VERSION ""

NS_ :

BS_:
BU_:

BO_ 858 DI_alertMatrix3: 8 Vector__XXX
   SG_ DI_a129_epbNotApplied : 0|1@1+ (1,0) [0|0] "" Vector__XXX
   SG_ DI_a130_aebFault : 1|1@1+ (1,0) [0|0] "" Vector__XXX
   SG_ DI_a131_highSpeedWearLimit : 2|1@1+ (1,0) [0|0] "" Vector__XXX
   SG_ DI_a133_capacitorOT : 4|1@1+ (1,0) [0|0] "" Vector__XXX
   SG_ DI_a134_wheelSpeedIrrational : 5|1@1+ (1,0) [0|0] "" Vector__XXX
   SG_ DI_a135_vehicleHoldFault : 6|1@1+ (1,0) [0|0] "" Vector__XXX
   SG_ DI_a136_spiError : 7|1@1+ (1,0) [0|0] "" Vector__XXX
   SG_ DI_a137_noCapableDriveUnits : 8|1@1+ (1,0) [0|0] "" Vector__XXX
   SG_ DI_a138_frontUnitDisabled : 9|1@1+ (1,0) [0|0] "" Vector__XXX
   SG_ DI_a139_rearUnitDisabled : 10|1@1+ (1,0) [0|0] "" Vector__XXX
   SG_ DI_a141_dasMIA : 12|1@1+ (1,0) [0|0] "" Vector__XXX
   SG_ DI_a142_highLashAngle : 13|1@1+ (1,0) [0|0] "" Vector__XXX
   SG_ DI_a143_mcuLimitActive : 14|1@1+ (1,0) [0|0] "" Vector__XXX
   SG_ DI_a144_configMismatch : 15|1@1+ (1,0) [0|0] "" Vector__XXX
   SG_ DI_a145_pbrkPanicSkid : 16|1@1+ (1,0) [0|0] "" Vector__XXX
   SG_ DI_a146_pbrkPanicEpbFault : 17|1@1+ (1,0) [0|0] "" Vector__XXX
   SG_ DI_a147_highTorqueWearLimit : 18|1@1+ (1,0) [0|0] "" Vector__XXX
   SG_ DI_a148_overtorqueUsed : 19|1@1+ (1,0) [0|0] "" Vector__XXX
   SG_ DI_a149_oilPumpFailure : 20|1@1+ (1,0) [0|0] "" Vector__XXX
   SG_ DI_a150_busVD : 21|1@1+ (1,0) [0|0] "" Vector__XXX
   SG_ DI_a151_shockTorqueLimiter : 22|1@1+ (1,0) [0|0] "" Vector__XXX
   SG_ DI_a152_linError : 23|1@1+ (1,0) [0|0] "" Vector__XXX
   SG_ DI_a153_oilPump : 24|1@1+ (1,0) [0|0] "" Vector__XXX
   SG_ DI_a154_resolver : 25|1@1+ (1,0) [0|0] "" Vector__XXX
   SG_ DI_a155_vcfrontMIA : 26|1@1+ (1,0) [0|0] "" Vector__XXX
   SG_ DI_a156_currentObserver : 27|1@1+ (1,0) [0|0] "" Vector__XXX
   SG_ DI_a157_rcmMIA : 28|1@1+ (1,0) [0|0] "" Vector__XXX
   SG_ DI_a158_ibstMIA : 29|1@1+ (1,0) [0|0] "" Vector__XXX
   SG_ DI_a159_cruiseSelfCheck : 30|1@1+ (1,0) [0|0] "" Vector__XXX
   SG_ DI_a160_busVoltageAnomaly : 31|1@1+ (1,0) [0|0] "" Vector__XXX
   SG_ DI_a161_epas3pMIA : 32|1@1+ (1,0) [0|0] "" Vector__XXX
   SG_ DI_a162_shiftDenied : 33|1@1+ (1,0) [0|0] "" Vector__XXX
   SG_ DI_a163_unparkReq : 34|1@1+ (1,0) [0|0] "" Vector__XXX
   SG_ DI_a164_brakeOverride : 35|1@1+ (1,0) [0|0] "" Vector__XXX
   SG_ DI_a165_cruiseCancelled : 36|1@1+ (1,0) [0|0] "" Vector__XXX
   SG_ DI_a166_driverLeft : 37|1@1+ (1,0) [0|0] "" Vector__XXX
   SG_ DI_a167_keyNotAuthenticated : 38|1@1+ (1,0) [0|0] "" Vector__XXX
   SG_ DI_a168_proximityDriveDenial : 39|1@1+ (1,0) [0|0] "" Vector__XXX
   SG_ DI_a169_regenOffOverride : 40|1@1+ (1,0) [0|0] "" Vector__XXX
   SG_ DI_a170_pedalFoul : 41|1@1+ (1,0) [0|0] "" Vector__XXX
   SG_ DI_a171_driveRailNotRequested : 42|1@1+ (1,0) [0|0] "" Vector__XXX
   SG_ DI_a172_accelPressedInNP : 43|1@1+ (1,0) [0|0] "" Vector__XXX
   SG_ DI_a173_bothPedalsPressed : 44|1@1+ (1,0) [0|0] "" Vector__XXX
   SG_ DI_a174_notOkToStartDrive : 45|1@1+ (1,0) [0|0] "" Vector__XXX
   SG_ DI_a175_crsNotAvailable : 46|1@1+ (1,0) [0|0] "" Vector__XXX
   SG_ DI_a176_EBRreleased : 47|1@1+ (1,0) [0|0] "" Vector__XXX
   SG_ DI_a177_tireFitmentChanged : 48|1@1+ (1,0) [0|0] "" Vector__XXX
   SG_ DI_a180_crsSeatbeltUnbuckled : 51|1@1+ (1,0) [0|0] "" Vector__XXX
   SG_ DI_a181_rearMotorMode : 52|1@1+ (1,0) [0|0] "" Vector__XXX
   SG_ DI_a182_frontMotorMode : 53|1@1+ (1,0) [0|0] "" Vector__XXX
   SG_ DI_a183_holdReleaseRqrd : 54|1@1+ (1,0) [0|0] "" Vector__XXX
   SG_ DI_a184_autoparkCanceled : 55|1@1+ (1,0) [0|0] "" Vector__XXX
   SG_ DI_a185_autoparkAborted : 56|1@1+ (1,0) [0|0] "" Vector__XXX
   SG_ DI_a186_brakeStand : 57|1@1+ (1,0) [0|0] "" Vector__XXX
   SG_ DI_a187_pedalMisapplication : 58|1@1+ (1,0) [0|0] "" Vector__XXX
   SG_ DI_a189_garageShiftWithPedal : 60|1@1+ (1,0) [0|0] "" Vector__XXX
   SG_ DI_a191_brakeShiftReq : 62|1@1+ (1,0) [0|0] "" Vector__XXX
   SG_ DI_a192_invalidOdometer : 63|1@1+ (1,0) [0|0] "" Vector__XXX

BO_ 859 DI_alertMatrix4: 8 Vector__XXX
   SG_ DI_a193_vdcEspBrakeTorqueFr : 0|1@1+ (1,0) [0|0] "" Vector__XXX
   SG_ DI_a194_vdcEspBrakeTorqueRe : 1|1@1+ (1,0) [0|0] "" Vector__XXX
   SG_ DI_a195_vdcEspSlipFr : 2|1@1+ (1,0) [0|0] "" Vector__XXX
   SG_ DI_a196_vdcEspSlipRe : 3|1@1+ (1,0) [0|0] "" Vector__XXX
   SG_ DI_a197_vdcEspWheelSaturations : 4|1@1+ (1,0) [0|0] "" Vector__XXX
   SG_ DI_a198_vdcEspMCPressAndSteering : 5|1@1+ (1,0) [0|0] "" Vector__XXX
   SG_ DI_a199_vdcFaulted : 6|1@1+ (1,0) [0|0] "" Vector__XXX
   SG_ DI_a200_vdcModelBasedPlausibility : 7|1@1+ (1,0) [0|0] "" Vector__XXX
   SG_ DI_a201_regenLimited : 8|1@1+ (1,0) [0|0] "" Vector__XXX
   SG_ DI_a202_excessHeatUnavailable : 9|1@1+ (1,0) [0|0] "" Vector__XXX
   SG_ DI_a203_TCReducedByADD : 10|1@1+ (1,0) [0|0] "" Vector__XXX
   SG_ DI_a204_vdcRcmLongitudinal : 11|1@1+ (1,0) [0|0] "" Vector__XXX
   SG_ DI_a205_vdcRcmLateral : 12|1@1+ (1,0) [0|0] "" Vector__XXX
   SG_ DI_a206_vdcRcmVertical : 13|1@1+ (1,0) [0|0] "" Vector__XXX
   SG_ DI_a207_vdcPowertrainTorqueFr : 14|1@1+ (1,0) [0|0] "" Vector__XXX
   SG_ DI_a208_vdcPowertrainTorqueRe : 15|1@1+ (1,0) [0|0] "" Vector__XXX
   SG_ DI_a209_vdcVehicleSpeed : 16|1@1+ (1,0) [0|0] "" Vector__XXX
   SG_ DI_a210_vdcOtherControllerStates : 17|1@1+ (1,0) [0|0] "" Vector__XXX
   SG_ DI_a211_vdcMotorSpeeds : 18|1@1+ (1,0) [0|0] "" Vector__XXX
   SG_ DI_a212_velEstWheelSpeedCGFr : 19|1@1+ (1,0) [0|0] "" Vector__XXX
   SG_ DI_a213_velEstWheelSpeedCGRe : 20|1@1+ (1,0) [0|0] "" Vector__XXX
   SG_ DI_a214_velEstWheelSpeedNonCGFr : 21|1@1+ (1,0) [0|0] "" Vector__XXX
   SG_ DI_a215_velEstWheelSpeedNonCGRe : 22|1@1+ (1,0) [0|0] "" Vector__XXX
   SG_ DI_a216_vdcMBPAlmostTripped : 23|1@1+ (1,0) [0|0] "" Vector__XXX
   SG_ DI_a217_vdcOutputIrrational : 24|1@1+ (1,0) [0|0] "" Vector__XXX
   SG_ DI_a218_vdcOSPreControlActive : 25|1@1+ (1,0) [0|0] "" Vector__XXX
   SG_ DI_a219_vdcOversteerdMzActive : 26|1@1+ (1,0) [0|0] "" Vector__XXX
   SG_ DI_a220_vdcUndersteerDecelActive : 27|1@1+ (1,0) [0|0] "" Vector__XXX
   SG_ DI_a221_vdcUndersteerdMzActive : 28|1@1+ (1,0) [0|0] "" Vector__XXX
   SG_ DI_a222_vdcDisabled : 29|1@1+ (1,0) [0|0] "" Vector__XXX
   SG_ DI_a223_tractionControlDisabled : 30|1@1+ (1,0) [0|0] "" Vector__XXX
   SG_ DI_a224_brakeOverTemp : 31|1@1+ (1,0) [0|0] "" Vector__XXX
   SG_ DI_a225_tmpEstPlausibility : 32|1@1+ (1,0) [0|0] "" Vector__XXX
   SG_ DI_a226_sysStartConditionNotMet : 33|1@1+ (1,0) [0|0] "" Vector__XXX
   SG_ DI_a227_contactorsNotClosed : 34|1@1+ (1,0) [0|0] "" Vector__XXX
   SG_ DI_a228_brakeTempEstUnavailable : 35|1@1+ (1,0) [0|0] "" Vector__XXX
   SG_ DI_a229_batteryIsHeating : 36|1@1+ (1,0) [0|0] "" Vector__XXX
   SG_ DI_a230_cmpMIA : 37|1@1+ (1,0) [0|0] "" Vector__XXX
   SG_ DI_a231_ptcMIA : 38|1@1+ (1,0) [0|0] "" Vector__XXX
   SG_ DI_a232_velocityEstimatorDegraded : 39|1@1+ (1,0) [0|0] "" Vector__XXX
   SG_ DI_a233_diMsgMissed : 40|1@1+ (1,0) [0|0] "" Vector__XXX
   SG_ DI_a234_pcsMIA : 41|1@1+ (1,0) [0|0] "" Vector__XXX
   SG_ DI_a235_trackModeActive : 42|1@1+ (1,0) [0|0] "" Vector__XXX
   SG_ DI_a238_brakeOverTempBrembo : 45|1@1+ (1,0) [0|0] "" Vector__XXX
   SG_ DI_a239_neutralRequestByPM : 46|1@1+ (1,0) [0|0] "" Vector__XXX
   SG_ DI_a241_systemThermallyLimited : 48|1@1+ (1,0) [0|0] "" Vector__XXX

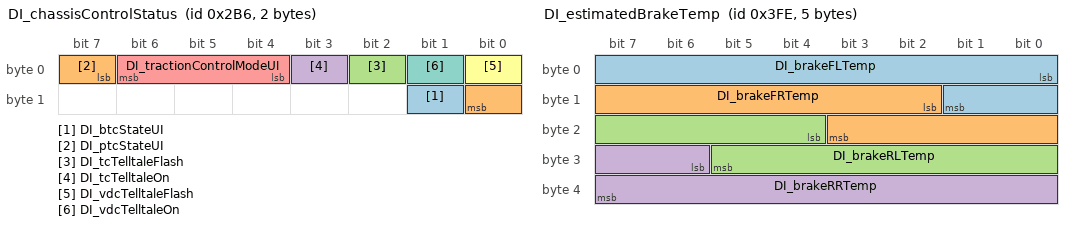
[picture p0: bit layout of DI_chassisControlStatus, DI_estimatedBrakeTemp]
BO_ 694 DI_chassisControlStatus: 2 Vector__XXX
   SG_ DI_btcStateUI : 9|1@1+ (1,0) [0|0] "" Vector__XXX
   SG_ DI_ptcStateUI : 7|2@1+ (1,0) [0|0] "" Vector__XXX
   SG_ DI_tcTelltaleFlash : 2|1@1+ (1,0) [0|0] "" Vector__XXX
   SG_ DI_tcTelltaleOn : 3|1@1+ (1,0) [0|0] "" Vector__XXX
   SG_ DI_tractionControlModeUI : 4|3@1+ (1,0) [0|0] "" Vector__XXX
   SG_ DI_vdcTelltaleFlash : 0|1@1+ (1,0) [0|0] "" Vector__XXX
   SG_ DI_vdcTelltaleOn : 1|1@1+ (1,0) [0|0] "" Vector__XXX

BO_ 1879 DI_debug: 8 Vector__XXX
   SG_ DI_debugSelector M : 0|8@1+ (1,0) [0|0] "" Vector__XXX
   SG_ DI_motorType m128 : 8|5@1+ (1,0) [0|0] "" Vector__XXX
   SG_ DI_cpu1HzMin m128 : 16|8@1+ (0.4,0) [0|0] "%" Vector__XXX
   SG_ DI_cpu1HzMax m128 : 24|8@1+ (0.4,0) [0|0] "%" Vector__XXX
   SG_ DI_cpu1HzAvg m128 : 32|8@1+ (0.4,0) [0|0] "%" Vector__XXX
   SG_ DI_muSurfHigh m2 : 8|8@1+ (0.005,0) [0|0] "N/N" Vector__XXX
   SG_ DI_brakeCpScale m2 : 16|9@1- (0.01,0.5) [0|0] "N/N" Vector__XXX
   SG_ DI_pedalPosFilt m2 : 32|8@1+ (0.4,0) [0|0] "%" Vector__XXX
   SG_ DI_cpuIDWord0 m131 : 16|16@1+ (1,0) [0|0] "" Vector__XXX
   SG_ DI_crc m131 : 32|32@1+ (1,0) [0|0] "" Vector__XXX
   SG_ DI_cpuIDWord1 m132 : 16|16@1+ (1,0) [0|0] "" Vector__XXX
   SG_ DI_cpuIDWord2 m132 : 32|16@1+ (1,0) [0|0] "" Vector__XXX
   SG_ DI_cpuIDWord3 m132 : 48|16@1+ (1,0) [0|0] "" Vector__XXX
   SG_ DI_offsetA m32 : 8|8@1- (0.1,0) [0|0] "A" Vector__XXX
   SG_ DI_motorIA m32 : 16|16@1+ (0.1,0) [0|0] "A" Vector__XXX
   SG_ DI_motorIB m32 : 32|16@1+ (0.1,0) [0|0] "A" Vector__XXX
   SG_ DI_motorIC m32 : 48|16@1+ (0.1,0) [0|0] "A" Vector__XXX
   SG_ DI_offsetB m33 : 8|8@1- (0.1,0) [0|0] "A" Vector__XXX
   SG_ DI_statorIDref m33 : 16|16@1- (0.1,0) [0|0] "A" Vector__XXX
   SG_ DI_statorIDfdb m33 : 32|16@1- (0.1,0) [0|0] "A" Vector__XXX
   SG_ DI_torquePerAmp m33 : 48|16@1+ (0.0001,0) [0|0] "Nm/A" Vector__XXX
   SG_ DI_rsScale m34 : 8|8@1+ (0.01,0) [0|0] "scale" Vector__XXX
   SG_ DI_statorIQref m34 : 16|16@1- (0.1,0) [0|0] "A" Vector__XXX
   SG_ DI_statorIQfdb m34 : 32|16@1- (0.1,0) [0|0] "A" Vector__XXX
   SG_ DI_motorV m34 : 48|16@1+ (2e-05,0) [0|0] "mindex" Vector__XXX
   SG_ DI_tqScaleDifferential m35 : 8|8@1+ (0.4,0) [0|0] "%" Vector__XXX
   SG_ DI_statorFluxRef m35 : 16|16@1+ (0.0001,0) [0|0] "Wb" Vector__XXX
   SG_ DI_statorFluxFdb m35 : 32|16@1+ (0.0001,0) [0|0] "Wb" Vector__XXX
   SG_ DI_systemTorqueCommand m35 : 48|16@1- (0.035,0) [0|0] "Nm" Vector__XXX
   SG_ DI_lmScale m36 : 8|8@1+ (0.004,0) [0|0] "scale" Vector__XXX
   SG_ DI_statorVQ m36 : 16|16@1- (4e-05,0) [0|0] "mindex" Vector__XXX
   SG_ DI_statorVD m36 : 32|16@1- (4e-05,0) [0|0] "mindex" Vector__XXX
   SG_ DI_peakFlux m36 : 48|16@1+ (0.0001,0) [0|0] "Wb" Vector__XXX
   SG_ DI_gainScale m37 : 8|8@1+ (0.01,0) [0|0] "scale" Vector__XXX
   SG_ DI_dcCableCurrentEst m37 : 16|16@1- (0.1,0) [0|0] "A" Vector__XXX
   SG_ DI_loadAngleMargin m37 : 32|16@1- (0.0003,0) [0|0] "rad" Vector__XXX
   SG_ DI_internalAngleFilt m37 : 48|16@1+ (0.0003,0) [0|0] "rad" Vector__XXX
   SG_ DI_ssmState m38 : 8|4@1+ (1,0) [0|0] "" Vector__XXX
   SG_ DI_usmState m38 : 12|3@1+ (1,0) [0|0] "" Vector__XXX
   SG_ DI_peakIQref m38 : 16|16@1+ (0.1,0) [0|0] "A" Vector__XXX
   SG_ DI_motorIAavg m38 : 32|16@1- (0.1,0) [0|0] "A" Vector__XXX
   SG_ DI_motorIBavg m38 : 48|16@1- (0.1,0) [0|0] "A" Vector__XXX
   SG_ DI_tqSatThermal m39 : 8|8@1+ (0.4,0) [0|0] "%" Vector__XXX
   SG_ DI_pwrSatMaxDischargePower m39 : 16|8@1+ (0.4,0) [0|0] "%" Vector__XXX
   SG_ DI_pwrSatMaxRegenPower m39 : 24|8@1+ (0.4,0) [0|0] "%" Vector__XXX
   SG_ DI_tqSatMotorVoltage m39 : 32|8@1+ (0.4,0) [0|0] "%" Vector__XXX
   SG_ DI_tqSatMotorCurrent m39 : 40|8@1+ (0.4,0) [0|0] "%" Vector__XXX
   SG_ DI_pwrSatMaxBusVoltage m39 : 48|8@1+ (0.4,0) [0|0] "%" Vector__XXX
   SG_ DI_pwrSatMinBusVoltage m39 : 56|8@1+ (0.4,0) [0|0] "%" Vector__XXX
   SG_ DI_pwrSatDischargeCurrent m40 : 8|8@1+ (0.4,0) [0|0] "%" Vector__XXX
   SG_ DI_tcMaxRequest m40 : 16|8@1+ (5,0) [0|0] "Nm" Vector__XXX
   SG_ DI_tcMinRequest m40 : 24|8@1+ (5,0) [0|0] "Nm" Vector__XXX
   SG_ DI_tqSatUiDriveTorque m40 : 32|8@1+ (0.4,0) [0|0] "%" Vector__XXX
   SG_ DI_tqSatUiRegenTorque m40 : 40|8@1+ (0.4,0) [0|0] "%" Vector__XXX
   SG_ DI_tqScaleMaxMotorSpeed m40 : 48|8@1+ (0.4,0) [0|0] "%" Vector__XXX
   SG_ DI_tqScaleShift m40 : 56|8@1+ (0.4,0) [0|0] "%" Vector__XXX
   SG_ DI_veMassInvRaw m41 : 8|12@1+ (1e-07,0.0001) [0|0] "1/kg" Vector__XXX
   SG_ DI_veResForce m41 : 20|12@1- (0.0005,0) [0|0] "G" Vector__XXX
   SG_ DI_currentLimit m41 : 32|16@1+ (0.1,0) [0|0] "A" Vector__XXX
   SG_ DI_wasteCurrentLimit m41 : 48|16@1+ (0.1,0) [0|0] "A" Vector__XXX
   SG_ DI_pwrSatChargeCurrent m42 : 8|8@1+ (0.4,0) [0|0] "%" Vector__XXX
   SG_ DI_fluxState m42 : 16|4@1+ (1,0) [0|0] "" Vector__XXX
   SG_ DI_llsScale m42 : 24|8@1+ (0.004,0) [0|0] "scale" Vector__XXX
   SG_ DI_llrScale m42 : 32|8@1+ (0.015,0) [0|0] "scale" Vector__XXX
   SG_ DI_loadAngle m42 : 40|16@1- (0.0003,0) [0|0] "rad" Vector__XXX
   SG_ DI_brakeSwitchNO m42 : 62|1@1+ (1,0) [0|0] "" Vector__XXX
   SG_ DI_brakeSwitchNC m42 : 63|1@1+ (1,0) [0|0] "" Vector__XXX
   SG_ DI_sysPedalMinTorque m44 : 8|14@1+ (0.1,-1638.3) [0|0] "Nm" Vector__XXX
   SG_ DI_sysPedalMaxTorque m44 : 22|14@1+ (0.1,0) [0|0] "Nm" Vector__XXX
   SG_ DI_sysPostPedalMinTorque m44 : 36|14@1+ (0.1,-1638.3) [0|0] "Nm" Vector__XXX
   SG_ DI_sysPostPedalMaxTorque m44 : 50|14@1+ (0.1,0) [0|0] "Nm" Vector__XXX
   SG_ DI_aebFaultReason m45 : 16|4@1+ (1,0) [0|0] "" Vector__XXX
   SG_ DI_aebUnavailableReason m45 : 24|4@1+ (1,0) [0|0] "" Vector__XXX
   SG_ DI_aebCancelReason m45 : 32|8@1+ (1,0) [0|0] "" Vector__XXX
   SG_ DI_oilPumpPhaseCurrent m46 : 8|8@1+ (0.1,0) [0|0] "A" Vector__XXX
   SG_ DI_oilPumpPhaseVoltage m46 : 16|8@1+ (0.1,0) [0|0] "V" Vector__XXX
   SG_ DI_oilPumpPhaseAdvance m46 : 24|8@1+ (0.4,0) [0|0] "%" Vector__XXX
   SG_ DI_oilPumpPressureEstimate m46 : 32|8@1+ (2,0) [0|0] "kPa" Vector__XXX
   SG_ DI_rotorFlux m47 : 16|16@1+ (0.0001,0) [0|0] "Wb" Vector__XXX
   SG_ DI_dcCableHeat m47 : 32|16@1+ (0.001,0) [0|0] "kA2s" Vector__XXX
   SG_ DI_magnetTempEst m47 : 48|8@1+ (1,-40) [0|0] "DegC" Vector__XXX
   SG_ DI_magnetTempEst_SFO m47 : 56|8@1+ (1,-40) [0|0] "DegC" Vector__XXX
   SG_ DI_resolverOffsetCos m48 : 8|8@1+ (0.015,0) [0|0] "V" Vector__XXX
   SG_ DI_resolverOffsetSin m48 : 16|8@1+ (0.015,0) [0|0] "V" Vector__XXX
   SG_ DI_resolverPhaseOffset m48 : 24|8@1+ (0.1,7.5) [0|0] "us" Vector__XXX
   SG_ DI_resolverCommonGain m48 : 32|8@1+ (0.025,0) [0|0] "1" Vector__XXX
   SG_ DI_resolverReady m48 : 40|1@1+ (1,0) [0|0] "" Vector__XXX
   SG_ DI_resolverNoCarrier m48 : 41|1@1+ (1,0) [0|0] "" Vector__XXX
   SG_ DI_resolverNoPhaseLock m48 : 42|1@1+ (1,0) [0|0] "" Vector__XXX
   SG_ DI_resolverClaMIA m48 : 43|1@1+ (1,0) [0|0] "" Vector__XXX
   SG_ DI_soptTimeToTrip m49 : 8|8@1+ (0.05,0) [0|0] "ms" Vector__XXX
   SG_ DI_soptTripDelay m49 : 16|8@1+ (0.05,0) [0|0] "ms" Vector__XXX
   SG_ DI_soptTimeToOff m49 : 24|11@1+ (0.05,0) [0|0] "ms" Vector__XXX
   SG_ DI_soptMaxCurrentMagSqrd m49 : 40|16@1+ (100,0) [0|0] "A2" Vector__XXX
   SG_ DI_gateDriveSupplyState m50 : 8|2@1+ (1,0) [0|0] "" Vector__XXX
   SG_ DI_gateDriveState m50 : 10|3@1+ (1,0) [0|0] "" Vector__XXX
   SG_ DI_powerStageSafeState m50 : 13|2@1+ (1,0) [0|0] "" Vector__XXX
   SG_ DI_sysHeatPowerOptimal m50 : 16|8@1+ (0.08,0) [0|0] "kW" Vector__XXX
   SG_ DI_brkStState m50 : 24|3@1+ (1,0) [0|0] "" Vector__XXX
   SG_ DI_torquePedalMin m51 : 16|12@1+ (2,-7500) [0|0] "Nm" Vector__XXX
   SG_ DI_torquePedalMax m51 : 28|12@1+ (2,0) [0|0] "Nm" Vector__XXX
   SG_ DI_torquePostPedalMin m51 : 40|12@1+ (2,-7500) [0|0] "Nm" Vector__XXX
   SG_ DI_torquePostPedalMax m51 : 52|12@1+ (2,0) [0|0] "Nm" Vector__XXX
   SG_ DI_dcCapTemp m64 : 8|8@1+ (1,-40) [0|0] "DegC" Vector__XXX
   SG_ DI_busbarTemp m64 : 16|8@1+ (1,-40) [0|0] "DegC" Vector__XXX
   SG_ DI_pcsTemp m64 : 24|8@1+ (1,-40) [0|0] "DegC" Vector__XXX
   SG_ DI_statorTemp1 m64 : 32|8@1+ (1,-40) [0|0] "DegC" Vector__XXX
   SG_ DI_statorTemp2 m64 : 40|8@1+ (1,-40) [0|0] "DegC" Vector__XXX
   SG_ DI_immobilizerCondition m64 : 63|1@1+ (1,0) [0|0] "" Vector__XXX
   SG_ DI_velocityEstimatorState m65 : 8|3@1+ (1,0) [0|0] "" Vector__XXX
   SG_ DI_hvilCurrent m65 : 16|10@1+ (0.025,0) [0|0] "mA" Vector__XXX
   SG_ DI_hvilCmVoltage m65 : 32|10@1+ (0.02,0) [0|0] "V" Vector__XXX
   SG_ DI_cpu10HzMin m66 : 8|8@1+ (0.4,0) [0|0] "%" Vector__XXX
   SG_ DI_cpu10HzMax m66 : 16|8@1+ (0.4,0) [0|0] "%" Vector__XXX
   SG_ DI_cpu10HzAvg m66 : 24|8@1+ (0.4,0) [0|0] "%" Vector__XXX
   SG_ DI_cpu100HzMin m66 : 32|8@1+ (0.4,0) [0|0] "%" Vector__XXX
   SG_ DI_cpu100HzMax m66 : 40|8@1+ (0.4,0) [0|0] "%" Vector__XXX
   SG_ DI_cpu100HzAvg m66 : 48|8@1+ (0.4,0) [0|0] "%" Vector__XXX
   SG_ DI_module10HzStack m66 : 56|8@1+ (0.4,0) [0|0] "%" Vector__XXX
   SG_ DI_cpu1kHzMin m67 : 8|8@1+ (0.4,0) [0|0] "%" Vector__XXX
   SG_ DI_cpu1kHzMax m67 : 16|8@1+ (0.4,0) [0|0] "%" Vector__XXX
   SG_ DI_cpu1kHzAvg m67 : 24|8@1+ (0.4,0) [0|0] "%" Vector__XXX
   SG_ DI_cpu20kHzMin m67 : 32|8@1+ (0.4,0) [0|0] "%" Vector__XXX
   SG_ DI_cpu20kHzMax m67 : 40|8@1+ (0.4,0) [0|0] "%" Vector__XXX
   SG_ DI_cpu20kHzAvg m67 : 48|8@1+ (0.4,0) [0|0] "%" Vector__XXX
   SG_ DI_controlStack m67 : 56|8@1+ (0.4,0) [0|0] "%" Vector__XXX
   SG_ DI_systemStack m68 : 8|8@1+ (0.4,0) [0|0] "%" Vector__XXX
   SG_ DI_idleStack m68 : 16|8@1+ (0.4,0) [0|0] "%" Vector__XXX
   SG_ DI_decodeHardwareStack m68 : 24|8@1+ (0.4,0) [0|0] "%" Vector__XXX
   SG_ DI_eepromStack m68 : 32|8@1+ (0.4,0) [0|0] "%" Vector__XXX
   SG_ DI_udsStack m68 : 40|8@1+ (0.4,0) [0|0] "%" Vector__XXX
   SG_ DI_xcpStack m68 : 48|8@1+ (0.4,0) [0|0] "%" Vector__XXX
   SG_ DI_immobilizerStack m68 : 56|8@1+ (0.4,0) [0|0] "%" Vector__XXX
   SG_ DI_hwFaultCounter m69 : 8|4@1+ (1,0) [0|0] "" Vector__XXX
   SG_ DI_driveUnitOdometer m69 : 32|32@1+ (10,0) [0|0] "rev" Vector__XXX
   SG_ DI_phaseOutBusbarTemp m70 : 8|8@1+ (1,-40) [0|0] "DegC" Vector__XXX
   SG_ DI_phaseOutBusbarWeldTemp m70 : 16|8@1+ (1,-40) [0|0] "DegC" Vector__XXX
   SG_ DI_phaseOutLugTemp m70 : 24|8@1+ (1,-40) [0|0] "DegC" Vector__XXX
   SG_ DI_dcLinkCapTemp m70 : 32|8@1+ (1,-40) [0|0] "DegC" Vector__XXX
   SG_ DI_hvDcCableTemp m70 : 40|8@1+ (1,-40) [0|0] "DegC" Vector__XXX
   SG_ DI_negDcBusbarTemp m70 : 48|8@1+ (1,-40) [0|0] "DegC" Vector__XXX
   SG_ DI_posDcBusbarTemp m70 : 56|8@1+ (1,-40) [0|0] "DegC" Vector__XXX
   SG_ DI_statorEndWindingTemp m72 : 8|8@1+ (1,-40) [0|0] "DegC" Vector__XXX
   SG_ DI_rotorMaxMagnetTemp m72 : 16|8@1+ (1,-40) [0|0] "DegC" Vector__XXX

BO_ 1880 DI_dyno: 8 Vector__XXX
   SG_ DI_dynoSelector M : 0|8@1+ (1,0) [0|0] "" Vector__XXX
   SG_ DI_Isx m0 : 16|16@1+ (1.5259e-05,0) [0|0] "A" Vector__XXX
   SG_ DI_Isy m0 : 32|16@1+ (1.5259e-05,0) [0|0] "A" Vector__XXX
   SG_ DI_IsMag m0 : 48|16@1- (0.1,0) [0|0] "A" Vector__XXX
   SG_ DI_Vsx m1 : 16|16@1- (4e-05,0) [0|0] "mindex" Vector__XXX
   SG_ DI_Vsy m1 : 32|16@1- (4e-05,0) [0|0] "mindex" Vector__XXX
   SG_ DI_voltageForFlux m1 : 48|16@1+ (0.00762951,0) [0|0] "V" Vector__XXX
   SG_ DI_torqueMotor m2 : 16|13@1- (0.25,0) [0|0] "Nm" Vector__XXX
   SG_ DI_state m2 : 29|3@1+ (1,0) [0|0] "" Vector__XXX
   SG_ DI_motorRPM m2 : 32|16@1- (1,0) [0|0] "RPM" Vector__XXX
   SG_ DI_torqueEstimate m2 : 48|13@1- (0.25,0) [0|0] "Nm" Vector__XXX
   SG_ DI_pedalMinTorque m32 : 8|12@1+ (0.25,-750) [0|0] "Nm" Vector__XXX
   SG_ DI_pedalMaxTorque m32 : 20|12@1+ (0.25,0) [0|0] "Nm" Vector__XXX
   SG_ DI_postPedalMinTorque m32 : 32|12@1+ (0.25,-750) [0|0] "Nm" Vector__XXX
   SG_ DI_postPedalMaxTorque m32 : 44|12@1+ (0.25,0) [0|0] "Nm" Vector__XXX
   SG_ DI_slipEstimate m33 : 8|10@1- (0.02,0) [0|0] "Hz" Vector__XXX
   SG_ DI_mechToElcFactor m64 : 8|4@1- (1,0) [0|0] "" Vector__XXX

BO_ 1022 DI_estimatedBrakeTemp: 5 Vector__XXX
   SG_ DI_brakeFLTemp : 0|10@1+ (1,-40) [0|0] "DegC" Vector__XXX
   SG_ DI_brakeFRTemp : 10|10@1+ (1,-40) [0|0] "DegC" Vector__XXX
   SG_ DI_brakeRLTemp : 20|10@1+ (1,-40) [0|0] "DegC" Vector__XXX
   SG_ DI_brakeRRTemp : 30|10@1+ (1,-40) [0|0] "DegC" Vector__XXX

BO_ 1622 DI_info: 8 Vector__XXX
   SG_ DI_infoIndex M : 0|8@1+ (1,0) [0|0] "" Vector__XXX
   SG_ DI_buildType m10 : 8|3@1+ (1,0) [0|0] "" Vector__XXX
   SG_ DI_buildConfigurationId m10 : 16|16@1+ (1,0) [0|0] "" Vector__XXX
   SG_ DI_hardwareId m10 : 32|8@1+ (1,0) [0|0] "" Vector__XXX
   SG_ DI_componentId m10 : 48|16@1+ (1,0) [0|0] "" Vector__XXX
   SG_ DI_pcbaId m11 : 16|8@1+ (1,0) [0|0] "" Vector__XXX
   SG_ DI_assemblyId m11 : 24|8@1+ (1,0) [0|0] "" Vector__XXX
   SG_ DI_usageId m11 : 32|16@1+ (1,0) [0|0] "" Vector__XXX
   SG_ DI_subUsageId m11 : 48|16@1+ (1,0) [0|0] "" Vector__XXX
   SG_ DI_applicationSvnRevision m12 : 8|24@1+ (1,0) [0|0] "" Vector__XXX
   SG_ DI_applicationSvnUrlHash m12 : 32|32@1+ (1,0) [0|0] "" Vector__XXX
   SG_ DI_applicationCrc m13 : 32|32@1+ (1,0) [0|0] "" Vector__XXX
   SG_ DI_bootloaderSvnRevision m14 : 8|24@1+ (1,0) [0|0] "" Vector__XXX
   SG_ DI_bootloaderSvnUrlHash m14 : 32|32@1+ (1,0) [0|0] "" Vector__XXX
   SG_ DI_oilPumpBuildType m16 : 8|3@1+ (1,0) [0|0] "" Vector__XXX
   SG_ DI_oilPumpAppCrc m16 : 16|32@1+ (1,0) [0|0] "" Vector__XXX
   SG_ DI_appGitHash m17 : 10|54@1+ (4,0) [0|0] "" Vector__XXX
   SG_ DI_bootGitHash m18 : 10|54@1+ (4,0) [0|0] "" Vector__XXX
   SG_ DI_platformTyp m19 : 8|8@1+ (1,0) [0|0] "" Vector__XXX
   SG_ DI_infoBootLdUdsProtocolVersion m20 : 8|8@1+ (1,0) [0|0] "" Vector__XXX
   SG_ DI_bootloaderCrc m20 : 32|32@1+ (1,0) [0|0] "" Vector__XXX
   SG_ DI_subcomponentGitHash m31 : 10|54@1+ (4,0) [0|0] "" Vector__XXX

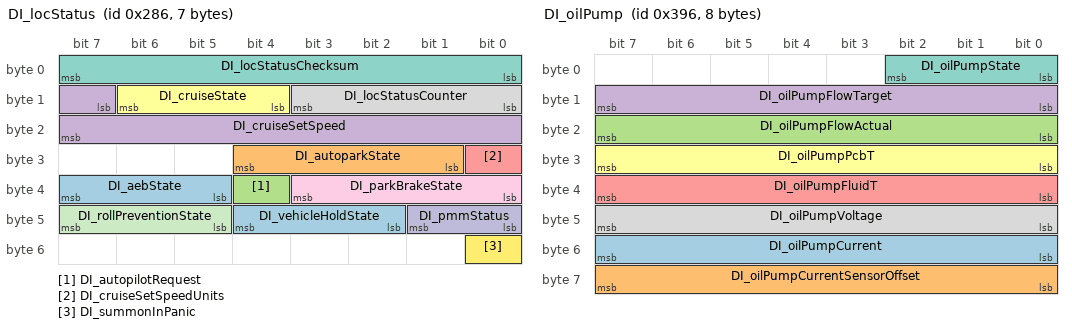
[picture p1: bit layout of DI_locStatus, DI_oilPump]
BO_ 646 DI_locStatus: 7 Vector__XXX
   SG_ DI_aebState : 37|3@1+ (1,0) [0|0] "" Vector__XXX
   SG_ DI_autoparkState : 25|4@1+ (1,0) [0|0] "" Vector__XXX
   SG_ DI_autopilotRequest : 36|1@1+ (1,0) [0|0] "" Vector__XXX
   SG_ DI_cruiseSetSpeed : 15|9@1+ (0.5,0) [0|0] "speed" Vector__XXX
   SG_ DI_cruiseSetSpeedUnits : 24|1@1+ (1,0) [0|0] "" Vector__XXX
   SG_ DI_cruiseState : 12|3@1+ (1,0) [0|0] "" Vector__XXX
   SG_ DI_locStatusChecksum : 0|8@1+ (1,0) [0|0] "" Vector__XXX
   SG_ DI_locStatusCounter : 8|4@1+ (1,0) [0|0] "" Vector__XXX
   SG_ DI_parkBrakeState : 32|4@1+ (1,0) [0|0] "" Vector__XXX
   SG_ DI_pmmStatus : 40|2@1+ (1,0) [0|0] "" Vector__XXX
   SG_ DI_rollPreventionState : 45|3@1+ (1,0) [0|0] "" Vector__XXX
   SG_ DI_summonInPanic : 48|1@1+ (1,0) [0|0] "" Vector__XXX
   SG_ DI_vehicleHoldState : 42|3@1+ (1,0) [0|0] "" Vector__XXX

BO_ 822 DI_maxRatedPower: 3 Vector__XXX
   SG_ DI_sysDrivePowerRated : 0|9@1+ (1,0) [0|0] "kW" Vector__XXX
   SG_ DI_sysRegenPowerRated : 16|8@1+ (1,-100) [0|0] "kW" Vector__XXX

BO_ 950 DI_odometerStatus: 4 Vector__XXX
   SG_ DI_odometer : 0|32@1+ (0.001,0) [0|0] "km" Vector__XXX

BO_ 918 DI_oilPump: 8 Vector__XXX
   SG_ DI_oilPumpCurrent : 48|8@1+ (0.1,0) [0|0] "A" Vector__XXX
   SG_ DI_oilPumpCurrentSensorOffset : 56|8@1+ (0.005,0) [0|0] "A" Vector__XXX
   SG_ DI_oilPumpFlowActual : 16|8@1+ (0.06,0) [0|0] "LPM" Vector__XXX
   SG_ DI_oilPumpFlowTarget : 8|8@1+ (0.06,0) [0|0] "LPM" Vector__XXX
   SG_ DI_oilPumpFluidT : 32|8@1+ (1,-40) [0|0] "DegC" Vector__XXX
   SG_ DI_oilPumpPcbT : 24|8@1+ (1,-40) [0|0] "DegC" Vector__XXX
   SG_ DI_oilPumpState : 0|3@1+ (1,0) [0|0] "" Vector__XXX
   SG_ DI_oilPumpVoltage : 40|8@1+ (0.1,0) [0|0] "V" Vector__XXX

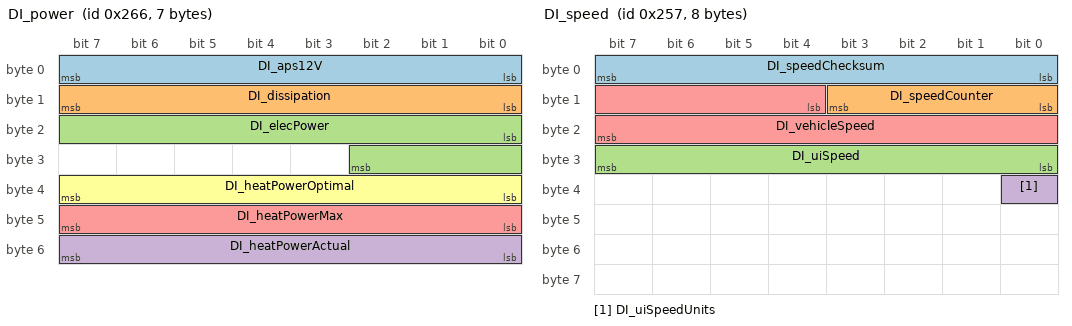
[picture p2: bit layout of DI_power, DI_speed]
BO_ 614 DI_power: 7 Vector__XXX
   SG_ DI_aps12V : 0|8@1+ (0.1,0) [0|0] "V" Vector__XXX
   SG_ DI_dissipation : 8|8@1+ (125,0) [0|0] "W" Vector__XXX
   SG_ DI_elecPower : 16|11@1- (0.5,0) [0|0] "kW" Vector__XXX
   SG_ DI_heatPowerActual : 48|8@1+ (0.08,0) [0|0] "kW" Vector__XXX
   SG_ DI_heatPowerMax : 40|8@1+ (0.08,0) [0|0] "kW" Vector__XXX
   SG_ DI_heatPowerOptimal : 32|8@1+ (0.08,0) [0|0] "kW" Vector__XXX

BO_ 599 DI_speed: 8 Vector__XXX
   SG_ DI_speedChecksum : 0|8@1+ (1,0) [0|0] "" Vector__XXX
   SG_ DI_speedCounter : 8|4@1+ (1,0) [0|0] "" Vector__XXX
   SG_ DI_uiSpeed : 24|8@1+ (1,0) [0|0] "" Vector__XXX
   SG_ DI_uiSpeedUnits : 32|1@1+ (1,0) [0|0] "" Vector__XXX
   SG_ DI_vehicleSpeed : 12|12@1+ (0.08,-40) [0|0] "kph" Vector__XXX

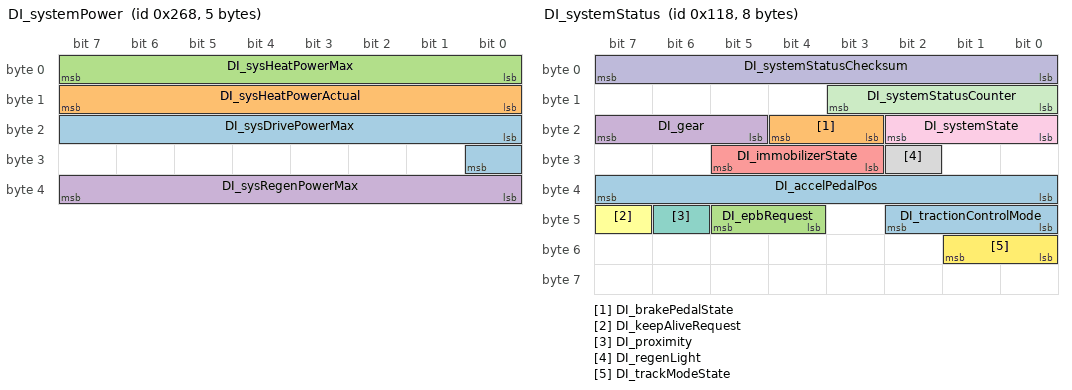
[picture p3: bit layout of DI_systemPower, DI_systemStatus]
BO_ 616 DI_systemPower: 5 Vector__XXX
   SG_ DI_sysDrivePowerMax : 16|9@1+ (1,0) [0|0] "kW" Vector__XXX
   SG_ DI_sysHeatPowerActual : 8|8@1+ (0.08,0) [0|0] "kW" Vector__XXX
   SG_ DI_sysHeatPowerMax : 0|8@1+ (0.08,0) [0|0] "kW" Vector__XXX
   SG_ DI_sysRegenPowerMax : 32|8@1+ (1,-100) [0|0] "kW" Vector__XXX

BO_ 280 DI_systemStatus: 8 Vector__XXX
   SG_ DI_accelPedalPos : 32|8@1+ (0.4,0) [0|0] "%" Vector__XXX
   SG_ DI_brakePedalState : 19|2@1+ (1,0) [0|0] "" Vector__XXX
   SG_ DI_epbRequest : 44|2@1+ (1,0) [0|0] "" Vector__XXX
   SG_ DI_gear : 21|3@1+ (1,0) [0|0] "" Vector__XXX
   SG_ DI_immobilizerState : 27|3@1+ (1,0) [0|0] "" Vector__XXX
   SG_ DI_keepAliveRequest : 47|1@1+ (1,0) [0|0] "" Vector__XXX
   SG_ DI_proximity : 46|1@1+ (1,0) [0|0] "" Vector__XXX
   SG_ DI_regenLight : 26|1@1+ (1,0) [0|0] "" Vector__XXX
   SG_ DI_systemState : 16|3@1+ (1,0) [0|0] "" Vector__XXX
   SG_ DI_systemStatusChecksum : 0|8@1+ (1,0) [0|0] "" Vector__XXX
   SG_ DI_systemStatusCounter : 8|4@1+ (1,0) [0|0] "" Vector__XXX
   SG_ DI_trackModeState : 48|2@1+ (1,0) [0|0] "" Vector__XXX
   SG_ DI_tractionControlMode : 40|3@1+ (1,0) [0|0] "" Vector__XXX

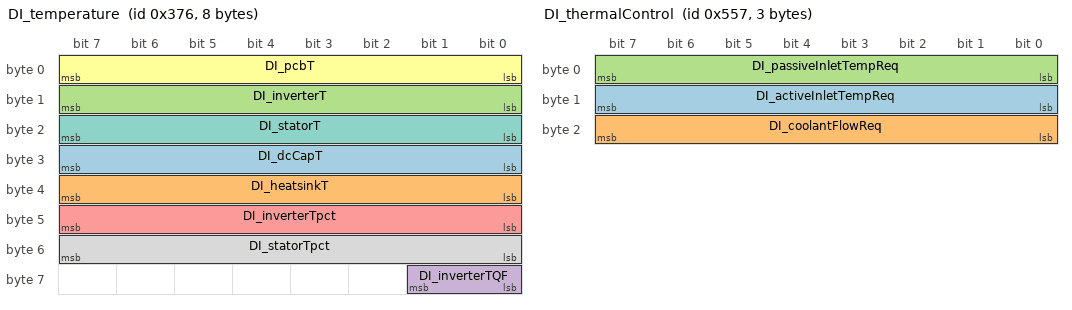
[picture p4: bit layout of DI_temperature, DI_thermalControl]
BO_ 886 DI_temperature: 8 Vector__XXX
   SG_ DI_dcCapT : 24|8@1+ (1,-40) [0|0] "DegC" Vector__XXX
   SG_ DI_heatsinkT : 32|8@1+ (1,-40) [0|0] "DegC" Vector__XXX
   SG_ DI_inverterT : 8|8@1+ (1,-40) [0|0] "DegC" Vector__XXX
   SG_ DI_inverterTQF : 56|2@1+ (1,0) [0|0] "" Vector__XXX
   SG_ DI_inverterTpct : 40|8@1+ (0.4,0) [0|0] "%" Vector__XXX
   SG_ DI_pcbT : 0|8@1+ (1,-40) [0|0] "DegC" Vector__XXX
   SG_ DI_statorT : 16|8@1+ (1,-40) [0|0] "DegC" Vector__XXX
   SG_ DI_statorTpct : 48|8@1+ (0.4,0) [0|0] "%" Vector__XXX

BO_ 1367 DI_thermalControl: 3 Vector__XXX
   SG_ DI_activeInletTempReq : 8|8@1+ (1,-40) [0|0] "DegC" Vector__XXX
   SG_ DI_coolantFlowReq : 16|8@1+ (0.2,0) [0|0] "LPM" Vector__XXX
   SG_ DI_passiveInletTempReq : 0|8@1+ (1,-40) [0|0] "DegC" Vector__XXX

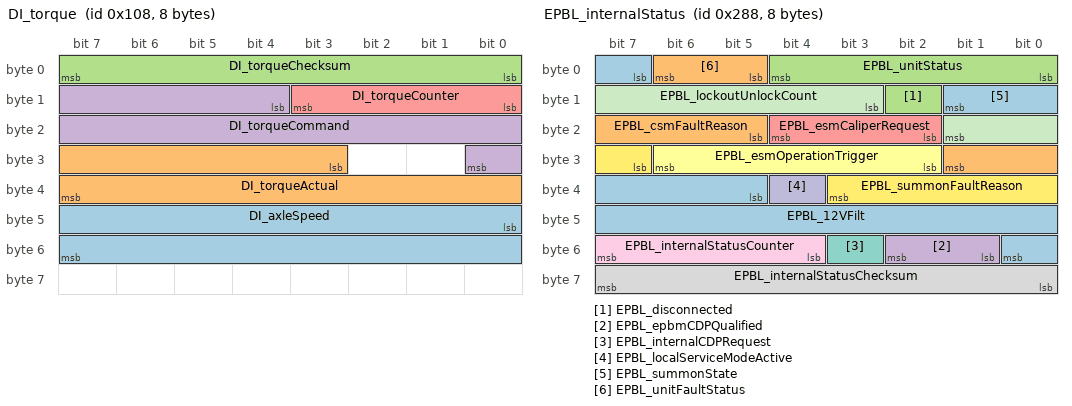
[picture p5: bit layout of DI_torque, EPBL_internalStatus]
BO_ 264 DI_torque: 8 Vector__XXX
   SG_ DI_axleSpeed : 40|16@1- (0.1,0) [0|0] "RPM" Vector__XXX
   SG_ DI_torqueActual : 27|13@1- (2,0) [0|0] "Nm" Vector__XXX
   SG_ DI_torqueChecksum : 0|8@1+ (1,0) [0|0] "" Vector__XXX
   SG_ DI_torqueCommand : 12|13@1- (2,0) [0|0] "Nm" Vector__XXX
   SG_ DI_torqueCounter : 8|4@1+ (1,0) [0|0] "" Vector__XXX

BO_ 1558 DI_udsResponse: 8 Vector__XXX
   SG_ DI_udsResponseData : 0|54@0+ (1024,0) [0|0] "" Vector__XXX

BO_ 914 EPAS3P_alertMatrix: 8 Vector__XXX
   SG_ EPAS3P_matrixIndex M : 0|4@1+ (1,0) [0|0] "" Vector__XXX
   SG_ EPAS3P_a001_sent1Mia m0 : 4|1@1+ (1,0) [0|0] "" Vector__XXX
   SG_ EPAS3P_a002_sent1Error m0 : 5|1@1+ (1,0) [0|0] "" Vector__XXX
   SG_ EPAS3P_a003_trqSens1Supply m0 : 6|1@1+ (1,0) [0|0] "" Vector__XXX
   SG_ EPAS3P_a004_trqSens1Eeprom m0 : 7|1@1+ (1,0) [0|0] "" Vector__XXX
   SG_ EPAS3P_a005_sent2Mia m0 : 8|1@1+ (1,0) [0|0] "" Vector__XXX
   SG_ EPAS3P_a006_sent2Error m0 : 9|1@1+ (1,0) [0|0] "" Vector__XXX
   SG_ EPAS3P_a007_trqSens2Supply m0 : 10|1@1+ (1,0) [0|0] "" Vector__XXX
   SG_ EPAS3P_a008_trqSens2Eeprom m0 : 11|1@1+ (1,0) [0|0] "" Vector__XXX
   SG_ EPAS3P_a009_sentDiff m0 : 12|1@1+ (1,0) [0|0] "" Vector__XXX
   SG_ EPAS3P_a010_trqSensCalError m0 : 13|1@1+ (1,0) [0|0] "" Vector__XXX
   SG_ EPAS3P_a011_currentSensError m0 : 14|1@1+ (1,0) [0|0] "" Vector__XXX
   SG_ EPAS3P_a012_currentSensCalError m0 : 15|1@1+ (1,0) [0|0] "" Vector__XXX
   SG_ EPAS3P_a013_gateDriveError m0 : 16|1@1+ (1,0) [0|0] "" Vector__XXX
   SG_ EPAS3P_a014_gateDriveTxError m0 : 17|1@1+ (1,0) [0|0] "" Vector__XXX
   SG_ EPAS3P_a015_gateDriveEeprom m0 : 18|1@1+ (1,0) [0|0] "" Vector__XXX
   SG_ EPAS3P_a016_phaseUhighUv m0 : 19|1@1+ (1,0) [0|0] "" Vector__XXX
   SG_ EPAS3P_a017_phaseUlowUv m0 : 20|1@1+ (1,0) [0|0] "" Vector__XXX
   SG_ EPAS3P_a018_phaseVhighUv m0 : 21|1@1+ (1,0) [0|0] "" Vector__XXX
   SG_ EPAS3P_a019_phaseVlowUv m0 : 22|1@1+ (1,0) [0|0] "" Vector__XXX
   SG_ EPAS3P_a020_phaseWhighUv m0 : 23|1@1+ (1,0) [0|0] "" Vector__XXX
   SG_ EPAS3P_a021_phaseWlowUv m0 : 24|1@1+ (1,0) [0|0] "" Vector__XXX
   SG_ EPAS3P_a022_phaseUhighOv m0 : 25|1@1+ (1,0) [0|0] "" Vector__XXX
   SG_ EPAS3P_a023_phaseUlowOv m0 : 26|1@1+ (1,0) [0|0] "" Vector__XXX
   SG_ EPAS3P_a024_phaseVhighOv m0 : 27|1@1+ (1,0) [0|0] "" Vector__XXX
   SG_ EPAS3P_a025_phaseVlowOv m0 : 28|1@1+ (1,0) [0|0] "" Vector__XXX
   SG_ EPAS3P_a026_phaseWhighOv m0 : 29|1@1+ (1,0) [0|0] "" Vector__XXX
   SG_ EPAS3P_a027_phaseWlowOv m0 : 30|1@1+ (1,0) [0|0] "" Vector__XXX
   SG_ EPAS3P_a028_phaseUbootUv m0 : 31|1@1+ (1,0) [0|0] "" Vector__XXX
   SG_ EPAS3P_a029_phaseVbootUv m0 : 32|1@1+ (1,0) [0|0] "" Vector__XXX
   SG_ EPAS3P_a030_phaseWbootUv m0 : 33|1@1+ (1,0) [0|0] "" Vector__XXX
   SG_ EPAS3P_a031_phaseFeedbackError m0 : 34|1@1+ (1,0) [0|0] "" Vector__XXX
   SG_ EPAS3P_a032_vRegOutputUv m0 : 35|1@1+ (1,0) [0|0] "" Vector__XXX
   SG_ EPAS3P_a033_vRegOutputOv m0 : 36|1@1+ (1,0) [0|0] "" Vector__XXX
   SG_ EPAS3P_a034_vRegError m0 : 37|1@1+ (1,0) [0|0] "" Vector__XXX
   SG_ EPAS3P_a035_vbbSupplyUv m0 : 38|1@1+ (1,0) [0|0] "" Vector__XXX
   SG_ EPAS3P_a036_vbbSupplyOv m0 : 39|1@1+ (1,0) [0|0] "" Vector__XXX
   SG_ EPAS3P_a037_motPos1ParityError m0 : 40|1@1+ (1,0) [0|0] "" Vector__XXX
   SG_ EPAS3P_a038_motPos1Uv m0 : 41|1@1+ (1,0) [0|0] "" Vector__XXX
   SG_ EPAS3P_a039_motPos1MagnetMia m0 : 42|1@1+ (1,0) [0|0] "" Vector__XXX
   SG_ EPAS3P_a040_motPos1LogicError m0 : 43|1@1+ (1,0) [0|0] "" Vector__XXX
   SG_ EPAS3P_a041_motPos1tempError m0 : 44|1@1+ (1,0) [0|0] "" Vector__XXX
   SG_ EPAS3P_a042_motPos2ParityError m0 : 45|1@1+ (1,0) [0|0] "" Vector__XXX
   SG_ EPAS3P_a043_motPos2Uv m0 : 46|1@1+ (1,0) [0|0] "" Vector__XXX
   SG_ EPAS3P_a044_motPos2MagnetMia m0 : 47|1@1+ (1,0) [0|0] "" Vector__XXX
   SG_ EPAS3P_a045_motPos2LogicError m0 : 48|1@1+ (1,0) [0|0] "" Vector__XXX
   SG_ EPAS3P_a046_motPos2tempError m0 : 49|1@1+ (1,0) [0|0] "" Vector__XXX
   SG_ EPAS3P_a047_motPosCorrError m0 : 50|1@1+ (1,0) [0|0] "" Vector__XXX
   SG_ EPAS3P_a048_motPosCalError m0 : 51|1@1+ (1,0) [0|0] "" Vector__XXX
   SG_ EPAS3P_a049_piCtrlError m0 : 52|1@1+ (1,0) [0|0] "" Vector__XXX
   SG_ EPAS3P_a050_mcuSmuError m0 : 53|1@1+ (1,0) [0|0] "" Vector__XXX
   SG_ EPAS3P_a051_mcuSupError m0 : 54|1@1+ (1,0) [0|0] "" Vector__XXX
   SG_ EPAS3P_a052_intWatchdogError m0 : 55|1@1+ (1,0) [0|0] "" Vector__XXX
   SG_ EPAS3P_a053_extWatchdogError m0 : 56|1@1+ (1,0) [0|0] "" Vector__XXX
   SG_ EPAS3P_a054_memoryProtectError m0 : 57|1@1+ (1,0) [0|0] "" Vector__XXX
   SG_ EPAS3P_a055_floatPointError m0 : 58|1@1+ (1,0) [0|0] "" Vector__XXX
   SG_ EPAS3P_a056_battUv m0 : 59|1@1+ (1,0) [0|0] "" Vector__XXX
   SG_ EPAS3P_a057_battUvReduced m0 : 60|1@1+ (1,0) [0|0] "" Vector__XXX
   SG_ EPAS3P_a058_battOv m0 : 61|1@1+ (1,0) [0|0] "" Vector__XXX
   SG_ EPAS3P_a059_battOvReduced m0 : 62|1@1+ (1,0) [0|0] "" Vector__XXX
   SG_ EPAS3P_a060_battBridgeDiff m0 : 63|1@1+ (1,0) [0|0] "" Vector__XXX
   SG_ EPAS3P_a061_bridgeUv m1 : 4|1@1+ (1,0) [0|0] "" Vector__XXX
   SG_ EPAS3P_a062_assistCorrError m1 : 5|1@1+ (1,0) [0|0] "" Vector__XXX
   SG_ EPAS3P_a063_dampCorrError m1 : 6|1@1+ (1,0) [0|0] "" Vector__XXX
   SG_ EPAS3P_a064_phaseCompCorrError m1 : 7|1@1+ (1,0) [0|0] "" Vector__XXX
   SG_ EPAS3P_a065_trqTarCorrError m1 : 8|1@1+ (1,0) [0|0] "" Vector__XXX
   SG_ EPAS3P_a066_returnCorrError m1 : 9|1@1+ (1,0) [0|0] "" Vector__XXX
   SG_ EPAS3P_a067_yawDampCorrError m1 : 10|1@1+ (1,0) [0|0] "" Vector__XXX
   SG_ EPAS3P_a068_hystCorrError m1 : 11|1@1+ (1,0) [0|0] "" Vector__XXX
   SG_ EPAS3P_a069_eacCorrError m1 : 12|1@1+ (1,0) [0|0] "" Vector__XXX
   SG_ EPAS3P_a070_hodCorrError m1 : 13|1@1+ (1,0) [0|0] "" Vector__XXX
   SG_ EPAS3P_a071_vehSpdCorrError m1 : 14|1@1+ (1,0) [0|0] "" Vector__XXX
   SG_ EPAS3P_a072_motFeedFwdError m1 : 15|1@1+ (1,0) [0|0] "" Vector__XXX
   SG_ EPAS3P_a073_motParEstError m1 : 16|1@1+ (1,0) [0|0] "" Vector__XXX
   SG_ EPAS3P_a074_overHeatProtect m1 : 17|1@1+ (1,0) [0|0] "" Vector__XXX
   SG_ EPAS3P_a075_fspPwrCut m1 : 18|1@1+ (1,0) [0|0] "" Vector__XXX
   SG_ EPAS3P_a076_tempSensOutofRange m1 : 19|1@1+ (1,0) [0|0] "" Vector__XXX
   SG_ EPAS3P_a077_highSideFetError m1 : 20|1@1+ (1,0) [0|0] "" Vector__XXX
   SG_ EPAS3P_a078_phaseDisconnectError m1 : 21|1@1+ (1,0) [0|0] "" Vector__XXX
   SG_ EPAS3P_a079_backupCurrentPlaus m1 : 22|1@1+ (1,0) [0|0] "" Vector__XXX
   SG_ EPAS3P_a080_ecuInitArbError m1 : 23|1@1+ (1,0) [0|0] "" Vector__XXX
   SG_ EPAS3P_a081_coggCompError m1 : 24|1@1+ (1,0) [0|0] "" Vector__XXX
   SG_ EPAS3P_a082_polarityCalError m1 : 25|1@1+ (1,0) [0|0] "" Vector__XXX
   SG_ EPAS3P_a083_crcMismatch m1 : 26|1@1+ (1,0) [0|0] "" Vector__XXX
   SG_ EPAS3P_a084_eacCancelled m1 : 27|1@1+ (1,0) [0|0] "" Vector__XXX
   SG_ EPAS3P_a085_canBusOff m1 : 28|1@1+ (1,0) [0|0] "" Vector__XXX
   SG_ EPAS3P_a086_dasMia m1 : 29|1@1+ (1,0) [0|0] "" Vector__XXX
   SG_ EPAS3P_a087_dasCntError m1 : 30|1@1+ (1,0) [0|0] "" Vector__XXX
   SG_ EPAS3P_a088_dasCsError m1 : 31|1@1+ (1,0) [0|0] "" Vector__XXX
   SG_ EPAS3P_a089_espWsMia m1 : 32|1@1+ (1,0) [0|0] "" Vector__XXX
   SG_ EPAS3P_a090_espWsCntError m1 : 33|1@1+ (1,0) [0|0] "" Vector__XXX
   SG_ EPAS3P_a091_espWsCsError m1 : 34|1@1+ (1,0) [0|0] "" Vector__XXX
   SG_ EPAS3P_a092_espWrMia m1 : 35|1@1+ (1,0) [0|0] "" Vector__XXX
   SG_ EPAS3P_a093_espWrCntError m1 : 36|1@1+ (1,0) [0|0] "" Vector__XXX
   SG_ EPAS3P_a094_espWrCsError m1 : 37|1@1+ (1,0) [0|0] "" Vector__XXX
   SG_ EPAS3P_a095_espWsStatus m1 : 38|1@1+ (1,0) [0|0] "" Vector__XXX
   SG_ EPAS3P_a096_rcmMia m1 : 39|1@1+ (1,0) [0|0] "" Vector__XXX
   SG_ EPAS3P_a097_rcmCntError m1 : 40|1@1+ (1,0) [0|0] "" Vector__XXX
   SG_ EPAS3P_a098_rcmCsError m1 : 41|1@1+ (1,0) [0|0] "" Vector__XXX
   SG_ EPAS3P_a099_yawRateStatus m1 : 42|1@1+ (1,0) [0|0] "" Vector__XXX
   SG_ EPAS3P_a100_diMia m1 : 43|1@1+ (1,0) [0|0] "" Vector__XXX
   SG_ EPAS3P_a101_diCntError m1 : 44|1@1+ (1,0) [0|0] "" Vector__XXX
   SG_ EPAS3P_a102_diCsError m1 : 45|1@1+ (1,0) [0|0] "" Vector__XXX
   SG_ EPAS3P_a103_vcFrontMia m1 : 46|1@1+ (1,0) [0|0] "" Vector__XXX
   SG_ EPAS3P_a104_vcFrontCntError m1 : 47|1@1+ (1,0) [0|0] "" Vector__XXX
   SG_ EPAS3P_a105_vcFrontCsError m1 : 48|1@1+ (1,0) [0|0] "" Vector__XXX
   SG_ EPAS3P_a106_vcFrontTempMia m1 : 49|1@1+ (1,0) [0|0] "" Vector__XXX
   SG_ EPAS3P_a107_uiTuneReqMia m1 : 50|1@1+ (1,0) [0|0] "" Vector__XXX
   SG_ EPAS3P_a108_uiTuneReqCntError m1 : 51|1@1+ (1,0) [0|0] "" Vector__XXX
   SG_ EPAS3P_a109_uiTuneReqCsError m1 : 52|1@1+ (1,0) [0|0] "" Vector__XXX
   SG_ EPAS3P_a110_sasMia m1 : 53|1@1+ (1,0) [0|0] "" Vector__XXX
   SG_ EPAS3P_a111_sasCntError m1 : 54|1@1+ (1,0) [0|0] "" Vector__XXX
   SG_ EPAS3P_a112_sasCsError m1 : 55|1@1+ (1,0) [0|0] "" Vector__XXX
   SG_ EPAS3P_a113_sasStatusError m1 : 56|1@1+ (1,0) [0|0] "" Vector__XXX
   SG_ EPAS3P_a114_gtwConfigMia m1 : 57|1@1+ (1,0) [0|0] "" Vector__XXX
   SG_ EPAS3P_a115_ecuStatMia m1 : 58|1@1+ (1,0) [0|0] "" Vector__XXX
   SG_ EPAS3P_a116_ecuStatCntError m1 : 59|1@1+ (1,0) [0|0] "" Vector__XXX
   SG_ EPAS3P_a117_ecuStatCrcError m1 : 60|1@1+ (1,0) [0|0] "" Vector__XXX
   SG_ EPAS3P_a118_privateBusOff m1 : 61|1@1+ (1,0) [0|0] "" Vector__XXX
   SG_ EPAS3P_a119_pvtEcuStatMia m1 : 62|1@1+ (1,0) [0|0] "" Vector__XXX
   SG_ EPAS3P_a120_pvtEcuStatCntError m1 : 63|1@1+ (1,0) [0|0] "" Vector__XXX
   SG_ EPAS3P_a121_pvtEcuStatCrcError m2 : 4|1@1+ (1,0) [0|0] "" Vector__XXX
   SG_ EPAS3P_a122_olpActive m2 : 5|1@1+ (1,0) [0|0] "" Vector__XXX
   SG_ EPAS3P_a123_combEcu2StatFail m2 : 6|1@1+ (1,0) [0|0] "" Vector__XXX
   SG_ EPAS3P_a124_tempSensStuckInRange m2 : 7|1@1+ (1,0) [0|0] "" Vector__XXX
   SG_ EPAS3P_a125_trqSensTrimOutRange m2 : 8|1@1+ (1,0) [0|0] "" Vector__XXX
   SG_ EPAS3P_a126_apsMia m2 : 9|1@1+ (1,0) [0|0] "" Vector__XXX
   SG_ EPAS3P_a127_apsCntError m2 : 10|1@1+ (1,0) [0|0] "" Vector__XXX
   SG_ EPAS3P_a128_apsCsError m2 : 11|1@1+ (1,0) [0|0] "" Vector__XXX
   SG_ EPAS3P_a129_combEcu1StatFail m2 : 12|1@1+ (1,0) [0|0] "" Vector__XXX
   SG_ EPAS3P_a130_sasOffsetNotCal m2 : 13|1@1+ (1,0) [0|0] "" Vector__XXX

BO_ 817 EPAS3P_info: 8 Vector__XXX
   SG_ EPAS3P_infoIndex M : 0|8@1+ (1,0) [0|0] "" Vector__XXX
   SG_ EPAS3P_infoBuildType m10 : 8|8@1+ (1,0) [0|0] "" Vector__XXX
   SG_ EPAS3P_infoComponentID m10 : 48|16@1+ (1,0) [0|0] "" Vector__XXX
   SG_ EPAS3P_infoPcbaID m11 : 16|8@1+ (1,0) [0|0] "" Vector__XXX
   SG_ EPAS3P_infoAssemblyID m11 : 24|8@1+ (1,0) [0|0] "" Vector__XXX
   SG_ EPAS3P_infoUsageID m11 : 32|16@1+ (1,0) [0|0] "" Vector__XXX
   SG_ EPAS3P_infoBootUdsProtoVersion m20 : 8|8@1+ (1,0) [0|0] "" Vector__XXX
   SG_ EPAS3P_infoBootloaderCRC m20 : 32|32@1+ (1,0) [0|0] "" Vector__XXX
   SG_ EPAS3P_infoApplicationCRC m13 : 32|32@1+ (1,0) [0|0] "" Vector__XXX

BO_ 883 EPAS3P_sysStatus: 8 Vector__XXX
   SG_ EPAS3P_currentTuneMode : 5|3@1+ (1,0) [0|0] "" Vector__XXX
   SG_ EPAS3P_eacErrorCode : 20|4@1+ (1,0) [0|0] "" Vector__XXX
   SG_ EPAS3P_eacStatus : 53|3@1+ (1,0) [0|0] "" Vector__XXX
   SG_ EPAS3P_handsOnLevel : 38|2@1+ (1,0) [0|0] "" Vector__XXX
   SG_ EPAS3P_internalSAS : 32|14@0+ (0.1,-819.2) [0|0] "deg" Vector__XXX
   SG_ EPAS3P_internalSASQF : 4|1@1+ (1,0) [0|0] "" Vector__XXX
   SG_ EPAS3P_steeringFault : 2|1@1+ (1,0) [0|0] "" Vector__XXX
   SG_ EPAS3P_steeringRackForce : 0|10@0+ (50,-25575) [0|0] "N" Vector__XXX
   SG_ EPAS3P_steeringReduced : 3|1@1+ (1,0) [0|0] "" Vector__XXX
   SG_ EPAS3P_sysStatusChecksum : 56|8@1+ (1,0) [0|0] "" Vector__XXX
   SG_ EPAS3P_sysStatusCounter : 48|4@1+ (1,0) [0|0] "" Vector__XXX
   SG_ EPAS3P_torsionBarTorque : 16|12@0+ (0.01,-20.5) [0|0] "Nm" Vector__XXX

BO_ 1592 EPAS3P_udsResponseCH: 8 Vector__XXX
   SG_ EPAS3P_udsResponseDataCH : 0|54@0+ (1024,0) [0|0] "" Vector__XXX

BO_ 913 EPAS3S_alertMatrix: 8 Vector__XXX
   SG_ EPAS3S_matrixIndex M : 0|4@1+ (1,0) [0|0] "" Vector__XXX
   SG_ EPAS3S_a001_sent1Mia m0 : 4|1@1+ (1,0) [0|0] "" Vector__XXX
   SG_ EPAS3S_a002_sent1Error m0 : 5|1@1+ (1,0) [0|0] "" Vector__XXX
   SG_ EPAS3S_a003_trqSens1Supply m0 : 6|1@1+ (1,0) [0|0] "" Vector__XXX
   SG_ EPAS3S_a004_trqSens1Eeprom m0 : 7|1@1+ (1,0) [0|0] "" Vector__XXX
   SG_ EPAS3S_a005_sent2Mia m0 : 8|1@1+ (1,0) [0|0] "" Vector__XXX
   SG_ EPAS3S_a006_sent2Error m0 : 9|1@1+ (1,0) [0|0] "" Vector__XXX
   SG_ EPAS3S_a007_trqSens2Supply m0 : 10|1@1+ (1,0) [0|0] "" Vector__XXX
   SG_ EPAS3S_a008_trqSens2Eeprom m0 : 11|1@1+ (1,0) [0|0] "" Vector__XXX
   SG_ EPAS3S_a009_sentDiff m0 : 12|1@1+ (1,0) [0|0] "" Vector__XXX
   SG_ EPAS3S_a010_trqSensCalError m0 : 13|1@1+ (1,0) [0|0] "" Vector__XXX
   SG_ EPAS3S_a011_currentSensError m0 : 14|1@1+ (1,0) [0|0] "" Vector__XXX
   SG_ EPAS3S_a012_currentSensCalError m0 : 15|1@1+ (1,0) [0|0] "" Vector__XXX
   SG_ EPAS3S_a013_gateDriveError m0 : 16|1@1+ (1,0) [0|0] "" Vector__XXX
   SG_ EPAS3S_a014_gateDriveTxError m0 : 17|1@1+ (1,0) [0|0] "" Vector__XXX
   SG_ EPAS3S_a015_gateDriveEeprom m0 : 18|1@1+ (1,0) [0|0] "" Vector__XXX
   SG_ EPAS3S_a016_phaseUhighUv m0 : 19|1@1+ (1,0) [0|0] "" Vector__XXX
   SG_ EPAS3S_a017_phaseUlowUv m0 : 20|1@1+ (1,0) [0|0] "" Vector__XXX
   SG_ EPAS3S_a018_phaseVhighUv m0 : 21|1@1+ (1,0) [0|0] "" Vector__XXX
   SG_ EPAS3S_a019_phaseVlowUv m0 : 22|1@1+ (1,0) [0|0] "" Vector__XXX
   SG_ EPAS3S_a020_phaseWhighUv m0 : 23|1@1+ (1,0) [0|0] "" Vector__XXX
   SG_ EPAS3S_a021_phaseWlowUv m0 : 24|1@1+ (1,0) [0|0] "" Vector__XXX
   SG_ EPAS3S_a022_phaseUhighOv m0 : 25|1@1+ (1,0) [0|0] "" Vector__XXX
   SG_ EPAS3S_a023_phaseUlowOv m0 : 26|1@1+ (1,0) [0|0] "" Vector__XXX
   SG_ EPAS3S_a024_phaseVhighOv m0 : 27|1@1+ (1,0) [0|0] "" Vector__XXX
   SG_ EPAS3S_a025_phaseVlowOv m0 : 28|1@1+ (1,0) [0|0] "" Vector__XXX
   SG_ EPAS3S_a026_phaseWhighOv m0 : 29|1@1+ (1,0) [0|0] "" Vector__XXX
   SG_ EPAS3S_a027_phaseWlowOv m0 : 30|1@1+ (1,0) [0|0] "" Vector__XXX
   SG_ EPAS3S_a028_phaseUbootUv m0 : 31|1@1+ (1,0) [0|0] "" Vector__XXX
   SG_ EPAS3S_a029_phaseVbootUv m0 : 32|1@1+ (1,0) [0|0] "" Vector__XXX
   SG_ EPAS3S_a030_phaseWbootUv m0 : 33|1@1+ (1,0) [0|0] "" Vector__XXX
   SG_ EPAS3S_a031_phaseFeedbackError m0 : 34|1@1+ (1,0) [0|0] "" Vector__XXX
   SG_ EPAS3S_a032_vRegOutputUv m0 : 35|1@1+ (1,0) [0|0] "" Vector__XXX
   SG_ EPAS3S_a033_vRegOutputOv m0 : 36|1@1+ (1,0) [0|0] "" Vector__XXX
   SG_ EPAS3S_a034_vRegError m0 : 37|1@1+ (1,0) [0|0] "" Vector__XXX
   SG_ EPAS3S_a035_vbbSupplyUv m0 : 38|1@1+ (1,0) [0|0] "" Vector__XXX
   SG_ EPAS3S_a036_vbbSupplyOv m0 : 39|1@1+ (1,0) [0|0] "" Vector__XXX
   SG_ EPAS3S_a037_motPos1ParityError m0 : 40|1@1+ (1,0) [0|0] "" Vector__XXX
   SG_ EPAS3S_a038_motPos1Uv m0 : 41|1@1+ (1,0) [0|0] "" Vector__XXX
   SG_ EPAS3S_a039_motPos1MagnetMia m0 : 42|1@1+ (1,0) [0|0] "" Vector__XXX
   SG_ EPAS3S_a040_motPos1LogicError m0 : 43|1@1+ (1,0) [0|0] "" Vector__XXX
   SG_ EPAS3S_a041_motPos1tempError m0 : 44|1@1+ (1,0) [0|0] "" Vector__XXX
   SG_ EPAS3S_a042_motPos2ParityError m0 : 45|1@1+ (1,0) [0|0] "" Vector__XXX
   SG_ EPAS3S_a043_motPos2Uv m0 : 46|1@1+ (1,0) [0|0] "" Vector__XXX
   SG_ EPAS3S_a044_motPos2MagnetMia m0 : 47|1@1+ (1,0) [0|0] "" Vector__XXX
   SG_ EPAS3S_a045_motPos2LogicError m0 : 48|1@1+ (1,0) [0|0] "" Vector__XXX
   SG_ EPAS3S_a046_motPos2tempError m0 : 49|1@1+ (1,0) [0|0] "" Vector__XXX
   SG_ EPAS3S_a047_motPosCorrError m0 : 50|1@1+ (1,0) [0|0] "" Vector__XXX
   SG_ EPAS3S_a048_motPosCalError m0 : 51|1@1+ (1,0) [0|0] "" Vector__XXX
   SG_ EPAS3S_a049_piCtrlError m0 : 52|1@1+ (1,0) [0|0] "" Vector__XXX
   SG_ EPAS3S_a050_mcuSmuError m0 : 53|1@1+ (1,0) [0|0] "" Vector__XXX
   SG_ EPAS3S_a051_mcuSupError m0 : 54|1@1+ (1,0) [0|0] "" Vector__XXX
   SG_ EPAS3S_a052_intWatchdogError m0 : 55|1@1+ (1,0) [0|0] "" Vector__XXX
   SG_ EPAS3S_a053_extWatchdogError m0 : 56|1@1+ (1,0) [0|0] "" Vector__XXX
   SG_ EPAS3S_a054_memoryProtectError m0 : 57|1@1+ (1,0) [0|0] "" Vector__XXX
   SG_ EPAS3S_a055_floatPointError m0 : 58|1@1+ (1,0) [0|0] "" Vector__XXX
   SG_ EPAS3S_a056_battUv m0 : 59|1@1+ (1,0) [0|0] "" Vector__XXX
   SG_ EPAS3S_a057_battUvReduced m0 : 60|1@1+ (1,0) [0|0] "" Vector__XXX
   SG_ EPAS3S_a058_battOv m0 : 61|1@1+ (1,0) [0|0] "" Vector__XXX
   SG_ EPAS3S_a059_battOvReduced m0 : 62|1@1+ (1,0) [0|0] "" Vector__XXX
   SG_ EPAS3S_a060_battBridgeDiff m0 : 63|1@1+ (1,0) [0|0] "" Vector__XXX
   SG_ EPAS3S_a061_bridgeUv m1 : 4|1@1+ (1,0) [0|0] "" Vector__XXX
   SG_ EPAS3S_a062_assistCorrError m1 : 5|1@1+ (1,0) [0|0] "" Vector__XXX
   SG_ EPAS3S_a063_dampCorrError m1 : 6|1@1+ (1,0) [0|0] "" Vector__XXX
   SG_ EPAS3S_a064_phaseCompCorrError m1 : 7|1@1+ (1,0) [0|0] "" Vector__XXX
   SG_ EPAS3S_a065_trqTarCorrError m1 : 8|1@1+ (1,0) [0|0] "" Vector__XXX
   SG_ EPAS3S_a066_returnCorrError m1 : 9|1@1+ (1,0) [0|0] "" Vector__XXX
   SG_ EPAS3S_a067_yawDampCorrError m1 : 10|1@1+ (1,0) [0|0] "" Vector__XXX
   SG_ EPAS3S_a068_hystCorrError m1 : 11|1@1+ (1,0) [0|0] "" Vector__XXX
   SG_ EPAS3S_a069_eacCorrError m1 : 12|1@1+ (1,0) [0|0] "" Vector__XXX
   SG_ EPAS3S_a070_hodCorrError m1 : 13|1@1+ (1,0) [0|0] "" Vector__XXX
   SG_ EPAS3S_a071_vehSpdCorrError m1 : 14|1@1+ (1,0) [0|0] "" Vector__XXX
   SG_ EPAS3S_a072_motFeedFwdError m1 : 15|1@1+ (1,0) [0|0] "" Vector__XXX
   SG_ EPAS3S_a073_motParEstError m1 : 16|1@1+ (1,0) [0|0] "" Vector__XXX
   SG_ EPAS3S_a074_overHeatProtect m1 : 17|1@1+ (1,0) [0|0] "" Vector__XXX
   SG_ EPAS3S_a075_fspPwrCut m1 : 18|1@1+ (1,0) [0|0] "" Vector__XXX
   SG_ EPAS3S_a076_tempSensOutofRange m1 : 19|1@1+ (1,0) [0|0] "" Vector__XXX
   SG_ EPAS3S_a077_highSideFetError m1 : 20|1@1+ (1,0) [0|0] "" Vector__XXX
   SG_ EPAS3S_a078_phaseDisconnectError m1 : 21|1@1+ (1,0) [0|0] "" Vector__XXX
   SG_ EPAS3S_a079_backupCurrentPlaus m1 : 22|1@1+ (1,0) [0|0] "" Vector__XXX
   SG_ EPAS3S_a080_ecuInitArbError m1 : 23|1@1+ (1,0) [0|0] "" Vector__XXX
   SG_ EPAS3S_a081_coggCompError m1 : 24|1@1+ (1,0) [0|0] "" Vector__XXX
   SG_ EPAS3S_a082_polarityCalError m1 : 25|1@1+ (1,0) [0|0] "" Vector__XXX
   SG_ EPAS3S_a083_crcMismatch m1 : 26|1@1+ (1,0) [0|0] "" Vector__XXX
   SG_ EPAS3S_a084_eacCancelled m1 : 27|1@1+ (1,0) [0|0] "" Vector__XXX
   SG_ EPAS3S_a085_canBusOff m1 : 28|1@1+ (1,0) [0|0] "" Vector__XXX
   SG_ EPAS3S_a086_dasMia m1 : 29|1@1+ (1,0) [0|0] "" Vector__XXX
   SG_ EPAS3S_a087_dasCntError m1 : 30|1@1+ (1,0) [0|0] "" Vector__XXX
   SG_ EPAS3S_a088_dasCsError m1 : 31|1@1+ (1,0) [0|0] "" Vector__XXX
   SG_ EPAS3S_a089_espWsMia m1 : 32|1@1+ (1,0) [0|0] "" Vector__XXX
   SG_ EPAS3S_a090_espWsCntError m1 : 33|1@1+ (1,0) [0|0] "" Vector__XXX
   SG_ EPAS3S_a091_espWsCsError m1 : 34|1@1+ (1,0) [0|0] "" Vector__XXX
   SG_ EPAS3S_a092_espWrMia m1 : 35|1@1+ (1,0) [0|0] "" Vector__XXX
   SG_ EPAS3S_a093_espWrCntError m1 : 36|1@1+ (1,0) [0|0] "" Vector__XXX
   SG_ EPAS3S_a094_espWrCsError m1 : 37|1@1+ (1,0) [0|0] "" Vector__XXX
   SG_ EPAS3S_a095_espWsStatus m1 : 38|1@1+ (1,0) [0|0] "" Vector__XXX
   SG_ EPAS3S_a096_rcmMia m1 : 39|1@1+ (1,0) [0|0] "" Vector__XXX
   SG_ EPAS3S_a097_rcmCntError m1 : 40|1@1+ (1,0) [0|0] "" Vector__XXX
   SG_ EPAS3S_a098_rcmCsError m1 : 41|1@1+ (1,0) [0|0] "" Vector__XXX
   SG_ EPAS3S_a099_yawRateStatus m1 : 42|1@1+ (1,0) [0|0] "" Vector__XXX
   SG_ EPAS3S_a100_diMia m1 : 43|1@1+ (1,0) [0|0] "" Vector__XXX
   SG_ EPAS3S_a101_diCntError m1 : 44|1@1+ (1,0) [0|0] "" Vector__XXX
   SG_ EPAS3S_a102_diCsError m1 : 45|1@1+ (1,0) [0|0] "" Vector__XXX
   SG_ EPAS3S_a103_vcFrontMia m1 : 46|1@1+ (1,0) [0|0] "" Vector__XXX
   SG_ EPAS3S_a104_vcFrontCntError m1 : 47|1@1+ (1,0) [0|0] "" Vector__XXX
   SG_ EPAS3S_a105_vcFrontCsError m1 : 48|1@1+ (1,0) [0|0] "" Vector__XXX
   SG_ EPAS3S_a106_vcFrontTempMia m1 : 49|1@1+ (1,0) [0|0] "" Vector__XXX
   SG_ EPAS3S_a107_uiTuneReqMia m1 : 50|1@1+ (1,0) [0|0] "" Vector__XXX
   SG_ EPAS3S_a108_uiTuneReqCntError m1 : 51|1@1+ (1,0) [0|0] "" Vector__XXX
   SG_ EPAS3S_a109_uiTuneReqCsError m1 : 52|1@1+ (1,0) [0|0] "" Vector__XXX
   SG_ EPAS3S_a110_sasMia m1 : 53|1@1+ (1,0) [0|0] "" Vector__XXX
   SG_ EPAS3S_a111_sasCntError m1 : 54|1@1+ (1,0) [0|0] "" Vector__XXX
   SG_ EPAS3S_a112_sasCsError m1 : 55|1@1+ (1,0) [0|0] "" Vector__XXX
   SG_ EPAS3S_a113_sasStatusError m1 : 56|1@1+ (1,0) [0|0] "" Vector__XXX
   SG_ EPAS3S_a114_gtwConfigMia m1 : 57|1@1+ (1,0) [0|0] "" Vector__XXX
   SG_ EPAS3S_a115_ecuStatMia m1 : 58|1@1+ (1,0) [0|0] "" Vector__XXX
   SG_ EPAS3S_a116_ecuStatCntError m1 : 59|1@1+ (1,0) [0|0] "" Vector__XXX
   SG_ EPAS3S_a117_ecuStatCrcError m1 : 60|1@1+ (1,0) [0|0] "" Vector__XXX
   SG_ EPAS3S_a118_privateBusOff m1 : 61|1@1+ (1,0) [0|0] "" Vector__XXX
   SG_ EPAS3S_a119_pvtEcuStatMia m1 : 62|1@1+ (1,0) [0|0] "" Vector__XXX
   SG_ EPAS3S_a120_pvtEcuStatCntError m1 : 63|1@1+ (1,0) [0|0] "" Vector__XXX
   SG_ EPAS3S_a121_pvtEcuStatCrcError m2 : 4|1@1+ (1,0) [0|0] "" Vector__XXX
   SG_ EPAS3S_a122_olpActive m2 : 5|1@1+ (1,0) [0|0] "" Vector__XXX
   SG_ EPAS3S_a123_combEcu2StatFail m2 : 6|1@1+ (1,0) [0|0] "" Vector__XXX
   SG_ EPAS3S_a124_tempSensStuckInRange m2 : 7|1@1+ (1,0) [0|0] "" Vector__XXX
   SG_ EPAS3S_a125_trqSensTrimOutRange m2 : 8|1@1+ (1,0) [0|0] "" Vector__XXX
   SG_ EPAS3S_a126_apsMia m2 : 9|1@1+ (1,0) [0|0] "" Vector__XXX
   SG_ EPAS3S_a127_apsCntError m2 : 10|1@1+ (1,0) [0|0] "" Vector__XXX
   SG_ EPAS3S_a128_apsCsError m2 : 11|1@1+ (1,0) [0|0] "" Vector__XXX
   SG_ EPAS3S_a129_combEcu1StatFail m2 : 12|1@1+ (1,0) [0|0] "" Vector__XXX
   SG_ EPAS3S_a130_sasOffsetNotCal m2 : 13|1@1+ (1,0) [0|0] "" Vector__XXX

BO_ 785 EPAS3S_info: 8 Vector__XXX
   SG_ EPAS3S_infoIndex M : 0|8@1+ (1,0) [0|0] "" Vector__XXX
   SG_ EPAS3S_infoBuildType m10 : 8|8@1+ (1,0) [0|0] "" Vector__XXX
   SG_ EPAS3S_infoComponentID m10 : 48|16@1+ (1,0) [0|0] "" Vector__XXX
   SG_ EPAS3S_infoPcbaID m11 : 16|8@1+ (1,0) [0|0] "" Vector__XXX
   SG_ EPAS3S_infoAssemblyID m11 : 24|8@1+ (1,0) [0|0] "" Vector__XXX
   SG_ EPAS3S_infoUsageID m11 : 32|16@1+ (1,0) [0|0] "" Vector__XXX
   SG_ EPAS3S_infoBootUdsProtoVersion m20 : 8|8@1+ (1,0) [0|0] "" Vector__XXX
   SG_ EPAS3S_infoBootloaderCRC m20 : 32|32@1+ (1,0) [0|0] "" Vector__XXX
   SG_ EPAS3S_infoApplicationCRC m13 : 32|32@1+ (1,0) [0|0] "" Vector__XXX

BO_ 882 EPAS3S_sysStatus: 8 Vector__XXX
   SG_ EPAS3S_currentTuneMode : 5|3@1+ (1,0) [0|0] "" Vector__XXX
   SG_ EPAS3S_eacErrorCode : 20|4@1+ (1,0) [0|0] "" Vector__XXX
   SG_ EPAS3S_eacStatus : 53|3@1+ (1,0) [0|0] "" Vector__XXX
   SG_ EPAS3S_handsOnLevel : 38|2@1+ (1,0) [0|0] "" Vector__XXX
   SG_ EPAS3S_internalSAS : 32|14@0+ (0.1,-819.2) [0|0] "deg" Vector__XXX
   SG_ EPAS3S_internalSASQF : 4|1@1+ (1,0) [0|0] "" Vector__XXX
   SG_ EPAS3S_steeringFault : 2|1@1+ (1,0) [0|0] "" Vector__XXX
   SG_ EPAS3S_steeringRackForce : 0|10@0+ (50,-25575) [0|0] "N" Vector__XXX
   SG_ EPAS3S_steeringReduced : 3|1@1+ (1,0) [0|0] "" Vector__XXX
   SG_ EPAS3S_sysStatusChecksum : 56|8@1+ (1,0) [0|0] "" Vector__XXX
   SG_ EPAS3S_sysStatusCounter : 48|4@1+ (1,0) [0|0] "" Vector__XXX
   SG_ EPAS3S_torsionBarTorque : 16|12@0+ (0.01,-20.5) [0|0] "Nm" Vector__XXX

BO_ 1848 EPAS3S_udsResponse: 8 Vector__XXX
   SG_ EPAS3S_udsResponseData : 0|54@0+ (1024,0) [0|0] "" Vector__XXX

BO_ 968 EPBL_alertMatrix: 8 Vector__XXX
   SG_ EPBL_matrixIndex M : 0|4@1+ (1,0) [0|0] "" Vector__XXX
   SG_ EPBL_a001_WatchdogReset m0 : 4|1@1+ (1,0) [0|0] "" Vector__XXX
   SG_ EPBL_a002_PowerLossReset m0 : 5|1@1+ (1,0) [0|0] "" Vector__XXX
   SG_ EPBL_a003_SWAssertion m0 : 6|1@1+ (1,0) [0|0] "" Vector__XXX
   SG_ EPBL_a010_ExtSupplyVoltError m0 : 13|1@1+ (1,0) [0|0] "" Vector__XXX
   SG_ EPBL_a012_CPUReset m0 : 15|1@1+ (1,0) [0|0] "" Vector__XXX
   SG_ EPBL_a013_AlertManagerFault m0 : 16|1@1+ (1,0) [0|0] "" Vector__XXX
   SG_ EPBL_a015_NVMMAlert m0 : 18|1@1+ (1,0) [0|0] "" Vector__XXX
   SG_ EPBL_a021_TaskSchedulerError m0 : 24|1@1+ (1,0) [0|0] "" Vector__XXX
   SG_ EPBL_a022_TaskInitError m0 : 25|1@1+ (1,0) [0|0] "" Vector__XXX
   SG_ EPBL_a031_UDSActive m0 : 34|1@1+ (1,0) [0|0] "" Vector__XXX
   SG_ EPBL_a041_HighCPULoad m0 : 44|1@1+ (1,0) [0|0] "" Vector__XXX
   SG_ EPBL_a042_HighStackUsage m0 : 45|1@1+ (1,0) [0|0] "" Vector__XXX
   SG_ EPBL_a043_Task1msError m0 : 46|1@1+ (1,0) [0|0] "" Vector__XXX
   SG_ EPBL_a044_Task10msError m0 : 47|1@1+ (1,0) [0|0] "" Vector__XXX
   SG_ EPBL_a045_Task100msError m0 : 48|1@1+ (1,0) [0|0] "" Vector__XXX
   SG_ EPBL_a046_Task1000msError m0 : 49|1@1+ (1,0) [0|0] "" Vector__XXX
   SG_ EPBL_a059_inputResistanceHigh m0 : 62|1@1+ (1,0) [0|0] "" Vector__XXX
   SG_ EPBL_a060_engineeringBuild m0 : 63|1@1+ (1,0) [0|0] "" Vector__XXX
   SG_ EPBL_a061_XCPConnected m1 : 4|1@1+ (1,0) [0|0] "" Vector__XXX
   SG_ EPBL_a062_XCPWasConnected m1 : 5|1@1+ (1,0) [0|0] "" Vector__XXX
   SG_ EPBL_a063_SwitchFault m1 : 6|1@1+ (1,0) [0|0] "" Vector__XXX
   SG_ EPBL_a064_busSleepReqTimeout m1 : 7|1@1+ (1,0) [0|0] "" Vector__XXX
   SG_ EPBL_a097_CMP_MIA m1 : 40|1@1+ (1,0) [0|0] "" Vector__XXX
   SG_ EPBL_a098_DI_THERMAL_MIA m1 : 41|1@1+ (1,0) [0|0] "" Vector__XXX
   SG_ EPBL_a099_PARK_MIA m1 : 42|1@1+ (1,0) [0|0] "" Vector__XXX
   SG_ EPBL_a100_CANbus_MIA m1 : 43|1@1+ (1,0) [0|0] "" Vector__XXX
   SG_ EPBL_a101_PM_MIA m1 : 44|1@1+ (1,0) [0|0] "" Vector__XXX
   SG_ EPBL_a102_PTC_MIA m1 : 45|1@1+ (1,0) [0|0] "" Vector__XXX
   SG_ EPBL_a103_CP_MIA m1 : 46|1@1+ (1,0) [0|0] "" Vector__XXX
   SG_ EPBL_a104_DAS_MIA m1 : 47|1@1+ (1,0) [0|0] "" Vector__XXX
   SG_ EPBL_a105_TAS_MIA m1 : 48|1@1+ (1,0) [0|0] "" Vector__XXX
   SG_ EPBL_a106_PCS_MIA m1 : 49|1@1+ (1,0) [0|0] "" Vector__XXX
   SG_ EPBL_a107_BMS_MIA m1 : 50|1@1+ (1,0) [0|0] "" Vector__XXX
   SG_ EPBL_a108_DIS_MIA m1 : 51|1@1+ (1,0) [0|0] "" Vector__XXX
   SG_ EPBL_a109_RCM_MIA m1 : 52|1@1+ (1,0) [0|0] "" Vector__XXX
   SG_ EPBL_a110_GTW_MIA m1 : 53|1@1+ (1,0) [0|0] "" Vector__XXX
   SG_ EPBL_a111_EPBR_MIA m1 : 54|1@1+ (1,0) [0|0] "" Vector__XXX
   SG_ EPBL_a112_EPBL_MIA m1 : 55|1@1+ (1,0) [0|0] "" Vector__XXX
   SG_ EPBL_a113_UI_MIA m1 : 56|1@1+ (1,0) [0|0] "" Vector__XXX
   SG_ EPBL_a114_ESP_MIA m1 : 57|1@1+ (1,0) [0|0] "" Vector__XXX
   SG_ EPBL_a115_VCSEC_MIA m1 : 58|1@1+ (1,0) [0|0] "" Vector__XXX
   SG_ EPBL_a116_VCRIGHT_MIA m1 : 59|1@1+ (1,0) [0|0] "" Vector__XXX
   SG_ EPBL_a117_VCLEFT_MIA m1 : 60|1@1+ (1,0) [0|0] "" Vector__XXX
   SG_ EPBL_a118_VCFRONT_MIA m1 : 61|1@1+ (1,0) [0|0] "" Vector__XXX
   SG_ EPBL_a119_SCCM_MIA m1 : 62|1@1+ (1,0) [0|0] "" Vector__XXX
   SG_ EPBL_a120_DI_DRIVE_MIA m1 : 63|1@1+ (1,0) [0|0] "" Vector__XXX
   SG_ EPBL_a121_nDriveFault m2 : 4|1@1+ (1,0) [0|0] "" Vector__XXX
   SG_ EPBL_a122_Oc m2 : 5|1@1+ (1,0) [0|0] "" Vector__XXX
   SG_ EPBL_a123_Uc m2 : 6|1@1+ (1,0) [0|0] "" Vector__XXX
   SG_ EPBL_a124_calOutOfBounds m2 : 7|1@1+ (1,0) [0|0] "" Vector__XXX
   SG_ EPBL_a125_IdleVMismatch m2 : 8|1@1+ (1,0) [0|0] "" Vector__XXX
   SG_ EPBL_a126_MotorNVoltLow m2 : 9|1@1+ (1,0) [0|0] "" Vector__XXX
   SG_ EPBL_a127_MotorNVoltHigh m2 : 10|1@1+ (1,0) [0|0] "" Vector__XXX
   SG_ EPBL_a128_MotorPVoltHigh m2 : 11|1@1+ (1,0) [0|0] "" Vector__XXX
   SG_ EPBL_a134_NvOv m2 : 17|1@1+ (1,0) [0|0] "" Vector__XXX
   SG_ EPBL_a135_NvUv m2 : 18|1@1+ (1,0) [0|0] "" Vector__XXX
   SG_ EPBL_a136_PvOv m2 : 19|1@1+ (1,0) [0|0] "" Vector__XXX
   SG_ EPBL_a137_PvUv m2 : 20|1@1+ (1,0) [0|0] "" Vector__XXX
   SG_ EPBL_a138_NVMWriteTime m2 : 21|1@1+ (1,0) [0|0] "" Vector__XXX
   SG_ EPBL_a141_invalidState m2 : 24|1@1+ (1,0) [0|0] "" Vector__XXX
   SG_ EPBL_a170_12vOv m2 : 53|1@1+ (1,0) [0|0] "" Vector__XXX
   SG_ EPBL_a171_12vUv m2 : 54|1@1+ (1,0) [0|0] "" Vector__XXX
   SG_ EPBL_a172_SPI_MIA m2 : 55|1@1+ (1,0) [0|0] "" Vector__XXX
   SG_ EPBL_a173_hiCurrentMissing m2 : 56|1@1+ (1,0) [0|0] "" Vector__XXX
   SG_ EPBL_a174_csmReleaseFailed m2 : 57|1@1+ (1,0) [0|0] "" Vector__XXX
   SG_ EPBL_a175_csmReleaseRetry m2 : 58|1@1+ (1,0) [0|0] "" Vector__XXX
   SG_ EPBL_a176_csmApplyFailed m2 : 59|1@1+ (1,0) [0|0] "" Vector__XXX
   SG_ EPBL_a177_csmApplyRetry m2 : 60|1@1+ (1,0) [0|0] "" Vector__XXX
   SG_ EPBL_a178_caliperStateUnknown m2 : 61|1@1+ (1,0) [0|0] "" Vector__XXX
   SG_ EPBL_a179_epbProblem m2 : 62|1@1+ (1,0) [0|0] "" Vector__XXX
   SG_ EPBL_a180_dynamicActive m2 : 63|1@1+ (1,0) [0|0] "" Vector__XXX
   SG_ EPBL_a181_TooSteepGradeToPark m3 : 4|1@1+ (1,0) [0|0] "" Vector__XXX
   SG_ EPBL_a182_OneEPBAppliedUnsecEnv m3 : 5|1@1+ (1,0) [0|0] "" Vector__XXX
   SG_ EPBL_a183_cdpNotAvailable m3 : 6|1@1+ (1,0) [0|0] "" Vector__XXX
   SG_ EPBL_a184_dynamicParkAbort m3 : 7|1@1+ (1,0) [0|0] "" Vector__XXX
   SG_ EPBL_a185_summonAborted m3 : 8|1@1+ (1,0) [0|0] "" Vector__XXX
   SG_ EPBL_a186_externalParkAbort m3 : 9|1@1+ (1,0) [0|0] "" Vector__XXX
   SG_ EPBL_a187_cdpDynamic m3 : 10|1@1+ (1,0) [0|0] "" Vector__XXX
   SG_ EPBL_a188_epbDynamic m3 : 11|1@1+ (1,0) [0|0] "" Vector__XXX
   SG_ EPBL_a189_epbDynamicParkCanceled m3 : 12|1@1+ (1,0) [0|0] "" Vector__XXX
   SG_ EPBL_a190_csmApplyDegraded m3 : 13|1@1+ (1,0) [0|0] "" Vector__XXX
   SG_ EPBL_a191_csmReleaseDegraded m3 : 14|1@1+ (1,0) [0|0] "" Vector__XXX
   SG_ EPBL_a195_parkForDriverIsLeaving m3 : 18|1@1+ (1,0) [0|0] "" Vector__XXX
   SG_ EPBL_a200_PmUnparkNotAllowed m3 : 23|1@1+ (1,0) [0|0] "" Vector__XXX
   SG_ EPBL_a201_hwBrakeTypeMismatch m3 : 24|1@1+ (1,0) [0|0] "" Vector__XXX
   SG_ EPBL_a216_SPI_MIA_debugData1 m3 : 39|1@1+ (1,0) [0|0] "" Vector__XXX
   SG_ EPBL_a217_SPI_MIA_debugData2 m3 : 40|1@1+ (1,0) [0|0] "" Vector__XXX
   SG_ EPBL_a241_diOutputLocked m4 : 4|1@1+ (1,0) [0|0] "" Vector__XXX
   SG_ EPBL_a242_hvOutputLocked m4 : 5|1@1+ (1,0) [0|0] "" Vector__XXX
   SG_ EPBL_a243_bdwUnavailable m4 : 6|1@1+ (1,0) [0|0] "" Vector__XXX
   SG_ EPBL_a244_WinchModeActive m4 : 7|1@1+ (1,0) [0|0] "" Vector__XXX
   SG_ EPBL_a245_serviceModeActive m4 : 8|1@1+ (1,0) [0|0] "" Vector__XXX
   SG_ EPBL_a246_idleFaultApply m4 : 9|1@1+ (1,0) [0|0] "" Vector__XXX
   SG_ EPBL_a247_csmDynamicApplyRetry m4 : 10|1@1+ (1,0) [0|0] "" Vector__XXX
   SG_ EPBL_a248_csmDynamicApplyFailed m4 : 11|1@1+ (1,0) [0|0] "" Vector__XXX
   SG_ EPBL_a249_idleFaultRelease m4 : 12|1@1+ (1,0) [0|0] "" Vector__XXX
   SG_ EPBL_a250_WinchModeCanceled m4 : 13|1@1+ (1,0) [0|0] "" Vector__XXX
   SG_ EPBL_a251_currentVarianceHigh m4 : 14|1@1+ (1,0) [0|0] "" Vector__XXX

BO_ 1992 EPBL_info: 8 Vector__XXX
   SG_ EPBL_infoIndex M : 0|8@1+ (1,0) [0|0] "" Vector__XXX
   SG_ EPBL_infoBuildType m10 : 8|3@1+ (1,0) [0|0] "" Vector__XXX
   SG_ EPBL_infoBuildConfigId m10 : 16|16@1+ (1,0) [0|0] "" Vector__XXX
   SG_ EPBL_infoHardwareId m10 : 32|16@1+ (1,0) [0|0] "" Vector__XXX
   SG_ EPBL_infoComponentId m10 : 48|16@1+ (1,0) [0|0] "" Vector__XXX
   SG_ EPBL_infoPcbaId m11 : 8|8@1+ (1,0) [0|0] "" Vector__XXX
   SG_ EPBL_infoAssemblyId m11 : 16|8@1+ (1,0) [0|0] "" Vector__XXX
   SG_ EPBL_infoUsageId m11 : 24|16@1+ (1,0) [0|0] "" Vector__XXX
   SG_ EPBL_infoSubUsageId m11 : 40|16@1+ (1,0) [0|0] "" Vector__XXX
   SG_ EPBL_infoAppCrc m13 : 8|32@1+ (1,0) [0|0] "" Vector__XXX
   SG_ EPBL_infoAppGitHash m17 : 10|54@1+ (4,0) [0|0] "" Vector__XXX
   SG_ EPBL_infoBootGitHash m18 : 10|54@1+ (4,0) [0|0] "" Vector__XXX
   SG_ EPBL_infoPlatformType m19 : 8|8@1+ (1,0) [0|0] "" Vector__XXX
   SG_ EPBL_infoBootUdsProtoVersion m20 : 8|16@1+ (1,0) [0|0] "" Vector__XXX
   SG_ EPBL_infoBootCrc m20 : 24|32@1+ (1,0) [0|0] "" Vector__XXX

BO_ 648 EPBL_internalStatus: 8 Vector__XXX
   SG_ EPBL_12VFilt : 37|12@1+ (0.00544368,0) [0|0] "V" Vector__XXX
   SG_ EPBL_csmFaultReason : 21|5@1+ (1,0) [0|0] "" Vector__XXX
   SG_ EPBL_disconnected : 10|1@1+ (1,0) [0|0] "" Vector__XXX
   SG_ EPBL_epbmCDPQualified : 49|2@1+ (1,0) [0|0] "" Vector__XXX
   SG_ EPBL_esmCaliperRequest : 18|3@1+ (1,0) [0|0] "" Vector__XXX
   SG_ EPBL_esmOperationTrigger : 26|5@1+ (1,0) [0|0] "" Vector__XXX
   SG_ EPBL_internalCDPRequest : 51|1@1+ (1,0) [0|0] "" Vector__XXX
   SG_ EPBL_internalStatusChecksum : 56|8@1+ (1,0) [0|0] "" Vector__XXX
   SG_ EPBL_internalStatusCounter : 52|4@1+ (1,0) [0|0] "" Vector__XXX
   SG_ EPBL_localServiceModeActive : 36|1@1+ (1,0) [0|0] "" Vector__XXX
   SG_ EPBL_lockoutUnlockCount : 11|7@1+ (1,0) [0|0] "" Vector__XXX
   SG_ EPBL_summonFaultReason : 31|5@1+ (1,0) [0|0] "" Vector__XXX
   SG_ EPBL_summonState : 7|3@1+ (1,0) [0|0] "" Vector__XXX
   SG_ EPBL_unitFaultStatus : 5|2@1+ (1,0) [0|0] "" Vector__XXX
   SG_ EPBL_unitStatus : 0|5@1+ (1,0) [0|0] "" Vector__XXX

BO_ 681 EPBL_status: 8 Vector__XXX
   SG_ EPBL_blockDrive : 51|1@1+ (1,0) [0|0] "" Vector__XXX
   SG_ EPBL_bothDisconnected : 50|1@1+ (1,0) [0|0] "" Vector__XXX
   SG_ EPBL_brakeDiscWipeRequest : 30|2@1+ (1,0) [0|0] "" Vector__XXX
   SG_ EPBL_brakeHWConfigMismatch : 19|1@1+ (1,0) [0|0] "" Vector__XXX
   SG_ EPBL_brakeLight : 18|1@1+ (1,0) [0|0] "" Vector__XXX
   SG_ EPBL_cdpRequest : 27|1@1+ (1,0) [0|0] "" Vector__XXX
   SG_ EPBL_espPowerRequest : 46|1@1+ (1,0) [0|0] "" Vector__XXX
   SG_ EPBL_hornRequest : 48|1@1+ (1,0) [0|0] "" Vector__XXX
   SG_ EPBL_okToPark : 47|1@1+ (1,0) [0|0] "" Vector__XXX
   SG_ EPBL_requestUserConfirmation : 21|1@1+ (1,0) [0|0] "" Vector__XXX
   SG_ EPBL_statusChecksum : 56|8@1+ (1,0) [0|0] "" Vector__XXX
   SG_ EPBL_statusCounter : 52|4@1+ (1,0) [0|0] "" Vector__XXX
   SG_ EPBL_summonEnabled : 17|1@1+ (1,0) [0|0] "" Vector__XXX
   SG_ EPBL_systemStatus : 0|4@1+ (1,0) [0|0] "" Vector__XXX
   SG_ EPBL_telltale : 16|1@1+ (1,0) [0|0] "" Vector__XXX
   SG_ EPBL_uiButtonAvailable : 20|1@1+ (1,0) [0|0] "" Vector__XXX
   SG_ EPBL_updateMode : 24|1@1+ (1,0) [0|0] "" Vector__XXX
   SG_ EPBL_winchModeActive : 23|1@1+ (1,0) [0|0] "" Vector__XXX
   SG_ EPBL_winchModeAvailable : 49|1@1+ (1,0) [0|0] "" Vector__XXX
   SG_ EPBL_winchModeTimer : 32|12@1+ (1,0) [0|0] "" Vector__XXX

BO_ 1573 EPBL_udsResponse: 8 Vector__XXX
   SG_ EPBL_udsResponseData_H : 0|32@0+ (1,0) [0|0] "" Vector__XXX
   SG_ EPBL_udsResponseData_L : 32|32@0+ (1,0) [0|0] "" Vector__XXX

BO_ 1000 EPBR_alertMatrix: 8 Vector__XXX
   SG_ EPBR_matrixIndex M : 0|4@1+ (1,0) [0|0] "" Vector__XXX
   SG_ EPBR_a001_WatchdogReset m0 : 4|1@1+ (1,0) [0|0] "" Vector__XXX
   SG_ EPBR_a002_PowerLossReset m0 : 5|1@1+ (1,0) [0|0] "" Vector__XXX
   SG_ EPBR_a003_SWAssertion m0 : 6|1@1+ (1,0) [0|0] "" Vector__XXX
   SG_ EPBR_a010_ExtSupplyVoltError m0 : 13|1@1+ (1,0) [0|0] "" Vector__XXX
   SG_ EPBR_a012_CPUReset m0 : 15|1@1+ (1,0) [0|0] "" Vector__XXX
   SG_ EPBR_a013_AlertManagerFault m0 : 16|1@1+ (1,0) [0|0] "" Vector__XXX
   SG_ EPBR_a015_NVMMAlert m0 : 18|1@1+ (1,0) [0|0] "" Vector__XXX
   SG_ EPBR_a021_TaskSchedulerError m0 : 24|1@1+ (1,0) [0|0] "" Vector__XXX
   SG_ EPBR_a022_TaskInitError m0 : 25|1@1+ (1,0) [0|0] "" Vector__XXX
   SG_ EPBR_a031_UDSActive m0 : 34|1@1+ (1,0) [0|0] "" Vector__XXX
   SG_ EPBR_a041_HighCPULoad m0 : 44|1@1+ (1,0) [0|0] "" Vector__XXX
   SG_ EPBR_a042_HighStackUsage m0 : 45|1@1+ (1,0) [0|0] "" Vector__XXX
   SG_ EPBR_a043_Task1msError m0 : 46|1@1+ (1,0) [0|0] "" Vector__XXX
   SG_ EPBR_a044_Task10msError m0 : 47|1@1+ (1,0) [0|0] "" Vector__XXX
   SG_ EPBR_a045_Task100msError m0 : 48|1@1+ (1,0) [0|0] "" Vector__XXX
   SG_ EPBR_a046_Task1000msError m0 : 49|1@1+ (1,0) [0|0] "" Vector__XXX
   SG_ EPBR_a059_inputResistanceHigh m0 : 62|1@1+ (1,0) [0|0] "" Vector__XXX
   SG_ EPBR_a060_engineeringBuild m0 : 63|1@1+ (1,0) [0|0] "" Vector__XXX
   SG_ EPBR_a061_XCPConnected m1 : 4|1@1+ (1,0) [0|0] "" Vector__XXX
   SG_ EPBR_a062_XCPWasConnected m1 : 5|1@1+ (1,0) [0|0] "" Vector__XXX
   SG_ EPBR_a063_SwitchFault m1 : 6|1@1+ (1,0) [0|0] "" Vector__XXX
   SG_ EPBR_a064_busSleepReqTimeout m1 : 7|1@1+ (1,0) [0|0] "" Vector__XXX
   SG_ EPBR_a097_CMP_MIA m1 : 40|1@1+ (1,0) [0|0] "" Vector__XXX
   SG_ EPBR_a098_DI_THERMAL_MIA m1 : 41|1@1+ (1,0) [0|0] "" Vector__XXX
   SG_ EPBR_a099_PARK_MIA m1 : 42|1@1+ (1,0) [0|0] "" Vector__XXX
   SG_ EPBR_a100_CANbus_MIA m1 : 43|1@1+ (1,0) [0|0] "" Vector__XXX
   SG_ EPBR_a101_PM_MIA m1 : 44|1@1+ (1,0) [0|0] "" Vector__XXX
   SG_ EPBR_a102_PTC_MIA m1 : 45|1@1+ (1,0) [0|0] "" Vector__XXX
   SG_ EPBR_a103_CP_MIA m1 : 46|1@1+ (1,0) [0|0] "" Vector__XXX
   SG_ EPBR_a104_DAS_MIA m1 : 47|1@1+ (1,0) [0|0] "" Vector__XXX
   SG_ EPBR_a105_TAS_MIA m1 : 48|1@1+ (1,0) [0|0] "" Vector__XXX
   SG_ EPBR_a106_PCS_MIA m1 : 49|1@1+ (1,0) [0|0] "" Vector__XXX
   SG_ EPBR_a107_BMS_MIA m1 : 50|1@1+ (1,0) [0|0] "" Vector__XXX
   SG_ EPBR_a108_DIS_MIA m1 : 51|1@1+ (1,0) [0|0] "" Vector__XXX
   SG_ EPBR_a109_RCM_MIA m1 : 52|1@1+ (1,0) [0|0] "" Vector__XXX
   SG_ EPBR_a110_GTW_MIA m1 : 53|1@1+ (1,0) [0|0] "" Vector__XXX
   SG_ EPBR_a111_EPBR_MIA m1 : 54|1@1+ (1,0) [0|0] "" Vector__XXX
   SG_ EPBR_a112_EPBL_MIA m1 : 55|1@1+ (1,0) [0|0] "" Vector__XXX
   SG_ EPBR_a113_UI_MIA m1 : 56|1@1+ (1,0) [0|0] "" Vector__XXX
   SG_ EPBR_a114_ESP_MIA m1 : 57|1@1+ (1,0) [0|0] "" Vector__XXX
   SG_ EPBR_a115_VCSEC_MIA m1 : 58|1@1+ (1,0) [0|0] "" Vector__XXX
   SG_ EPBR_a116_VCRIGHT_MIA m1 : 59|1@1+ (1,0) [0|0] "" Vector__XXX
   SG_ EPBR_a117_VCLEFT_MIA m1 : 60|1@1+ (1,0) [0|0] "" Vector__XXX
   SG_ EPBR_a118_VCFRONT_MIA m1 : 61|1@1+ (1,0) [0|0] "" Vector__XXX
   SG_ EPBR_a119_SCCM_MIA m1 : 62|1@1+ (1,0) [0|0] "" Vector__XXX
   SG_ EPBR_a120_DI_DRIVE_MIA m1 : 63|1@1+ (1,0) [0|0] "" Vector__XXX
   SG_ EPBR_a121_nDriveFault m2 : 4|1@1+ (1,0) [0|0] "" Vector__XXX
   SG_ EPBR_a122_Oc m2 : 5|1@1+ (1,0) [0|0] "" Vector__XXX
   SG_ EPBR_a123_Uc m2 : 6|1@1+ (1,0) [0|0] "" Vector__XXX
   SG_ EPBR_a124_calOutOfBounds m2 : 7|1@1+ (1,0) [0|0] "" Vector__XXX
   SG_ EPBR_a125_IdleVMismatch m2 : 8|1@1+ (1,0) [0|0] "" Vector__XXX
   SG_ EPBR_a126_MotorNVoltLow m2 : 9|1@1+ (1,0) [0|0] "" Vector__XXX
   SG_ EPBR_a127_MotorNVoltHigh m2 : 10|1@1+ (1,0) [0|0] "" Vector__XXX
   SG_ EPBR_a128_MotorPVoltHigh m2 : 11|1@1+ (1,0) [0|0] "" Vector__XXX
   SG_ EPBR_a134_NvOv m2 : 17|1@1+ (1,0) [0|0] "" Vector__XXX
   SG_ EPBR_a135_NvUv m2 : 18|1@1+ (1,0) [0|0] "" Vector__XXX
   SG_ EPBR_a136_PvOv m2 : 19|1@1+ (1,0) [0|0] "" Vector__XXX
   SG_ EPBR_a137_PvUv m2 : 20|1@1+ (1,0) [0|0] "" Vector__XXX
   SG_ EPBR_a138_NVMWriteTime m2 : 21|1@1+ (1,0) [0|0] "" Vector__XXX
   SG_ EPBR_a141_invalidState m2 : 24|1@1+ (1,0) [0|0] "" Vector__XXX
   SG_ EPBR_a170_12vOv m2 : 53|1@1+ (1,0) [0|0] "" Vector__XXX
   SG_ EPBR_a171_12vUv m2 : 54|1@1+ (1,0) [0|0] "" Vector__XXX
   SG_ EPBR_a172_SPI_MIA m2 : 55|1@1+ (1,0) [0|0] "" Vector__XXX
   SG_ EPBR_a173_hiCurrentMissing m2 : 56|1@1+ (1,0) [0|0] "" Vector__XXX
   SG_ EPBR_a174_csmReleaseFailed m2 : 57|1@1+ (1,0) [0|0] "" Vector__XXX
   SG_ EPBR_a175_csmReleaseRetry m2 : 58|1@1+ (1,0) [0|0] "" Vector__XXX
   SG_ EPBR_a176_csmApplyFailed m2 : 59|1@1+ (1,0) [0|0] "" Vector__XXX
   SG_ EPBR_a177_csmApplyRetry m2 : 60|1@1+ (1,0) [0|0] "" Vector__XXX
   SG_ EPBR_a178_caliperStateUnknown m2 : 61|1@1+ (1,0) [0|0] "" Vector__XXX
   SG_ EPBR_a179_epbProblem m2 : 62|1@1+ (1,0) [0|0] "" Vector__XXX
   SG_ EPBR_a180_dynamicActive m2 : 63|1@1+ (1,0) [0|0] "" Vector__XXX
   SG_ EPBR_a181_TooSteepGradeToPark m3 : 4|1@1+ (1,0) [0|0] "" Vector__XXX
   SG_ EPBR_a182_OneEPBAppliedUnsecEnv m3 : 5|1@1+ (1,0) [0|0] "" Vector__XXX
   SG_ EPBR_a183_cdpNotAvailable m3 : 6|1@1+ (1,0) [0|0] "" Vector__XXX
   SG_ EPBR_a184_dynamicParkAbort m3 : 7|1@1+ (1,0) [0|0] "" Vector__XXX
   SG_ EPBR_a185_summonAborted m3 : 8|1@1+ (1,0) [0|0] "" Vector__XXX
   SG_ EPBR_a186_externalParkAbort m3 : 9|1@1+ (1,0) [0|0] "" Vector__XXX
   SG_ EPBR_a187_cdpDynamic m3 : 10|1@1+ (1,0) [0|0] "" Vector__XXX
   SG_ EPBR_a188_epbDynamic m3 : 11|1@1+ (1,0) [0|0] "" Vector__XXX
   SG_ EPBR_a189_epbDynamicParkCanceled m3 : 12|1@1+ (1,0) [0|0] "" Vector__XXX
   SG_ EPBR_a190_csmApplyDegraded m3 : 13|1@1+ (1,0) [0|0] "" Vector__XXX
   SG_ EPBR_a191_csmReleaseDegraded m3 : 14|1@1+ (1,0) [0|0] "" Vector__XXX
   SG_ EPBR_a195_parkForDriverIsLeaving m3 : 18|1@1+ (1,0) [0|0] "" Vector__XXX
   SG_ EPBR_a200_PmUnparkNotAllowed m3 : 23|1@1+ (1,0) [0|0] "" Vector__XXX
   SG_ EPBR_a201_hwBrakeTypeMismatch m3 : 24|1@1+ (1,0) [0|0] "" Vector__XXX
   SG_ EPBR_a216_SPI_MIA_debugData1 m3 : 39|1@1+ (1,0) [0|0] "" Vector__XXX
   SG_ EPBR_a217_SPI_MIA_debugData2 m3 : 40|1@1+ (1,0) [0|0] "" Vector__XXX
   SG_ EPBR_a241_diOutputLocked m4 : 4|1@1+ (1,0) [0|0] "" Vector__XXX
   SG_ EPBR_a242_hvOutputLocked m4 : 5|1@1+ (1,0) [0|0] "" Vector__XXX
   SG_ EPBR_a243_bdwUnavailable m4 : 6|1@1+ (1,0) [0|0] "" Vector__XXX
   SG_ EPBR_a244_WinchModeActive m4 : 7|1@1+ (1,0) [0|0] "" Vector__XXX
   SG_ EPBR_a245_serviceModeActive m4 : 8|1@1+ (1,0) [0|0] "" Vector__XXX
   SG_ EPBR_a246_idleFaultApply m4 : 9|1@1+ (1,0) [0|0] "" Vector__XXX
   SG_ EPBR_a247_csmDynamicApplyRetry m4 : 10|1@1+ (1,0) [0|0] "" Vector__XXX
   SG_ EPBR_a248_csmDynamicApplyFailed m4 : 11|1@1+ (1,0) [0|0] "" Vector__XXX
   SG_ EPBR_a249_idleFaultRelease m4 : 12|1@1+ (1,0) [0|0] "" Vector__XXX
   SG_ EPBR_a250_WinchModeCanceled m4 : 13|1@1+ (1,0) [0|0] "" Vector__XXX
   SG_ EPBR_a251_currentVarianceHigh m4 : 14|1@1+ (1,0) [0|0] "" Vector__XXX

BO_ 2024 EPBR_info: 8 Vector__XXX
   SG_ EPBR_infoIndex M : 0|8@1+ (1,0) [0|0] "" Vector__XXX
   SG_ EPBR_infoBuildType m10 : 8|3@1+ (1,0) [0|0] "" Vector__XXX
   SG_ EPBR_infoBuildConfigId m10 : 16|16@1+ (1,0) [0|0] "" Vector__XXX
   SG_ EPBR_infoHardwareId m10 : 32|16@1+ (1,0) [0|0] "" Vector__XXX
   SG_ EPBR_infoComponentId m10 : 48|16@1+ (1,0) [0|0] "" Vector__XXX
   SG_ EPBR_infoPcbaId m11 : 8|8@1+ (1,0) [0|0] "" Vector__XXX
   SG_ EPBR_infoAssemblyId m11 : 16|8@1+ (1,0) [0|0] "" Vector__XXX
   SG_ EPBR_infoUsageId m11 : 24|16@1+ (1,0) [0|0] "" Vector__XXX
   SG_ EPBR_infoSubUsageId m11 : 40|16@1+ (1,0) [0|0] "" Vector__XXX
   SG_ EPBR_infoAppCrc m13 : 8|32@1+ (1,0) [0|0] "" Vector__XXX
   SG_ EPBR_infoAppGitHash m17 : 10|54@1+ (4,0) [0|0] "" Vector__XXX
   SG_ EPBR_infoBootGitHash m18 : 10|54@1+ (4,0) [0|0] "" Vector__XXX
   SG_ EPBR_infoPlatformType m19 : 8|8@1+ (1,0) [0|0] "" Vector__XXX
   SG_ EPBR_infoBootUdsProtoVersion m20 : 8|16@1+ (1,0) [0|0] "" Vector__XXX
   SG_ EPBR_infoBootCrc m20 : 24|32@1+ (1,0) [0|0] "" Vector__XXX

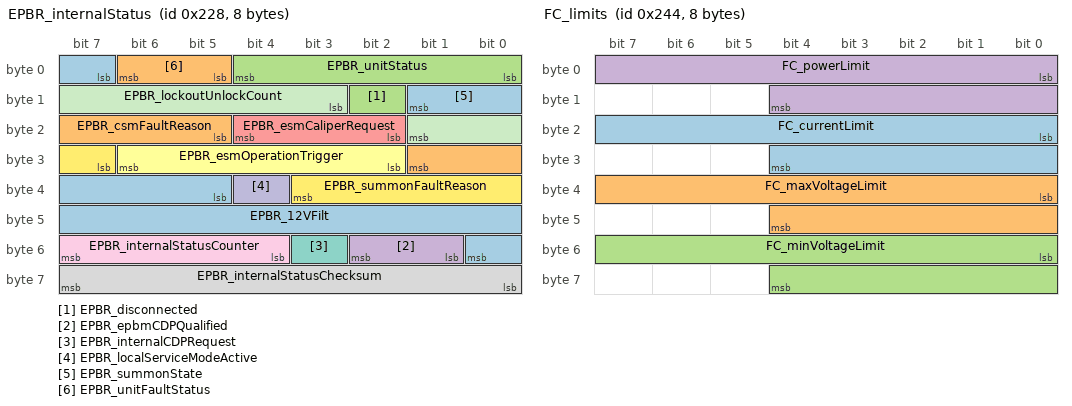
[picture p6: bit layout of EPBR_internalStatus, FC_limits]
BO_ 552 EPBR_internalStatus: 8 Vector__XXX
   SG_ EPBR_12VFilt : 37|12@1+ (0.00544368,0) [0|0] "V" Vector__XXX
   SG_ EPBR_csmFaultReason : 21|5@1+ (1,0) [0|0] "" Vector__XXX
   SG_ EPBR_disconnected : 10|1@1+ (1,0) [0|0] "" Vector__XXX
   SG_ EPBR_epbmCDPQualified : 49|2@1+ (1,0) [0|0] "" Vector__XXX
   SG_ EPBR_esmCaliperRequest : 18|3@1+ (1,0) [0|0] "" Vector__XXX
   SG_ EPBR_esmOperationTrigger : 26|5@1+ (1,0) [0|0] "" Vector__XXX
   SG_ EPBR_internalCDPRequest : 51|1@1+ (1,0) [0|0] "" Vector__XXX
   SG_ EPBR_internalStatusChecksum : 56|8@1+ (1,0) [0|0] "" Vector__XXX
   SG_ EPBR_internalStatusCounter : 52|4@1+ (1,0) [0|0] "" Vector__XXX
   SG_ EPBR_localServiceModeActive : 36|1@1+ (1,0) [0|0] "" Vector__XXX
   SG_ EPBR_lockoutUnlockCount : 11|7@1+ (1,0) [0|0] "" Vector__XXX
   SG_ EPBR_summonFaultReason : 31|5@1+ (1,0) [0|0] "" Vector__XXX
   SG_ EPBR_summonState : 7|3@1+ (1,0) [0|0] "" Vector__XXX
   SG_ EPBR_unitFaultStatus : 5|2@1+ (1,0) [0|0] "" Vector__XXX
   SG_ EPBR_unitStatus : 0|5@1+ (1,0) [0|0] "" Vector__XXX

BO_ 744 EPBR_status: 8 Vector__XXX
   SG_ EPBR_blockDrive : 51|1@1+ (1,0) [0|0] "" Vector__XXX
   SG_ EPBR_bothDisconnected : 50|1@1+ (1,0) [0|0] "" Vector__XXX
   SG_ EPBR_brakeDiscWipeRequest : 30|2@1+ (1,0) [0|0] "" Vector__XXX
   SG_ EPBR_brakeHWConfigMismatch : 19|1@1+ (1,0) [0|0] "" Vector__XXX
   SG_ EPBR_brakeLight : 18|1@1+ (1,0) [0|0] "" Vector__XXX
   SG_ EPBR_cdpRequest : 27|1@1+ (1,0) [0|0] "" Vector__XXX
   SG_ EPBR_espPowerRequest : 46|1@1+ (1,0) [0|0] "" Vector__XXX
   SG_ EPBR_hornRequest : 48|1@1+ (1,0) [0|0] "" Vector__XXX
   SG_ EPBR_okToPark : 47|1@1+ (1,0) [0|0] "" Vector__XXX
   SG_ EPBR_requestUserConfirmation : 21|1@1+ (1,0) [0|0] "" Vector__XXX
   SG_ EPBR_statusChecksum : 56|8@1+ (1,0) [0|0] "" Vector__XXX
   SG_ EPBR_statusCounter : 52|4@1+ (1,0) [0|0] "" Vector__XXX
   SG_ EPBR_summonEnabled : 17|1@1+ (1,0) [0|0] "" Vector__XXX
   SG_ EPBR_systemStatus : 0|4@1+ (1,0) [0|0] "" Vector__XXX
   SG_ EPBR_telltale : 16|1@1+ (1,0) [0|0] "" Vector__XXX
   SG_ EPBR_uiButtonAvailable : 20|1@1+ (1,0) [0|0] "" Vector__XXX
   SG_ EPBR_updateMode : 24|1@1+ (1,0) [0|0] "" Vector__XXX
   SG_ EPBR_winchModeActive : 23|1@1+ (1,0) [0|0] "" Vector__XXX
   SG_ EPBR_winchModeAvailable : 49|1@1+ (1,0) [0|0] "" Vector__XXX
   SG_ EPBR_winchModeTimer : 32|12@1+ (1,0) [0|0] "" Vector__XXX

BO_ 1575 EPBR_udsResponse: 8 Vector__XXX
   SG_ EPBR_udsResponseData_H : 0|32@0+ (1,0) [0|0] "" Vector__XXX
   SG_ EPBR_udsResponseData_L : 32|32@0+ (1,0) [0|0] "" Vector__XXX

BO_ 981 ESP_alertMatrix: 8 Vector__XXX
   SG_ ESP_matrixIndex M : 0|4@1+ (1,0) [0|0] "" Vector__XXX
   SG_ ESP_a001_ecuGenericFault m0 : 4|1@1+ (1,0) [0|0] "" Vector__XXX
   SG_ ESP_a002_valvesGenericFault m0 : 5|1@1+ (1,0) [0|0] "" Vector__XXX
   SG_ ESP_a003_outletValvesFault m0 : 6|1@1+ (1,0) [0|0] "" Vector__XXX
   SG_ ESP_a004_inletValvesFault m0 : 7|1@1+ (1,0) [0|0] "" Vector__XXX
   SG_ ESP_a005_HSVValvesFault m0 : 8|1@1+ (1,0) [0|0] "" Vector__XXX
   SG_ ESP_a006_USVValvesFault m0 : 9|1@1+ (1,0) [0|0] "" Vector__XXX
   SG_ ESP_a007_pumpMotorFault m0 : 10|1@1+ (1,0) [0|0] "" Vector__XXX
   SG_ ESP_a008_pumpMotor12VsupplyLow m0 : 11|1@1+ (1,0) [0|0] "" Vector__XXX
   SG_ ESP_a009_12VHardUndervoltage m0 : 12|1@1+ (1,0) [0|0] "" Vector__XXX
   SG_ ESP_a010_12VUndervoltage m0 : 13|1@1+ (1,0) [0|0] "" Vector__XXX
   SG_ ESP_a011_12VSystemUndervoltage m0 : 14|1@1+ (1,0) [0|0] "" Vector__XXX
   SG_ ESP_a012_netUndervoltage m0 : 15|1@1+ (1,0) [0|0] "" Vector__XXX
   SG_ ESP_a013_valveRelayUndervoltage m0 : 16|1@1+ (1,0) [0|0] "" Vector__XXX
   SG_ ESP_a014_WSSSupplyUndervoltage m0 : 17|1@1+ (1,0) [0|0] "" Vector__XXX
   SG_ ESP_a015_12VSupplyOvervoltage m0 : 18|1@1+ (1,0) [0|0] "" Vector__XXX
   SG_ ESP_a016_12VSystemOvervoltage m0 : 19|1@1+ (1,0) [0|0] "" Vector__XXX
   SG_ ESP_a017_netOvervoltage m0 : 20|1@1+ (1,0) [0|0] "" Vector__XXX
   SG_ ESP_a018_WSSSignFrontAxle m0 : 21|1@1+ (1,0) [0|0] "" Vector__XXX
   SG_ ESP_a019_WSSSignRearAxle m0 : 22|1@1+ (1,0) [0|0] "" Vector__XXX
   SG_ ESP_a020_WSSGenericTempFault m0 : 23|1@1+ (1,0) [0|0] "" Vector__XXX
   SG_ ESP_a021_WSSGeneralVDiffFault m0 : 24|1@1+ (1,0) [0|0] "" Vector__XXX
   SG_ ESP_a022_WSSDirectionFault m0 : 25|1@1+ (1,0) [0|0] "" Vector__XXX
   SG_ ESP_a023_WSSSeveralSuspected m0 : 26|1@1+ (1,0) [0|0] "" Vector__XXX
   SG_ ESP_a024_WSSReverseCurrent m0 : 27|1@1+ (1,0) [0|0] "" Vector__XXX
   SG_ ESP_a025_FrLWSSOpenOrShortToGnd m0 : 28|1@1+ (1,0) [0|0] "" Vector__XXX
   SG_ ESP_a026_FrLWSSShortTo12V m0 : 29|1@1+ (1,0) [0|0] "" Vector__XXX
   SG_ ESP_a027_FrLWSSLineInterruption m0 : 30|1@1+ (1,0) [0|0] "" Vector__XXX
   SG_ ESP_a028_FrLWSSMaxSpeedExceeded m0 : 31|1@1+ (1,0) [0|0] "" Vector__XXX
   SG_ ESP_a029_FrLWSSTooManyPulses m0 : 32|1@1+ (1,0) [0|0] "" Vector__XXX
   SG_ ESP_a030_FrLWSSLostSignal m0 : 33|1@1+ (1,0) [0|0] "" Vector__XXX
   SG_ ESP_a031_FrLWSSNoPulsesDetected m0 : 34|1@1+ (1,0) [0|0] "" Vector__XXX
   SG_ ESP_a032_FrLWSSWrongSensorType m0 : 35|1@1+ (1,0) [0|0] "" Vector__XXX
   SG_ ESP_a033_FrLWSSSignalNoise m0 : 36|1@1+ (1,0) [0|0] "" Vector__XXX
   SG_ ESP_a034_FrLWSSVDiffFault m0 : 37|1@1+ (1,0) [0|0] "" Vector__XXX
   SG_ ESP_a035_FrLWSSDirectionFault m0 : 38|1@1+ (1,0) [0|0] "" Vector__XXX
   SG_ ESP_a036_FrLWSSLargeAirGap m0 : 39|1@1+ (1,0) [0|0] "" Vector__XXX
   SG_ ESP_a037_FrLWSSSupplyShortToGnd m0 : 40|1@1+ (1,0) [0|0] "" Vector__XXX
   SG_ ESP_a038_FrLWSSGeneralFault m0 : 41|1@1+ (1,0) [0|0] "" Vector__XXX
   SG_ ESP_a039_FrRWSSOpenOrShortToGnd m0 : 42|1@1+ (1,0) [0|0] "" Vector__XXX
   SG_ ESP_a040_FrRWSSShortTo12V m0 : 43|1@1+ (1,0) [0|0] "" Vector__XXX
   SG_ ESP_a041_FrRWSSLineInterruption m0 : 44|1@1+ (1,0) [0|0] "" Vector__XXX
   SG_ ESP_a042_FrRWSSMaxSpeedExceeded m0 : 45|1@1+ (1,0) [0|0] "" Vector__XXX
   SG_ ESP_a043_FrRWSSTooManyPulses m0 : 46|1@1+ (1,0) [0|0] "" Vector__XXX
   SG_ ESP_a044_FrRWSSLostSignal m0 : 47|1@1+ (1,0) [0|0] "" Vector__XXX
   SG_ ESP_a045_FrRWSSNoPulsesDetected m0 : 48|1@1+ (1,0) [0|0] "" Vector__XXX
   SG_ ESP_a046_FrRWSSWrongSensorType m0 : 49|1@1+ (1,0) [0|0] "" Vector__XXX
   SG_ ESP_a047_FrRWSSSignalNoise m0 : 50|1@1+ (1,0) [0|0] "" Vector__XXX
   SG_ ESP_a048_FrRWSSVDiffFault m0 : 51|1@1+ (1,0) [0|0] "" Vector__XXX
   SG_ ESP_a049_FrRWSSDirectionFault m0 : 52|1@1+ (1,0) [0|0] "" Vector__XXX
   SG_ ESP_a050_FrRWSSLargeAirGap m0 : 53|1@1+ (1,0) [0|0] "" Vector__XXX
   SG_ ESP_a051_FrRWSSSupplyShortToGnd m0 : 54|1@1+ (1,0) [0|0] "" Vector__XXX
   SG_ ESP_a052_FrRWSSGeneralFault m0 : 55|1@1+ (1,0) [0|0] "" Vector__XXX
   SG_ ESP_a053_ReLWSSOpenOrShortToGnd m0 : 56|1@1+ (1,0) [0|0] "" Vector__XXX
   SG_ ESP_a054_ReLWSSShortTo12V m0 : 57|1@1+ (1,0) [0|0] "" Vector__XXX
   SG_ ESP_a055_ReLWSSLineInterruption m0 : 58|1@1+ (1,0) [0|0] "" Vector__XXX
   SG_ ESP_a056_ReLWSSMaxSpeedExceeded m0 : 59|1@1+ (1,0) [0|0] "" Vector__XXX
   SG_ ESP_a057_ReLWSSTooManyPulses m0 : 60|1@1+ (1,0) [0|0] "" Vector__XXX
   SG_ ESP_a058_ReLWSSLostSignal m0 : 61|1@1+ (1,0) [0|0] "" Vector__XXX
   SG_ ESP_a059_ReLWSSNoPulsesDetected m0 : 62|1@1+ (1,0) [0|0] "" Vector__XXX
   SG_ ESP_a060_ReLWSSWrongSensorType m0 : 63|1@1+ (1,0) [0|0] "" Vector__XXX
   SG_ ESP_a061_ReLWSSSignalNoise m1 : 4|1@1+ (1,0) [0|0] "" Vector__XXX
   SG_ ESP_a062_ReLWSSVDiffFault m1 : 5|1@1+ (1,0) [0|0] "" Vector__XXX
   SG_ ESP_a063_ReLWSSDirectionFault m1 : 6|1@1+ (1,0) [0|0] "" Vector__XXX
   SG_ ESP_a064_ReLWSSLargeAirGap m1 : 7|1@1+ (1,0) [0|0] "" Vector__XXX
   SG_ ESP_a065_ReLWSSSupplyShortToGnd m1 : 8|1@1+ (1,0) [0|0] "" Vector__XXX
   SG_ ESP_a066_ReLWSSGeneralFault m1 : 9|1@1+ (1,0) [0|0] "" Vector__XXX
   SG_ ESP_a067_ReRWSSOpenOrShortToGnd m1 : 10|1@1+ (1,0) [0|0] "" Vector__XXX
   SG_ ESP_a068_ReRWSSShortTo12V m1 : 11|1@1+ (1,0) [0|0] "" Vector__XXX
   SG_ ESP_a069_ReRWSSLineInterruption m1 : 12|1@1+ (1,0) [0|0] "" Vector__XXX
   SG_ ESP_a070_ReRWSSMaxSpeedExceeded m1 : 13|1@1+ (1,0) [0|0] "" Vector__XXX
   SG_ ESP_a071_ReRWSSTooManyPulses m1 : 14|1@1+ (1,0) [0|0] "" Vector__XXX
   SG_ ESP_a072_ReRWSSLostSignal m1 : 15|1@1+ (1,0) [0|0] "" Vector__XXX
   SG_ ESP_a073_ReRWSSNoPulsesDetected m1 : 16|1@1+ (1,0) [0|0] "" Vector__XXX
   SG_ ESP_a074_ReRWSSWrongSensorType m1 : 17|1@1+ (1,0) [0|0] "" Vector__XXX
   SG_ ESP_a075_ReRWSSSignalNoise m1 : 18|1@1+ (1,0) [0|0] "" Vector__XXX
   SG_ ESP_a076_ReRWSSVDiffFault m1 : 19|1@1+ (1,0) [0|0] "" Vector__XXX
   SG_ ESP_a077_ReRWSSDirectionFault m1 : 20|1@1+ (1,0) [0|0] "" Vector__XXX
   SG_ ESP_a078_ReRWSSLargeAirGap m1 : 21|1@1+ (1,0) [0|0] "" Vector__XXX
   SG_ ESP_a079_ReRWSSSupplyShortToGnd m1 : 22|1@1+ (1,0) [0|0] "" Vector__XXX
   SG_ ESP_a080_ReRWSSGeneralFault m1 : 23|1@1+ (1,0) [0|0] "" Vector__XXX
   SG_ ESP_a081_PressureSensorShort m1 : 24|1@1+ (1,0) [0|0] "" Vector__XXX
   SG_ ESP_a082_PMCSensorOffsetHigh m1 : 25|1@1+ (1,0) [0|0] "" Vector__XXX
   SG_ ESP_a083_PMCSensorFault m1 : 26|1@1+ (1,0) [0|0] "" Vector__XXX
   SG_ ESP_a084_BrakeFluidReservoirLow m1 : 27|1@1+ (1,0) [0|0] "" Vector__XXX
   SG_ ESP_a085_BrakeSwitchStuckHigh m1 : 28|1@1+ (1,0) [0|0] "" Vector__XXX
   SG_ ESP_a086_BrakeSwitchImplausible1 m1 : 29|1@1+ (1,0) [0|0] "" Vector__XXX
   SG_ ESP_a087_BrakeSwitchImplausible3 m1 : 30|1@1+ (1,0) [0|0] "" Vector__XXX
   SG_ ESP_a088_absContinuousControl m1 : 31|1@1+ (1,0) [0|0] "" Vector__XXX
   SG_ ESP_a089_absNoPressureIncrease m1 : 32|1@1+ (1,0) [0|0] "" Vector__XXX
   SG_ ESP_a090_vdcContinuousControl m1 : 33|1@1+ (1,0) [0|0] "" Vector__XXX
   SG_ ESP_a091_CANUndervoltage m1 : 34|1@1+ (1,0) [0|0] "" Vector__XXX
   SG_ ESP_a092_CANOvervoltage m1 : 35|1@1+ (1,0) [0|0] "" Vector__XXX
   SG_ ESP_a093_partyBusOff m1 : 36|1@1+ (1,0) [0|0] "" Vector__XXX
   SG_ ESP_a094_partyBusPassive m1 : 37|1@1+ (1,0) [0|0] "" Vector__XXX
   SG_ ESP_a095_chassisBusOff m1 : 38|1@1+ (1,0) [0|0] "" Vector__XXX
   SG_ ESP_a096_chassisBusPassive m1 : 39|1@1+ (1,0) [0|0] "" Vector__XXX
   SG_ ESP_a097_tcsRefSpeedNotInit m1 : 40|1@1+ (1,0) [0|0] "" Vector__XXX
   SG_ ESP_a098_vdcRefSpeedNotInit m1 : 41|1@1+ (1,0) [0|0] "" Vector__XXX
   SG_ ESP_a099_brakeTempModelOverheat m1 : 42|1@1+ (1,0) [0|0] "" Vector__XXX
   SG_ ESP_a100_brakeTempModelDisabled m1 : 43|1@1+ (1,0) [0|0] "" Vector__XXX
   SG_ ESP_a101_ebdFault m1 : 44|1@1+ (1,0) [0|0] "" Vector__XXX
   SG_ ESP_a102_absFault m1 : 45|1@1+ (1,0) [0|0] "" Vector__XXX
   SG_ ESP_a103_stabilityControlFault m1 : 46|1@1+ (1,0) [0|0] "" Vector__XXX
   SG_ ESP_a104_hbcEnabled m1 : 47|1@1+ (1,0) [0|0] "" Vector__XXX
   SG_ ESP_a105_ebrFault m1 : 48|1@1+ (1,0) [0|0] "" Vector__XXX
   SG_ ESP_a106_vdcActuatorFault m1 : 49|1@1+ (1,0) [0|0] "" Vector__XXX
   SG_ ESP_a107_reserved107 m1 : 50|1@1+ (1,0) [0|0] "" Vector__XXX
   SG_ ESP_a108_reserved108 m1 : 51|1@1+ (1,0) [0|0] "" Vector__XXX
   SG_ ESP_a109_reserved109 m1 : 52|1@1+ (1,0) [0|0] "" Vector__XXX
   SG_ ESP_a110_rollerBenchActive m1 : 53|1@1+ (1,0) [0|0] "" Vector__XXX
   SG_ ESP_a111_absActive m1 : 54|1@1+ (1,0) [0|0] "" Vector__XXX
   SG_ ESP_a112_espActive m1 : 55|1@1+ (1,0) [0|0] "" Vector__XXX
   SG_ ESP_a113_btcActive m1 : 56|1@1+ (1,0) [0|0] "" Vector__XXX
   SG_ ESP_a114_tvdcActive m1 : 57|1@1+ (1,0) [0|0] "" Vector__XXX
   SG_ ESP_a115_ebdActive m1 : 58|1@1+ (1,0) [0|0] "" Vector__XXX
   SG_ ESP_a116_tsmActive m1 : 59|1@1+ (1,0) [0|0] "" Vector__XXX
   SG_ ESP_a117_hbaActive m1 : 60|1@1+ (1,0) [0|0] "" Vector__XXX
   SG_ ESP_a118_hfcActive m1 : 61|1@1+ (1,0) [0|0] "" Vector__XXX
   SG_ ESP_a119_hbbActive m1 : 62|1@1+ (1,0) [0|0] "" Vector__XXX
   SG_ ESP_a120_rmiActive m1 : 63|1@1+ (1,0) [0|0] "" Vector__XXX
   SG_ ESP_a121_regenTcActive m2 : 4|1@1+ (1,0) [0|0] "" Vector__XXX
   SG_ ESP_a122_bdwActive m2 : 5|1@1+ (1,0) [0|0] "" Vector__XXX
   SG_ ESP_a123_ebrActive m2 : 6|1@1+ (1,0) [0|0] "" Vector__XXX
   SG_ ESP_a124_ebrSkidActive m2 : 7|1@1+ (1,0) [0|0] "" Vector__XXX
   SG_ ESP_a125_reserved125 m2 : 8|1@1+ (1,0) [0|0] "" Vector__XXX
   SG_ ESP_a126_reserved126 m2 : 9|1@1+ (1,0) [0|0] "" Vector__XXX
   SG_ ESP_a127_reserved127 m2 : 10|1@1+ (1,0) [0|0] "" Vector__XXX
   SG_ ESP_a128_reserved128 m2 : 11|1@1+ (1,0) [0|0] "" Vector__XXX
   SG_ ESP_a129_reserved129 m2 : 12|1@1+ (1,0) [0|0] "" Vector__XXX
   SG_ ESP_a130_EPAS3PsysStatusTimeout m2 : 13|1@1+ (1,0) [0|0] "" Vector__XXX
   SG_ ESP_a131_EPAS3PsysStatusDLC m2 : 14|1@1+ (1,0) [0|0] "" Vector__XXX
   SG_ ESP_a132_EPAS3PsysStatusChecksum m2 : 15|1@1+ (1,0) [0|0] "" Vector__XXX
   SG_ ESP_a133_EPAS3PsysStatusCounter m2 : 16|1@1+ (1,0) [0|0] "" Vector__XXX
   SG_ ESP_a134_steeringAngleInvalid m2 : 17|1@1+ (1,0) [0|0] "" Vector__XXX
   SG_ ESP_a135_steeringAngleNoCenter m2 : 18|1@1+ (1,0) [0|0] "" Vector__XXX
   SG_ ESP_a136_steeringAngleFrozen m2 : 19|1@1+ (1,0) [0|0] "" Vector__XXX
   SG_ ESP_a137_steeringOffsetTooLarge m2 : 20|1@1+ (1,0) [0|0] "" Vector__XXX
   SG_ ESP_a138_steeringAngleImplaus m2 : 21|1@1+ (1,0) [0|0] "" Vector__XXX
   SG_ ESP_a139_steeringAngleWrongSign m2 : 22|1@1+ (1,0) [0|0] "" Vector__XXX
   SG_ ESP_a140_RCMInertial1Timeout m2 : 23|1@1+ (1,0) [0|0] "" Vector__XXX
   SG_ ESP_a141_RCMInertial1DLC m2 : 24|1@1+ (1,0) [0|0] "" Vector__XXX
   SG_ ESP_a142_RCMInertial1Checksum m2 : 25|1@1+ (1,0) [0|0] "" Vector__XXX
   SG_ ESP_a143_RCMInertial1Counter m2 : 26|1@1+ (1,0) [0|0] "" Vector__XXX
   SG_ ESP_a144_yawMaxLatency m2 : 27|1@1+ (1,0) [0|0] "" Vector__XXX
   SG_ ESP_a145_yawInitFault m2 : 28|1@1+ (1,0) [0|0] "" Vector__XXX
   SG_ ESP_a146_yawInvalidValue m2 : 29|1@1+ (1,0) [0|0] "" Vector__XXX
   SG_ ESP_a147_yawSensorNotAvailable m2 : 30|1@1+ (1,0) [0|0] "" Vector__XXX
   SG_ ESP_a148_yawSignalFault m2 : 31|1@1+ (1,0) [0|0] "" Vector__XXX
   SG_ ESP_a149_yawInvalidSign m2 : 32|1@1+ (1,0) [0|0] "" Vector__XXX
   SG_ ESP_a150_yawImplausible m2 : 33|1@1+ (1,0) [0|0] "" Vector__XXX
   SG_ ESP_a151_RCMInertial2Timeout m2 : 34|1@1+ (1,0) [0|0] "" Vector__XXX
   SG_ ESP_a152_RCMInertial2DLC m2 : 35|1@1+ (1,0) [0|0] "" Vector__XXX
   SG_ ESP_a153_RCMInertial2Checksum m2 : 36|1@1+ (1,0) [0|0] "" Vector__XXX
   SG_ ESP_a154_RCMInertial2Counter m2 : 37|1@1+ (1,0) [0|0] "" Vector__XXX
   SG_ ESP_a155_ayMaxLatency m2 : 38|1@1+ (1,0) [0|0] "" Vector__XXX
   SG_ ESP_a156_ayInitFault m2 : 39|1@1+ (1,0) [0|0] "" Vector__XXX
   SG_ ESP_a157_ayInvalidValue m2 : 40|1@1+ (1,0) [0|0] "" Vector__XXX
   SG_ ESP_a158_aySensorNotAvailable m2 : 41|1@1+ (1,0) [0|0] "" Vector__XXX
   SG_ ESP_a159_aySignalFault m2 : 42|1@1+ (1,0) [0|0] "" Vector__XXX
   SG_ ESP_a160_ayRangeExceeded m2 : 43|1@1+ (1,0) [0|0] "" Vector__XXX
   SG_ ESP_a161_ayOffsetExceeded m2 : 44|1@1+ (1,0) [0|0] "" Vector__XXX
   SG_ ESP_a162_ayImplausible m2 : 45|1@1+ (1,0) [0|0] "" Vector__XXX
   SG_ ESP_a163_axMaxLatency m2 : 46|1@1+ (1,0) [0|0] "" Vector__XXX
   SG_ ESP_a164_axInitFault m2 : 47|1@1+ (1,0) [0|0] "" Vector__XXX
   SG_ ESP_a165_axInvalidValue m2 : 48|1@1+ (1,0) [0|0] "" Vector__XXX
   SG_ ESP_a166_axSensorNotAvailable m2 : 49|1@1+ (1,0) [0|0] "" Vector__XXX
   SG_ ESP_a167_axSignalFault m2 : 50|1@1+ (1,0) [0|0] "" Vector__XXX
   SG_ ESP_a168_axRangeExceeded m2 : 51|1@1+ (1,0) [0|0] "" Vector__XXX
   SG_ ESP_a169_axOffsetExceeded m2 : 52|1@1+ (1,0) [0|0] "" Vector__XXX
   SG_ ESP_a170_axSignalFrozen m2 : 53|1@1+ (1,0) [0|0] "" Vector__XXX
   SG_ ESP_a171_axImplausible m2 : 54|1@1+ (1,0) [0|0] "" Vector__XXX
   SG_ ESP_a172_IBSTparty1Timeout m2 : 55|1@1+ (1,0) [0|0] "" Vector__XXX
   SG_ ESP_a173_IBSTparty1DLC m2 : 56|1@1+ (1,0) [0|0] "" Vector__XXX
   SG_ ESP_a174_IBSTparty1Checksum m2 : 57|1@1+ (1,0) [0|0] "" Vector__XXX
   SG_ ESP_a175_IBSTparty1Counter m2 : 58|1@1+ (1,0) [0|0] "" Vector__XXX
   SG_ ESP_a176_IBSTEBRNotAvailable m2 : 59|1@1+ (1,0) [0|0] "" Vector__XXX
   SG_ ESP_a177_IBSTOutputRodDrvInvalid m2 : 60|1@1+ (1,0) [0|0] "" Vector__XXX
   SG_ ESP_a178_IBSTOutputRodActInvalid m2 : 61|1@1+ (1,0) [0|0] "" Vector__XXX
   SG_ ESP_a179_IBSTparty2Timeout m2 : 62|1@1+ (1,0) [0|0] "" Vector__XXX
   SG_ ESP_a180_IBSTparty2Checksum m2 : 63|1@1+ (1,0) [0|0] "" Vector__XXX
   SG_ ESP_a181_IBSTparty2DLC m3 : 4|1@1+ (1,0) [0|0] "" Vector__XXX
   SG_ ESP_a182_IBSTparty2Counter m3 : 5|1@1+ (1,0) [0|0] "" Vector__XXX
   SG_ ESP_a183_IBSTStatusOff m3 : 6|1@1+ (1,0) [0|0] "" Vector__XXX
   SG_ ESP_a184_IBSTpRunoutInvalid m3 : 7|1@1+ (1,0) [0|0] "" Vector__XXX
   SG_ ESP_a185_IBSTFeedforwardBackup m3 : 8|1@1+ (1,0) [0|0] "" Vector__XXX
   SG_ ESP_a186_IBSTBrakeAppliedInvalid m3 : 9|1@1+ (1,0) [0|0] "" Vector__XXX
   SG_ ESP_a187_DIbtcRequestTimeout m3 : 10|1@1+ (1,0) [0|0] "" Vector__XXX
   SG_ ESP_a188_DIbtcRequestDLC m3 : 11|1@1+ (1,0) [0|0] "" Vector__XXX
   SG_ ESP_a189_DIbtcRequestChecksum m3 : 12|1@1+ (1,0) [0|0] "" Vector__XXX
   SG_ ESP_a190_DIbtcRequestCounter m3 : 13|1@1+ (1,0) [0|0] "" Vector__XXX
   SG_ ESP_a191_DIchassiControlTimeout m3 : 14|1@1+ (1,0) [0|0] "" Vector__XXX
   SG_ ESP_a192_DIchassiControlDLC m3 : 15|1@1+ (1,0) [0|0] "" Vector__XXX
   SG_ ESP_a193_DIchassiControlChecksum m3 : 16|1@1+ (1,0) [0|0] "" Vector__XXX
   SG_ ESP_a194_DIchassiControlCounter m3 : 17|1@1+ (1,0) [0|0] "" Vector__XXX
   SG_ ESP_a195_ptcStateInvalid m3 : 18|1@1+ (1,0) [0|0] "" Vector__XXX
   SG_ ESP_a196_DIsystemStatusTimeout m3 : 19|1@1+ (1,0) [0|0] "" Vector__XXX
   SG_ ESP_a197_DIsystemStatusDLC m3 : 20|1@1+ (1,0) [0|0] "" Vector__XXX
   SG_ ESP_a198_DIsystemStatusChecksum m3 : 21|1@1+ (1,0) [0|0] "" Vector__XXX
   SG_ ESP_a199_DIsystemStatusCounter m3 : 22|1@1+ (1,0) [0|0] "" Vector__XXX
   SG_ ESP_a200_reverseGearStuckHigh m3 : 23|1@1+ (1,0) [0|0] "" Vector__XXX
   SG_ ESP_a201_reverseGearStuckLow m3 : 24|1@1+ (1,0) [0|0] "" Vector__XXX
   SG_ ESP_a202_accelPedalInvalid m3 : 25|1@1+ (1,0) [0|0] "" Vector__XXX
   SG_ ESP_a203_DItorqueTimeout m3 : 26|1@1+ (1,0) [0|0] "" Vector__XXX
   SG_ ESP_a204_DItorqueDLC m3 : 27|1@1+ (1,0) [0|0] "" Vector__XXX
   SG_ ESP_a205_DItorqueChecksum m3 : 28|1@1+ (1,0) [0|0] "" Vector__XXX
   SG_ ESP_a206_DItorqueCounter m3 : 29|1@1+ (1,0) [0|0] "" Vector__XXX
   SG_ ESP_a207_DITorqueCommandInvalid m3 : 30|1@1+ (1,0) [0|0] "" Vector__XXX
   SG_ ESP_a208_DIRPMInvalid m3 : 31|1@1+ (1,0) [0|0] "" Vector__XXX
   SG_ ESP_a209_DITorqueActualInvalid m3 : 32|1@1+ (1,0) [0|0] "" Vector__XXX
   SG_ ESP_a210_DIStorqueTimeout m3 : 33|1@1+ (1,0) [0|0] "" Vector__XXX
   SG_ ESP_a211_DIStorqueDLC m3 : 34|1@1+ (1,0) [0|0] "" Vector__XXX
   SG_ ESP_a212_DIStorqueChecksum m3 : 35|1@1+ (1,0) [0|0] "" Vector__XXX
   SG_ ESP_a213_DIStorqueCounter m3 : 36|1@1+ (1,0) [0|0] "" Vector__XXX
   SG_ ESP_a214_DISTorqueCommandInvalid m3 : 37|1@1+ (1,0) [0|0] "" Vector__XXX
   SG_ ESP_a215_DISRPMInvalid m3 : 38|1@1+ (1,0) [0|0] "" Vector__XXX
   SG_ ESP_a216_DISTorqueActualInvalid m3 : 39|1@1+ (1,0) [0|0] "" Vector__XXX
   SG_ ESP_a217_DIvdcLeftTimeout m3 : 40|1@1+ (1,0) [0|0] "" Vector__XXX
   SG_ ESP_a218_DIvdcLeftDLC m3 : 41|1@1+ (1,0) [0|0] "" Vector__XXX
   SG_ ESP_a219_DIvdcLeftChecksum m3 : 42|1@1+ (1,0) [0|0] "" Vector__XXX
   SG_ ESP_a220_DIvdcLeftCounter m3 : 43|1@1+ (1,0) [0|0] "" Vector__XXX
   SG_ ESP_a221_DIvdcRightTimeout m3 : 44|1@1+ (1,0) [0|0] "" Vector__XXX
   SG_ ESP_a222_DIvdcRightDLC m3 : 45|1@1+ (1,0) [0|0] "" Vector__XXX
   SG_ ESP_a223_DIvdcRightChecksum m3 : 46|1@1+ (1,0) [0|0] "" Vector__XXX
   SG_ ESP_a224_DIvdcRightCounter m3 : 47|1@1+ (1,0) [0|0] "" Vector__XXX
   SG_ ESP_a225_configMismatch m3 : 48|1@1+ (1,0) [0|0] "" Vector__XXX
   SG_ ESP_a226_bdwRequestInvalid m3 : 49|1@1+ (1,0) [0|0] "" Vector__XXX
   SG_ ESP_a227_bdwRequestActiveInvalid m3 : 50|1@1+ (1,0) [0|0] "" Vector__XXX
   SG_ ESP_a228_GTWvinTimeout m3 : 51|1@1+ (1,0) [0|0] "" Vector__XXX
   SG_ ESP_a229_GTWvinDLC m3 : 52|1@1+ (1,0) [0|0] "" Vector__XXX
   SG_ ESP_a230_vinNotLearned m3 : 53|1@1+ (1,0) [0|0] "" Vector__XXX
   SG_ ESP_a231_storedVINMismatch m3 : 54|1@1+ (1,0) [0|0] "" Vector__XXX
   SG_ ESP_a232_PMstate2Timeout m3 : 55|1@1+ (1,0) [0|0] "" Vector__XXX
   SG_ ESP_a233_PMstate2Checksum m3 : 56|1@1+ (1,0) [0|0] "" Vector__XXX
   SG_ ESP_a234_PMstate2DLC m3 : 57|1@1+ (1,0) [0|0] "" Vector__XXX
   SG_ ESP_a235_PMstate2Counter m3 : 58|1@1+ (1,0) [0|0] "" Vector__XXX
   SG_ ESP_a236_ebrCommandStateInvalid m3 : 59|1@1+ (1,0) [0|0] "" Vector__XXX
   SG_ ESP_a237_vdcCommandStateInvalid m3 : 60|1@1+ (1,0) [0|0] "" Vector__XXX
   SG_ ESP_a238_UIodoTimeout m3 : 61|1@1+ (1,0) [0|0] "" Vector__XXX
   SG_ ESP_a239_UIodoDLC m3 : 62|1@1+ (1,0) [0|0] "" Vector__XXX
   SG_ ESP_a240_LVPowerStateTimeout m3 : 63|1@1+ (1,0) [0|0] "" Vector__XXX
   SG_ ESP_a241_LVPowerStateChecksum m4 : 4|1@1+ (1,0) [0|0] "" Vector__XXX
   SG_ ESP_a242_LVPowerStateDLC m4 : 5|1@1+ (1,0) [0|0] "" Vector__XXX
   SG_ ESP_a243_LVPowerStateCounter m4 : 6|1@1+ (1,0) [0|0] "" Vector__XXX
   SG_ ESP_a244_LVOffStateInvalid m4 : 7|1@1+ (1,0) [0|0] "" Vector__XXX
   SG_ ESP_a245_LVGoingDownStateInvalid m4 : 8|1@1+ (1,0) [0|0] "" Vector__XXX
   SG_ ESP_a246_VCFRONTsensorTimeout m4 : 9|1@1+ (1,0) [0|0] "" Vector__XXX
   SG_ ESP_a247_VCFRONTsensorDLC m4 : 10|1@1+ (1,0) [0|0] "" Vector__XXX
   SG_ ESP_a248_vdcBrkeTrqTarFrLInvalid m4 : 11|1@1+ (1,0) [0|0] "" Vector__XXX
   SG_ ESP_a249_vdcBrkeTrqTarFrRInvalid m4 : 12|1@1+ (1,0) [0|0] "" Vector__XXX
   SG_ ESP_a250_vdcBrkeTrqTarReLInvalid m4 : 13|1@1+ (1,0) [0|0] "" Vector__XXX
   SG_ ESP_a251_vdcBrkeTrqTarReRInvalid m4 : 14|1@1+ (1,0) [0|0] "" Vector__XXX
   SG_ ESP_a252_vdcWhlSlipLimFrLInvalid m4 : 15|1@1+ (1,0) [0|0] "" Vector__XXX
   SG_ ESP_a253_vdcWhlSlipLimFrRInvalid m4 : 16|1@1+ (1,0) [0|0] "" Vector__XXX
   SG_ ESP_a254_vdcWhlSlipLimReLInvalid m4 : 17|1@1+ (1,0) [0|0] "" Vector__XXX
   SG_ ESP_a255_vdcWhlSlipLimReRInvalid m4 : 18|1@1+ (1,0) [0|0] "" Vector__XXX
   SG_ ESP_a256_epbmStatusTimeout m4 : 19|1@1+ (1,0) [0|0] "" Vector__XXX
   SG_ ESP_a257_epbmStatusChecksum m4 : 20|1@1+ (1,0) [0|0] "" Vector__XXX
   SG_ ESP_a258_epbmStatusDLC m4 : 21|1@1+ (1,0) [0|0] "" Vector__XXX
   SG_ ESP_a259_epbmStatusCounter m4 : 22|1@1+ (1,0) [0|0] "" Vector__XXX
   SG_ ESP_a260_epblStatusTimeout m4 : 23|1@1+ (1,0) [0|0] "" Vector__XXX
   SG_ ESP_a261_epblStatusChecksum m4 : 24|1@1+ (1,0) [0|0] "" Vector__XXX
   SG_ ESP_a262_epblStatusDLC m4 : 25|1@1+ (1,0) [0|0] "" Vector__XXX
   SG_ ESP_a263_epblStatusCounter m4 : 26|1@1+ (1,0) [0|0] "" Vector__XXX

BO_ 808 ESP_info: 8 Vector__XXX
   SG_ ESP_infoIndex M : 0|8@1+ (1,0) [0|0] "" Vector__XXX
   SG_ ESP_infoBuildType m10 : 8|8@1+ (1,0) [0|0] "" Vector__XXX
   SG_ ESP_infoComponentID m10 : 48|16@1+ (1,0) [0|0] "" Vector__XXX
   SG_ ESP_infoPcbaID m11 : 16|8@1+ (1,0) [0|0] "" Vector__XXX
   SG_ ESP_infoAssemblyID m11 : 24|8@1+ (1,0) [0|0] "" Vector__XXX
   SG_ ESP_infoUsageID m11 : 32|16@1+ (1,0) [0|0] "" Vector__XXX
   SG_ ESP_infoApplicationCRC m13 : 32|32@0+ (1,0) [0|0] "" Vector__XXX
   SG_ ESP_infoVehicleVariant m16 : 16|8@1+ (1,0) [0|0] "" Vector__XXX
   SG_ ESP_infoBootUdsProtoVersion m20 : 8|8@1+ (1,0) [0|0] "" Vector__XXX
   SG_ ESP_infoBootloaderCRC m20 : 32|32@1+ (1,0) [0|0] "" Vector__XXX
   SG_ ESP_infoVariantCRC m22 : 32|32@0+ (1,0) [0|0] "" Vector__XXX

BO_ 325 ESP_status: 8 Vector__XXX
   SG_ ESP_absBrakeEvent2 : 22|2@1+ (1,0) [0|0] "" Vector__XXX
   SG_ ESP_absFaultLamp : 17|1@1+ (1,0) [0|0] "" Vector__XXX
   SG_ ESP_brakeApply : 31|1@1+ (1,0) [0|0] "" Vector__XXX
   SG_ ESP_brakeDiscWipingActive : 28|1@1+ (1,0) [0|0] "" Vector__XXX
   SG_ ESP_brakeLamp : 21|1@1+ (1,0) [0|0] "" Vector__XXX
   SG_ ESP_brakeTorqueTarget : 51|13@1+ (2,0) [0|0] "Nm" Vector__XXX
   SG_ ESP_btcTargetState : 38|2@1+ (1,0) [0|0] "" Vector__XXX
   SG_ ESP_cdpStatus : 34|2@1+ (1,0) [0|0] "" Vector__XXX
   SG_ ESP_driverBrakeApply : 29|2@1+ (1,0) [0|0] "" Vector__XXX
   SG_ ESP_ebdFaultLamp : 16|1@1+ (1,0) [0|0] "" Vector__XXX
   SG_ ESP_ebrStandstillSkid : 48|1@1+ (1,0) [0|0] "" Vector__XXX
   SG_ ESP_ebrStatus : 49|2@1+ (1,0) [0|0] "" Vector__XXX
   SG_ ESP_espFaultLamp : 18|1@1+ (1,0) [0|0] "" Vector__XXX
   SG_ ESP_espLampFlash : 20|1@1+ (1,0) [0|0] "" Vector__XXX
   SG_ ESP_espModeActive : 12|2@1+ (1,0) [0|0] "" Vector__XXX
   SG_ ESP_hydraulicBoostEnabled : 19|1@1+ (1,0) [0|0] "" Vector__XXX
   SG_ ESP_lateralAccelQF : 25|1@1+ (1,0) [0|0] "" Vector__XXX
   SG_ ESP_longitudinalAccelQF : 24|1@1+ (1,0) [0|0] "" Vector__XXX
   SG_ ESP_ptcTargetState : 36|2@1+ (1,0) [0|0] "" Vector__XXX
   SG_ ESP_stabilityControlSts2 : 14|2@1+ (1,0) [0|0] "" Vector__XXX
   SG_ ESP_statusChecksum : 0|8@1+ (1,0) [0|0] "" Vector__XXX
   SG_ ESP_statusCounter : 8|4@1+ (1,0) [0|0] "" Vector__XXX
   SG_ ESP_steeringAngleQF : 27|1@1+ (1,0) [0|0] "" Vector__XXX
   SG_ ESP_yawRateQF : 26|1@1+ (1,0) [0|0] "" Vector__XXX

BO_ 1621 ESP_udsResponse: 8 Vector__XXX
   SG_ ESP_udsResponseData : 0|54@0+ (1024,0) [0|0] "" Vector__XXX

BO_ 805 FC_alertMatrix1: 8 Vector__XXX
   SG_ FC_a001_scPostOutOfService : 0|1@1+ (1,0) [0|0] "" Vector__XXX
   SG_ FC_a002_scPowerShared : 1|1@1+ (1,0) [0|0] "" Vector__XXX

BO_ 831 FC_alertMatrix2: 8 Vector__XXX
   SG_ FC_a065_userData : 0|1@1+ (1,0) [0|0] "" Vector__XXX

BO_ 895 FC_alertMatrix3: 8 Vector__XXX
   SG_ FC_a129_CA_flyback_HW_OC : 0|1@1+ (1,0) [0|0] "" Vector__XXX
   SG_ FC_a130_CA_flyback_SW_OV : 1|1@1+ (1,0) [0|0] "" Vector__XXX
   SG_ FC_a131_CA_flyback_HW_OV : 2|1@1+ (1,0) [0|0] "" Vector__XXX
   SG_ FC_a132_CA_bmsMia : 3|1@1+ (1,0) [0|0] "" Vector__XXX
   SG_ FC_a133_CA_evseMia : 4|1@1+ (1,0) [0|0] "" Vector__XXX
   SG_ FC_a134_CA_vehTxBufOvf : 5|1@1+ (1,0) [0|0] "" Vector__XXX
   SG_ FC_a135_CA_vehRxBufOvf : 6|1@1+ (1,0) [0|0] "" Vector__XXX
   SG_ FC_a136_CA_evseTxBufOvf : 7|1@1+ (1,0) [0|0] "" Vector__XXX
   SG_ FC_a137_CA_evseRxBufOvf : 8|1@1+ (1,0) [0|0] "" Vector__XXX
   SG_ FC_a138_CA_hwProxTrip : 9|1@1+ (1,0) [0|0] "" Vector__XXX
   SG_ FC_a139_CA_ss2NotLow : 10|1@1+ (1,0) [0|0] "" Vector__XXX
   SG_ FC_a140_CA_bmsIncompatible : 11|1@1+ (1,0) [0|0] "" Vector__XXX
   SG_ FC_a141_CA_vehConn_OT : 12|1@1+ (1,0) [0|0] "" Vector__XXX
   SG_ FC_a142_CA_evseConn_OT : 13|1@1+ (1,0) [0|0] "" Vector__XXX
   SG_ FC_a143_CA_pcb_OT : 14|1@1+ (1,0) [0|0] "" Vector__XXX
   SG_ FC_a144_CA_flybackUnstable : 15|1@1+ (1,0) [0|0] "" Vector__XXX
   SG_ FC_a145_CA_flybackDataStale : 16|1@1+ (1,0) [0|0] "" Vector__XXX
   SG_ FC_a146_CA_flybackBusLoadHi : 17|1@1+ (1,0) [0|0] "" Vector__XXX
   SG_ FC_a147_CA_vehConn_UT : 18|1@1+ (1,0) [0|0] "" Vector__XXX
   SG_ FC_a148_CA_evseConn_UT : 19|1@1+ (1,0) [0|0] "" Vector__XXX
   SG_ FC_a149_CA_pcb_UT : 20|1@1+ (1,0) [0|0] "" Vector__XXX
   SG_ FC_a150_CA_vehToEvseDeltaHi : 21|1@1+ (1,0) [0|0] "" Vector__XXX
   SG_ FC_a151_CA_vehToEvseDeltaLo : 22|1@1+ (1,0) [0|0] "" Vector__XXX
   SG_ FC_a152_CA_vehToPcbDeltaHi : 23|1@1+ (1,0) [0|0] "" Vector__XXX
   SG_ FC_a153_CA_evseToPcbDeltaHi : 24|1@1+ (1,0) [0|0] "" Vector__XXX
   SG_ FC_a154_CA_vehToPcbDeltaLo : 25|1@1+ (1,0) [0|0] "" Vector__XXX
   SG_ FC_a155_CA_evseToPcbDeltaLo : 26|1@1+ (1,0) [0|0] "" Vector__XXX
   SG_ FC_a156_CA_flybackRunTimeout : 27|1@1+ (1,0) [0|0] "" Vector__XXX
   SG_ FC_a157_CA_unused : 28|1@1+ (1,0) [0|0] "" Vector__XXX
   SG_ FC_a158_CA_evseOverCurrent : 29|1@1+ (1,0) [0|0] "" Vector__XXX
   SG_ FC_a159_CA_wdtExpired : 30|1@1+ (1,0) [0|0] "" Vector__XXX
   SG_ FC_a160_CA_ss2Deasserted : 31|1@1+ (1,0) [0|0] "" Vector__XXX
   SG_ FC_a161_CA_vehTempHiFoldBk : 32|1@1+ (1,0) [0|0] "" Vector__XXX
   SG_ FC_a162_CA_evseTempHiFoldBk : 33|1@1+ (1,0) [0|0] "" Vector__XXX
   SG_ FC_a163_CA_pcbTempHiFoldBk : 34|1@1+ (1,0) [0|0] "" Vector__XXX
   SG_ FC_a164_CA_proxDisconnected : 35|1@1+ (1,0) [0|0] "" Vector__XXX
   SG_ FC_a165_CA_evseConnUnlocked : 36|1@1+ (1,0) [0|0] "" Vector__XXX
   SG_ FC_a166_CA_vehConnUnlocked : 37|1@1+ (1,0) [0|0] "" Vector__XXX
   SG_ FC_a167_CA_isoVoltageLow : 38|1@1+ (1,0) [0|0] "" Vector__XXX
   SG_ FC_a168_CA_proxTimeout : 39|1@1+ (1,0) [0|0] "" Vector__XXX
   SG_ FC_a169_CA_pilotAcceptTimeout : 40|1@1+ (1,0) [0|0] "" Vector__XXX
   SG_ FC_a170_CA_vehDataTimeout : 41|1@1+ (1,0) [0|0] "" Vector__XXX
   SG_ FC_a171_CA_vehConLockTimeout : 42|1@1+ (1,0) [0|0] "" Vector__XXX
   SG_ FC_a172_CA_ss2LowTimeout : 43|1@1+ (1,0) [0|0] "" Vector__XXX
   SG_ FC_a173_CA_evseDataTimeout : 44|1@1+ (1,0) [0|0] "" Vector__XXX
   SG_ FC_a174_CA_vehReadyTimeout : 45|1@1+ (1,0) [0|0] "" Vector__XXX
   SG_ FC_a175_CA_evseIsoTestTimeout : 46|1@1+ (1,0) [0|0] "" Vector__XXX
   SG_ FC_a176_CA_chargingBusTimeout : 47|1@1+ (1,0) [0|0] "" Vector__XXX
   SG_ FC_a177_CA_bmsCtrCloseTimeout : 48|1@1+ (1,0) [0|0] "" Vector__XXX
   SG_ FC_a178_CA_evseStartTimeout : 49|1@1+ (1,0) [0|0] "" Vector__XXX
   SG_ FC_a179_CA_startupProblem : 50|1@1+ (1,0) [0|0] "" Vector__XXX
   SG_ FC_a180_CA_chargingProblem : 51|1@1+ (1,0) [0|0] "" Vector__XXX
   SG_ FC_a181_CA_vRegBrownout : 52|1@1+ (1,0) [0|0] "" Vector__XXX
   SG_ FC_a182_CA_evseChrMalfunc : 53|1@1+ (1,0) [0|0] "" Vector__XXX
   SG_ FC_a183_CA_evseBatIncompat : 54|1@1+ (1,0) [0|0] "" Vector__XXX
   SG_ FC_a184_CA_evseBatMalfunc : 55|1@1+ (1,0) [0|0] "" Vector__XXX
   SG_ FC_a185_CA_vehReadyDeasserted : 56|1@1+ (1,0) [0|0] "" Vector__XXX
   SG_ FC_a186_CA_fcContOpenTimeout : 57|1@1+ (1,0) [0|0] "" Vector__XXX
   SG_ FC_a187_CA_evseConLockTimeout : 58|1@1+ (1,0) [0|0] "" Vector__XXX

BO_ 927 FC_alertMatrix4: 8 Vector__XXX
   SG_ FC_a193_FCAlertPlaceholder : 0|1@1+ (1,0) [0|0] "" Vector__XXX

BO_ 958 FC_alertMatrix5: 8 Vector__XXX
   SG_ FC_a257_GB_bmsMia : 0|1@1+ (1,0) [0|0] "" Vector__XXX
   SG_ FC_a258_GB_evseMia : 1|1@1+ (1,0) [0|0] "" Vector__XXX
   SG_ FC_a259_GB_vehTxBufOvf : 2|1@1+ (1,0) [0|0] "" Vector__XXX
   SG_ FC_a260_GB_vehRxBufOvf : 3|1@1+ (1,0) [0|0] "" Vector__XXX
   SG_ FC_a261_GB_evseTxBufOvf : 4|1@1+ (1,0) [0|0] "" Vector__XXX
   SG_ FC_a262_GB_evseRxBufOvf : 5|1@1+ (1,0) [0|0] "" Vector__XXX
   SG_ FC_a263_GB_hwProxTrip : 6|1@1+ (1,0) [0|0] "" Vector__XXX
   SG_ FC_a264_GB_ss2NotLow : 7|1@1+ (1,0) [0|0] "" Vector__XXX
   SG_ FC_a265_GB_bmsIncompatible : 8|1@1+ (1,0) [0|0] "" Vector__XXX
   SG_ FC_a266_GB_negPin_OT : 9|1@1+ (1,0) [0|0] "" Vector__XXX
   SG_ FC_a267_GB_posPin_OT : 10|1@1+ (1,0) [0|0] "" Vector__XXX
   SG_ FC_a268_GB_pcb_OT : 11|1@1+ (1,0) [0|0] "" Vector__XXX
   SG_ FC_a269_GB_unused : 12|1@1+ (1,0) [0|0] "" Vector__XXX
   SG_ FC_a270_GB_unused : 13|1@1+ (1,0) [0|0] "" Vector__XXX
   SG_ FC_a271_GB_unused : 14|1@1+ (1,0) [0|0] "" Vector__XXX
   SG_ FC_a272_GB_negToPosDeltaHi : 15|1@1+ (1,0) [0|0] "" Vector__XXX
   SG_ FC_a273_GB_negToPosDeltaLo : 16|1@1+ (1,0) [0|0] "" Vector__XXX
   SG_ FC_a274_GB_negToPcbDeltaHi : 17|1@1+ (1,0) [0|0] "" Vector__XXX
   SG_ FC_a275_GB_posToPcbDeltaHi : 18|1@1+ (1,0) [0|0] "" Vector__XXX
   SG_ FC_a276_GB_negToPcbDeltaLo : 19|1@1+ (1,0) [0|0] "" Vector__XXX
   SG_ FC_a277_GB_posToPcbDeltaLo : 20|1@1+ (1,0) [0|0] "" Vector__XXX
   SG_ FC_a278_GB_unused : 21|1@1+ (1,0) [0|0] "" Vector__XXX
   SG_ FC_a279_GB_evseOverCurrent : 22|1@1+ (1,0) [0|0] "" Vector__XXX
   SG_ FC_a280_GB_unused : 23|1@1+ (1,0) [0|0] "" Vector__XXX
   SG_ FC_a281_GB_ss2Deasserted : 24|1@1+ (1,0) [0|0] "" Vector__XXX
   SG_ FC_a282_GB_negTempHiFoldBk : 25|1@1+ (1,0) [0|0] "" Vector__XXX
   SG_ FC_a283_GB_posTempHiFoldBk : 26|1@1+ (1,0) [0|0] "" Vector__XXX
   SG_ FC_a284_GB_pcbTempHiFoldBk : 27|1@1+ (1,0) [0|0] "" Vector__XXX
   SG_ FC_a285_GB_proxDisconnected : 28|1@1+ (1,0) [0|0] "" Vector__XXX
   SG_ FC_a286_GB_evseConnUnlocked : 29|1@1+ (1,0) [0|0] "" Vector__XXX
   SG_ FC_a287_GB_vehConnUnlocked : 30|1@1+ (1,0) [0|0] "" Vector__XXX
   SG_ FC_a288_GB_isoVoltageLow : 31|1@1+ (1,0) [0|0] "" Vector__XXX
   SG_ FC_a289_GB_proxTimeout : 32|1@1+ (1,0) [0|0] "" Vector__XXX
   SG_ FC_a290_GB_pilotAcceptTimeout : 33|1@1+ (1,0) [0|0] "" Vector__XXX
   SG_ FC_a291_GB_vehDataTimeout : 34|1@1+ (1,0) [0|0] "" Vector__XXX
   SG_ FC_a292_GB_vehConLockTimeout : 35|1@1+ (1,0) [0|0] "" Vector__XXX
   SG_ FC_a293_GB_ss2LowTimeout : 36|1@1+ (1,0) [0|0] "" Vector__XXX
   SG_ FC_a294_GB_evseDataTimeout : 37|1@1+ (1,0) [0|0] "" Vector__XXX
   SG_ FC_a295_GB_vehReadyTimeout : 38|1@1+ (1,0) [0|0] "" Vector__XXX
   SG_ FC_a296_GB_evseIsoTestTimeout : 39|1@1+ (1,0) [0|0] "" Vector__XXX
   SG_ FC_a297_GB_chargingBusTimeout : 40|1@1+ (1,0) [0|0] "" Vector__XXX
   SG_ FC_a298_GB_bmsCtrCloseTimeout : 41|1@1+ (1,0) [0|0] "" Vector__XXX
   SG_ FC_a299_GB_evseReadyTimeout : 42|1@1+ (1,0) [0|0] "" Vector__XXX
   SG_ FC_a300_GB_startupProblem : 43|1@1+ (1,0) [0|0] "" Vector__XXX
   SG_ FC_a301_GB_chargingProblem : 44|1@1+ (1,0) [0|0] "" Vector__XXX
   SG_ FC_a302_GB_vRegBrownout : 45|1@1+ (1,0) [0|0] "" Vector__XXX
   SG_ FC_a303_GB_negRecogTimeout : 46|1@1+ (1,0) [0|0] "" Vector__XXX
   SG_ FC_a304_GB_evseIncompatible : 47|1@1+ (1,0) [0|0] "" Vector__XXX
   SG_ FC_a305_GB_posRecogTimeout : 48|1@1+ (1,0) [0|0] "" Vector__XXX
   SG_ FC_a306_GB_vehReadyDeasserted : 49|1@1+ (1,0) [0|0] "" Vector__XXX
   SG_ FC_a307_GB_fcContOpenTimeout : 50|1@1+ (1,0) [0|0] "" Vector__XXX
   SG_ FC_a308_GB_evseConLockTimeout : 51|1@1+ (1,0) [0|0] "" Vector__XXX
   SG_ FC_a309_GB_unused : 52|1@1+ (1,0) [0|0] "" Vector__XXX
   SG_ FC_a310_GB_vehicleIdTimeout : 53|1@1+ (1,0) [0|0] "" Vector__XXX
   SG_ FC_a311_GB_battParamsTimeout : 54|1@1+ (1,0) [0|0] "" Vector__XXX
   SG_ FC_a312_GB_evseLimitsTimeout : 55|1@1+ (1,0) [0|0] "" Vector__XXX

BO_ 990 FC_alertMatrix6: 8 Vector__XXX
   SG_ FC_a321_FCAlertPlaceholder : 0|1@1+ (1,0) [0|0] "" Vector__XXX

BO_ 1303 FC_identifier: 8 Vector__XXX
   SG_ FC_id : 0|32@1+ (1,0) [0|0] "" Vector__XXX
   SG_ FC_sessionId : 32|32@1+ (1,0) [0|0] "" Vector__XXX

BO_ 1310 FC_info: 8 Vector__XXX
   SG_ FC_infoIndex M : 0|8@1+ (1,0) [0|0] "" Vector__XXX
   SG_ FC_infoBuildType m10 : 8|3@1+ (1,0) [0|0] "" Vector__XXX
   SG_ FC_infoBuildConfigID m10 : 16|8@1+ (1,0) [0|0] "" Vector__XXX
   SG_ FC_infoHardwareID m10 : 32|16@1+ (1,0) [0|0] "" Vector__XXX
   SG_ FC_infoComponentID m10 : 48|16@1+ (1,0) [0|0] "" Vector__XXX
   SG_ FC_infoPcbaID m11 : 16|8@1+ (1,0) [0|0] "" Vector__XXX
   SG_ FC_infoAssemblyID m11 : 24|8@1+ (1,0) [0|0] "" Vector__XXX
   SG_ FC_infoUsageID m11 : 32|16@1+ (1,0) [0|0] "" Vector__XXX
   SG_ FC_infoSubUsageID m11 : 48|16@1+ (1,0) [0|0] "" Vector__XXX
   SG_ FC_infoApplicationCRC m13 : 32|32@1+ (1,0) [0|0] "" Vector__XXX
   SG_ FC_infoBootSvnRev m14 : 8|24@1+ (1,0) [0|0] "" Vector__XXX
   SG_ FC_infoBootCRC m15 : 32|32@1+ (1,0) [0|0] "" Vector__XXX
   SG_ FC_infoCPLDVersionMajor m16 : 16|8@1+ (1,0) [0|0] "" Vector__XXX
   SG_ FC_infoCPLDVersionMinor m16 : 24|8@1+ (1,0) [0|0] "" Vector__XXX
   SG_ FC_infoAppGitHashBytes m17 : 10|54@1+ (4,0) [0|0] "" Vector__XXX
   SG_ FC_infoBootGitHashBytes m18 : 10|54@1+ (4,0) [0|0] "" Vector__XXX
   SG_ FC_infoPlatformType m19 : 8|8@1+ (1,0) [0|0] "" Vector__XXX
   SG_ FC_infoMajorVersion m19 : 16|8@1+ (1,0) [0|0] "" Vector__XXX
   SG_ FC_infoBranchOrigin m19 : 24|8@1+ (1,0) [0|0] "" Vector__XXX
   SG_ FC_infoMaturity m19 : 32|8@1+ (1,0) [0|0] "" Vector__XXX
   SG_ FC_infoHardwareRevision m19 : 40|8@1+ (1,0) [0|0] "" Vector__XXX
   SG_ FC_infoBootUdsProtoVersion m20 : 8|8@1+ (1,0) [0|0] "" Vector__XXX
   SG_ FC_infoVariantCRC m22 : 32|32@1+ (1,0) [0|0] "" Vector__XXX
   SG_ FC_partNumChar01 m25 : 8|1@1+ (1,0) [0|0] "" Vector__XXX
   SG_ FC_partNumChar02 m25 : 16|1@1+ (1,0) [0|0] "" Vector__XXX
   SG_ FC_partNumChar03 m25 : 24|1@1+ (1,0) [0|0] "" Vector__XXX
   SG_ FC_partNumChar04 m25 : 32|1@1+ (1,0) [0|0] "" Vector__XXX
   SG_ FC_partNumChar05 m25 : 40|1@1+ (1,0) [0|0] "" Vector__XXX
   SG_ FC_partNumChar06 m25 : 48|1@1+ (1,0) [0|0] "" Vector__XXX
   SG_ FC_partNumChar07 m25 : 56|1@1+ (1,0) [0|0] "" Vector__XXX
   SG_ FC_partNumChar08 m26 : 8|1@1+ (1,0) [0|0] "" Vector__XXX
   SG_ FC_partNumChar09 m26 : 16|1@1+ (1,0) [0|0] "" Vector__XXX
   SG_ FC_partNumChar10 m26 : 24|1@1+ (1,0) [0|0] "" Vector__XXX
   SG_ FC_partNumChar11 m26 : 32|1@1+ (1,0) [0|0] "" Vector__XXX
   SG_ FC_partNumChar12 m26 : 40|1@1+ (1,0) [0|0] "" Vector__XXX
   SG_ FC_partNumChar13 m26 : 48|1@1+ (1,0) [0|0] "" Vector__XXX
   SG_ FC_partNumChar14 m26 : 56|1@1+ (1,0) [0|0] "" Vector__XXX
   SG_ FC_partNumChar15 m27 : 8|1@1+ (1,0) [0|0] "" Vector__XXX
   SG_ FC_partNumChar16 m27 : 16|1@1+ (1,0) [0|0] "" Vector__XXX
   SG_ FC_partNumChar17 m27 : 24|1@1+ (1,0) [0|0] "" Vector__XXX
   SG_ FC_partNumChar18 m27 : 32|1@1+ (1,0) [0|0] "" Vector__XXX
   SG_ FC_partNumChar19 m27 : 40|1@1+ (1,0) [0|0] "" Vector__XXX
   SG_ FC_partNumChar20 m27 : 48|1@1+ (1,0) [0|0] "" Vector__XXX

BO_ 580 FC_limits: 8 Vector__XXX
   SG_ FC_currentLimit : 16|13@1+ (0.0732422,0) [0|0] "A" Vector__XXX
   SG_ FC_maxVoltageLimit : 32|13@1+ (0.0732422,0) [0|0] "V" Vector__XXX
   SG_ FC_minVoltageLimit : 48|13@1+ (0.0732422,0) [0|0] "V" Vector__XXX
   SG_ FC_powerLimit : 0|13@1+ (0.0622559,0) [0|0] "kW" Vector__XXX

BO_ 1345 FC_maxLimits: 8 Vector__XXX
   SG_ FC_maxCurrentLimit : 16|13@1+ (0.0732422,0) [0|0] "A" Vector__XXX
   SG_ FC_maxPowerLimit : 0|13@1+ (0.0622559,0) [0|0] "kW" Vector__XXX

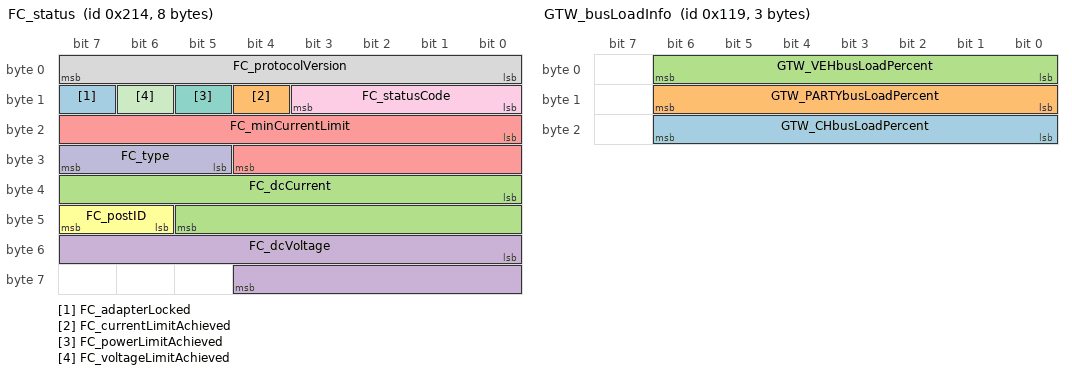
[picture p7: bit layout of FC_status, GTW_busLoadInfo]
BO_ 532 FC_status: 8 Vector__XXX
   SG_ FC_adapterLocked : 15|1@1+ (1,0) [0|0] "" Vector__XXX
   SG_ FC_currentLimitAchieved : 12|1@1+ (1,0) [0|0] "" Vector__XXX
   SG_ FC_dcCurrent : 32|14@1- (0.0732422,0) [0|0] "A" Vector__XXX
   SG_ FC_dcVoltage : 48|13@1+ (0.0732422,0) [0|0] "V" Vector__XXX
   SG_ FC_minCurrentLimit : 16|13@1+ (0.1,0) [0|0] "A" Vector__XXX
   SG_ FC_postID : 46|2@1+ (2,0) [0|0] "" Vector__XXX
   SG_ FC_powerLimitAchieved : 13|1@1+ (1,0) [0|0] "" Vector__XXX
   SG_ FC_protocolVersion : 0|8@1+ (1,0) [0|0] "" Vector__XXX
   SG_ FC_statusCode : 8|4@1+ (1,0) [0|0] "" Vector__XXX
   SG_ FC_type : 29|3@1+ (1,0) [0|0] "" Vector__XXX
   SG_ FC_voltageLimitAchieved : 14|1@1+ (1,0) [0|0] "" Vector__XXX

BO_ 533 FC_status2: 1 Vector__XXX
   SG_ FC_externalIsolationResistance : 0|8@1+ (40,0) [0|0] "kOhm" Vector__XXX

BO_ 535 FC_status3: 8 Vector__XXX
   SG_ FC_status3DataSelect M : 0|7@1+ (1,0) [0|0] "" Vector__XXX
   SG_ FC_status3DummySig : 7|1@1+ (1,0) [0|0] "" Vector__XXX
   SG_ FC_class m0 : 8|8@1+ (1,0) [0|0] "" Vector__XXX
   SG_ FC_brand m0 : 16|4@1+ (1,0) [0|0] "" Vector__XXX
   SG_ FC_coolingType m0 : 20|4@1+ (1,0) [0|0] "" Vector__XXX
   SG_ FC_uiStopType m0 : 24|4@1+ (1,0) [0|0] "" Vector__XXX

BO_ 888 GTW_ECall: 1 Vector__XXX
   SG_ GTW_GSM_ECALL_nLOCK : 0|1@1+ (1,0) [0|0] "" Vector__XXX

BO_ 273 GTW_adc: 7 Vector__XXX
   SG_ GTW_12V0_AUDIO_FILT : 0|14@0+ (11,0) [0|0] "mV" Vector__XXX
   SG_ GTW_12V0_FILT : 16|14@0+ (11,0) [0|0] "mV" Vector__XXX
   SG_ GTW_WLAN_ANT_DET0 : 32|12@0+ (1,0) [0|0] "mV" Vector__XXX
   SG_ GTW_WLAN_ANT_DET1 : 40|12@0+ (1,0) [0|0] "mV" Vector__XXX

BO_ 274 GTW_adc1: 8 Vector__XXX
   SG_ GTW_1V1_ETH : 24|12@0+ (1,0) [0|0] "mV" Vector__XXX
   SG_ GTW_1V5_ETH : 32|12@0+ (1,0) [0|0] "mV" Vector__XXX
   SG_ GTW_3V3_ETH : 0|12@0+ (1.03,0) [0|0] "mV" Vector__XXX
   SG_ GTW_3V3_SW : 8|12@0+ (1.5,0) [0|0] "mV" Vector__XXX
   SG_ GTW_5V0_SW : 48|12@0+ (2,0) [0|0] "mV" Vector__XXX

BO_ 275 GTW_adc2: 7 Vector__XXX
   SG_ GTW_12V0_DISP : 24|14@0+ (11,0) [0|0] "mV" Vector__XXX
   SG_ GTW_1V1_FPD : 40|12@0+ (1,0) [0|0] "mV" Vector__XXX
   SG_ GTW_1V8_GSM : 8|12@0+ (1,0) [0|0] "mV" Vector__XXX
   SG_ GTW_GSM_MDM_VNDR : 0|12@0+ (1,0) [0|0] "mV" Vector__XXX

BO_ 276 GTW_adc3: 8 Vector__XXX
   SG_ GTW_1V2_CSI : 24|12@0+ (1,0) [0|0] "mV" Vector__XXX
   SG_ GTW_1V8_VID : 8|12@0+ (1,0) [0|0] "mV" Vector__XXX
   SG_ GTW_1V8_VIO : 0|12@0+ (2,0) [0|0] "mV" Vector__XXX
   SG_ GTW_3V3_BMP : 32|12@0+ (2,0) [0|0] "mV" Vector__XXX
   SG_ GTW_GSM_BRD_REV : 48|12@0+ (1,0) [0|0] "mV" Vector__XXX

BO_ 62 GTW_alertMatrix: 8 Vector__XXX
   SG_ GTW_matrixIndex M : 0|4@1+ (1,0) [0|0] "" Vector__XXX
   SG_ GTW_w000_GTW_ALERT_DO_NOT_USE m0 : 4|1@1+ (1,0) [0|0] "" Vector__XXX
   SG_ GTW_w001_canEthTxQueue m0 : 5|1@1+ (1,0) [0|0] "" Vector__XXX
   SG_ GTW_w002_taskError m0 : 6|1@1+ (1,0) [0|0] "" Vector__XXX
   SG_ GTW_w003_logWriteRecord m0 : 7|1@1+ (1,0) [0|0] "" Vector__XXX
   SG_ GTW_w004_mallocHook m0 : 8|1@1+ (1,0) [0|0] "" Vector__XXX
   SG_ GTW_w005_stackOverflowHook m0 : 9|1@1+ (1,0) [0|0] "" Vector__XXX
   SG_ GTW_w006_ifTxOutputFull m0 : 10|1@1+ (1,0) [0|0] "" Vector__XXX
   SG_ GTW_w007_ifRxBufError m0 : 11|1@1+ (1,0) [0|0] "" Vector__XXX
   SG_ GTW_w008_ifPbufAllocError m0 : 12|1@1+ (1,0) [0|0] "" Vector__XXX
   SG_ GTW_w009_lateTask m0 : 13|1@1+ (1,0) [0|0] "" Vector__XXX
   SG_ GTW_w010_wdTaskCount m0 : 14|1@1+ (1,0) [0|0] "" Vector__XXX
   SG_ GTW_w011_cancoreWatchdog m0 : 15|1@1+ (1,0) [0|0] "" Vector__XXX
   SG_ GTW_w012_maincoreWatchdog m0 : 16|1@1+ (1,0) [0|0] "" Vector__XXX
   SG_ GTW_w014_APSversionMismatch m0 : 17|1@1+ (1,0) [0|0] "" Vector__XXX
   SG_ GTW_w015_DISversionMismatch m0 : 18|1@1+ (1,0) [0|0] "" Vector__XXX
   SG_ GTW_w016_BLEEPversionMismatch m0 : 19|1@1+ (1,0) [0|0] "" Vector__XXX
   SG_ GTW_w017_BMSversionMismatch m0 : 20|1@1+ (1,0) [0|0] "" Vector__XXX
   SG_ GTW_w018_CMPversionMismatch m0 : 21|1@1+ (1,0) [0|0] "" Vector__XXX
   SG_ GTW_w019_CPversionMismatch m0 : 22|1@1+ (1,0) [0|0] "" Vector__XXX
   SG_ GTW_w020_DIversionMismatch m0 : 23|1@1+ (1,0) [0|0] "" Vector__XXX
   SG_ GTW_w021_EPAS3PversionMismatch m0 : 24|1@1+ (1,0) [0|0] "" Vector__XXX
   SG_ GTW_w022_EPBLversionMismatch m0 : 25|1@1+ (1,0) [0|0] "" Vector__XXX
   SG_ GTW_w023_EPBRversionMismatch m0 : 26|1@1+ (1,0) [0|0] "" Vector__XXX
   SG_ GTW_w024_ESPversionMismatch m0 : 27|1@1+ (1,0) [0|0] "" Vector__XXX
   SG_ GTW_w025_ESPCALversionMismatch m0 : 28|1@1+ (1,0) [0|0] "" Vector__XXX
   SG_ GTW_w026_GTWversionMismatch m0 : 29|1@1+ (1,0) [0|0] "" Vector__XXX
   SG_ GTW_w027_HVPversionMismatch m0 : 30|1@1+ (1,0) [0|0] "" Vector__XXX
   SG_ GTW_w028_IBSTversionMismatch m0 : 31|1@1+ (1,0) [0|0] "" Vector__XXX
   SG_ GTW_w029_IBSTCALversionMismatch m0 : 32|1@1+ (1,0) [0|0] "" Vector__XXX
   SG_ GTW_w030_OCS1PversionMismatch m0 : 33|1@1+ (1,0) [0|0] "" Vector__XXX
   SG_ GTW_w031_PARKversionMismatch m0 : 34|1@1+ (1,0) [0|0] "" Vector__XXX
   SG_ GTW_w032_PCSversionMismatch m0 : 35|1@1+ (1,0) [0|0] "" Vector__XXX
   SG_ GTW_w033_PCSCPU2versionMismatch m0 : 36|1@1+ (1,0) [0|0] "" Vector__XXX
   SG_ GTW_w034_PMversionMismatch m0 : 37|1@1+ (1,0) [0|0] "" Vector__XXX
   SG_ GTW_w035_PMSversionMismatch m0 : 38|1@1+ (1,0) [0|0] "" Vector__XXX
   SG_ GTW_w036_PTCversionMismatch m0 : 39|1@1+ (1,0) [0|0] "" Vector__XXX
   SG_ GTW_w037_RADCversionMismatch m0 : 40|1@1+ (1,0) [0|0] "" Vector__XXX
   SG_ GTW_w038_RCMversionMismatch m0 : 41|1@1+ (1,0) [0|0] "" Vector__XXX
   SG_ GTW_w039_RCMCALversionMismatch m0 : 42|1@1+ (1,0) [0|0] "" Vector__XXX
   SG_ GTW_w040_SCCMversionMismatch m0 : 43|1@1+ (1,0) [0|0] "" Vector__XXX
   SG_ GTW_w041_VCSECversionMismatch m0 : 44|1@1+ (1,0) [0|0] "" Vector__XXX
   SG_ GTW_w042_TASversionMismatch m0 : 45|1@1+ (1,0) [0|0] "" Vector__XXX
   SG_ GTW_w043_THSversionMismatch m0 : 46|1@1+ (1,0) [0|0] "" Vector__XXX
   SG_ GTW_w044_TPMSversionMismatch m0 : 47|1@1+ (1,0) [0|0] "" Vector__XXX
   SG_ GTW_w045_VCFRONTversionMismatch m0 : 48|1@1+ (1,0) [0|0] "" Vector__XXX
   SG_ GTW_w046_VCLEFTversionMismatch m0 : 49|1@1+ (1,0) [0|0] "" Vector__XXX
   SG_ GTW_w047_VCRIGHTversionMismatch m0 : 50|1@1+ (1,0) [0|0] "" Vector__XXX
   SG_ GTW_w048_EPAS3SversionMismatch m0 : 51|1@1+ (1,0) [0|0] "" Vector__XXX
   SG_ GTW_w049_corruptedManifest m0 : 52|1@1+ (1,0) [0|0] "" Vector__XXX
   SG_ GTW_w050_sdCardInitFailure m0 : 53|1@1+ (1,0) [0|0] "" Vector__XXX
   SG_ GTW_w051_sdCardFileSystemFailure m0 : 54|1@1+ (1,0) [0|0] "" Vector__XXX
   SG_ GTW_w052_ifTxSpans m0 : 55|1@1+ (1,0) [0|0] "" Vector__XXX
   SG_ GTW_w053_busSleepFailure m0 : 56|1@1+ (1,0) [0|0] "" Vector__XXX
   SG_ GTW_w054_OPCversionMismatch m0 : 57|1@1+ (1,0) [0|0] "" Vector__XXX
   SG_ GTW_w055_OPCSversionMismatch m0 : 58|1@1+ (1,0) [0|0] "" Vector__XXX
   SG_ GTW_w057_i2cFailure m0 : 59|1@1+ (1,0) [0|0] "" Vector__XXX
   SG_ GTW_w058_rtcAlarmFailure m0 : 60|1@1+ (1,0) [0|0] "" Vector__XXX
   SG_ GTW_w059_inFactoryMode m0 : 61|1@1+ (1,0) [0|0] "" Vector__XXX
   SG_ GTW_w060_unFused m0 : 62|1@1+ (1,0) [0|0] "" Vector__XXX
   SG_ GTW_w061_bmpSleepFailure m0 : 63|1@1+ (1,0) [0|0] "" Vector__XXX
   SG_ GTW_w062_bmpWatchdog m1 : 4|1@1+ (1,0) [0|0] "" Vector__XXX
   SG_ GTW_w063_VEH_canFault m1 : 5|1@1+ (1,0) [0|0] "" Vector__XXX
   SG_ GTW_w064_CH_canFault m1 : 6|1@1+ (1,0) [0|0] "" Vector__XXX
   SG_ GTW_w065_PARTY_canFault m1 : 7|1@1+ (1,0) [0|0] "" Vector__XXX
   SG_ GTW_w066_exception m1 : 8|1@1+ (1,0) [0|0] "" Vector__XXX
   SG_ GTW_w067_tcpDebug m1 : 9|1@1+ (1,0) [0|0] "" Vector__XXX
   SG_ GTW_w068_prodKeyMissing m1 : 10|1@1+ (1,0) [0|0] "" Vector__XXX
   SG_ GTW_w069_diskioErr m1 : 11|1@1+ (1,0) [0|0] "" Vector__XXX
   SG_ GTW_w070_hrlDump m1 : 12|1@1+ (1,0) [0|0] "" Vector__XXX
   SG_ GTW_w071_hrlTrigger m1 : 13|1@1+ (1,0) [0|0] "" Vector__XXX
   SG_ GTW_w072_updateFailure m1 : 14|1@1+ (1,0) [0|0] "" Vector__XXX
   SG_ GTW_w073_steeringWheelReset m1 : 15|1@1+ (1,0) [0|0] "" Vector__XXX
   SG_ GTW_w074_epas3pMIA m1 : 16|1@1+ (1,0) [0|0] "" Vector__XXX
   SG_ GTW_w075_epas3sMIA m1 : 17|1@1+ (1,0) [0|0] "" Vector__XXX
   SG_ GTW_w076_ethInterfaceReset m1 : 18|1@1+ (1,0) [0|0] "" Vector__XXX
   SG_ GTW_w077_bmpPmicError m1 : 19|1@1+ (1,0) [0|0] "" Vector__XXX
   SG_ GTW_w078_VEHbusOverloaded m1 : 20|1@1+ (1,0) [0|0] "" Vector__XXX
   SG_ GTW_w079_PARTYbusOverloaded m1 : 21|1@1+ (1,0) [0|0] "" Vector__XXX
   SG_ GTW_w080_CHbusOverloaded m1 : 22|1@1+ (1,0) [0|0] "" Vector__XXX
   SG_ GTW_w081_udsMessageRejected m1 : 23|1@1+ (1,0) [0|0] "" Vector__XXX
   SG_ GTW_w082_sdCardBSCorrupted m1 : 24|1@1+ (1,0) [0|0] "" Vector__XXX
   SG_ GTW_w083_udsMsgDroppedByTcpStack m1 : 25|1@1+ (1,0) [0|0] "" Vector__XXX
   SG_ GTW_w084_canFrameDropped m1 : 26|1@1+ (1,0) [0|0] "" Vector__XXX
   SG_ GTW_w085_iBoosterStuck m1 : 27|1@1+ (1,0) [0|0] "" Vector__XXX
   SG_ GTW_w086_ocu m1 : 28|1@1+ (1,0) [0|0] "" Vector__XXX
   SG_ GTW_w087_ocuInProgress m1 : 29|1@1+ (1,0) [0|0] "" Vector__XXX
   SG_ GTW_w088_sdCardInvReqParallel m1 : 30|1@1+ (1,0) [0|0] "" Vector__XXX
   SG_ GTW_w089_sdCardWatchdog m1 : 31|1@1+ (1,0) [0|0] "" Vector__XXX
   SG_ GTW_w090_ocuFailed m1 : 32|1@1+ (1,0) [0|0] "" Vector__XXX
   SG_ GTW_w091_lowStack m1 : 33|1@1+ (1,0) [0|0] "" Vector__XXX
   SG_ GTW_w092_sdCardInvReqZero m1 : 34|1@1+ (1,0) [0|0] "" Vector__XXX
   SG_ GTW_w093_sdCardInvReqOverflowBase m1 : 35|1@1+ (1,0) [0|0] "" Vector__XXX
   SG_ GTW_w094_sdCardInvReqOverflowCount m1 : 36|1@1+ (1,0) [0|0] "" Vector__XXX
   SG_ GTW_w095_sdCardFull m1 : 37|1@1+ (1,0) [0|0] "" Vector__XXX
   SG_ GTW_w096_sdCardFatCorrupted m1 : 38|1@1+ (1,0) [0|0] "" Vector__XXX
   SG_ GTW_w097_HCMLversionMismatch m1 : 39|1@1+ (1,0) [0|0] "" Vector__XXX
   SG_ GTW_w098_HCMRversionMismatch m1 : 40|1@1+ (1,0) [0|0] "" Vector__XXX
   SG_ GTW_w099_SWCversionMismatch m1 : 41|1@1+ (1,0) [0|0] "" Vector__XXX
   SG_ GTW_w100_CBCversionMismatch m1 : 42|1@1+ (1,0) [0|0] "" Vector__XXX
   SG_ GTW_w101_switchWatchdog m1 : 43|1@1+ (1,0) [0|0] "" Vector__XXX
   SG_ GTW_w103_sdCardFormatted m1 : 44|1@1+ (1,0) [0|0] "" Vector__XXX
   SG_ GTW_w104_sdCardDriverArgCorrupted m1 : 45|1@1+ (1,0) [0|0] "" Vector__XXX
   SG_ GTW_w105_eBuckConfigured m1 : 46|1@1+ (1,0) [0|0] "" Vector__XXX
   SG_ GTW_w106_failedToStartUpdater m1 : 47|1@1+ (1,0) [0|0] "" Vector__XXX

BO_ 281 GTW_busLoadInfo: 3 Vector__XXX
   SG_ GTW_CHbusLoadPercent : 16|7@1+ (1,0) [0|0] "percent" Vector__XXX
   SG_ GTW_PARTYbusLoadPercent : 8|7@1+ (1,0) [0|0] "percent" Vector__XXX
   SG_ GTW_VEHbusLoadPercent : 0|7@1+ (1,0) [0|0] "percent" Vector__XXX

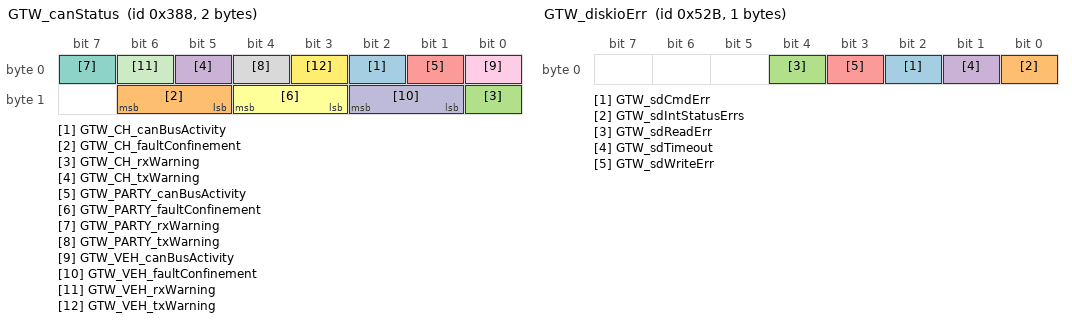
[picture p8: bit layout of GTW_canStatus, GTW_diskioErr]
BO_ 904 GTW_canStatus: 2 Vector__XXX
   SG_ GTW_CH_canBusActivity : 2|1@1+ (1,0) [0|0] "" Vector__XXX
   SG_ GTW_CH_faultConfinement : 13|2@1+ (1,0) [0|0] "" Vector__XXX
   SG_ GTW_CH_rxWarning : 8|1@1+ (1,0) [0|0] "" Vector__XXX
   SG_ GTW_CH_txWarning : 5|1@1+ (1,0) [0|0] "" Vector__XXX
   SG_ GTW_PARTY_canBusActivity : 1|1@1+ (1,0) [0|0] "" Vector__XXX
   SG_ GTW_PARTY_faultConfinement : 11|2@1+ (1,0) [0|0] "" Vector__XXX
   SG_ GTW_PARTY_rxWarning : 7|1@1+ (1,0) [0|0] "" Vector__XXX
   SG_ GTW_PARTY_txWarning : 4|1@1+ (1,0) [0|0] "" Vector__XXX
   SG_ GTW_VEH_canBusActivity : 0|1@1+ (1,0) [0|0] "" Vector__XXX
   SG_ GTW_VEH_faultConfinement : 9|2@1+ (1,0) [0|0] "" Vector__XXX
   SG_ GTW_VEH_rxWarning : 6|1@1+ (1,0) [0|0] "" Vector__XXX
   SG_ GTW_VEH_txWarning : 3|1@1+ (1,0) [0|0] "" Vector__XXX

BO_ 2047 GTW_carConfig: 8 Vector__XXX
   SG_ GTW_carConfigMultiplexer M : 0|8@1+ (1,0) [0|0] "" Vector__XXX
   SG_ GTW_airSuspension m1 : 8|1@1+ (1,0) [0|0] "" Vector__XXX
   SG_ GTW_epasType m1 : 9|1@1+ (1,0) [0|0] "" Vector__XXX
   SG_ GTW_drivetrainType m1 : 10|1@1+ (1,0) [0|0] "" Vector__XXX
   SG_ GTW_rightHandDrive m1 : 11|1@1+ (1,0) [0|0] "" Vector__XXX
   SG_ GTW_country m1 : 16|16@1+ (1,0) [0|0] "" Vector__XXX
   SG_ GTW_heatedWipers m2 : 8|1@1+ (1,0) [0|0] "" Vector__XXX
   SG_ GTW_frontSeatHeaters m2 : 9|1@1+ (1,0) [0|0] "" Vector__XXX
   SG_ GTW_rearSeatHeaters m2 : 10|1@1+ (1,0) [0|0] "" Vector__XXX
   SG_ GTW_packEnergy m2 : 11|1@1+ (1,0) [0|0] "" Vector__XXX
   SG_ GTW_brakeHWType m2 : 12|1@1+ (1,0) [0|0] "" Vector__XXX
   SG_ GTW_homelinkType m2 : 13|1@1+ (1,0) [0|0] "" Vector__XXX
   SG_ GTW_vdcType m2 : 14|1@1+ (1,0) [0|0] "" Vector__XXX
   SG_ GTW_xcpIbst m2 : 15|1@1+ (1,0) [0|0] "" Vector__XXX
   SG_ GTW_xcpESP m2 : 16|1@1+ (1,0) [0|0] "" Vector__XXX
   SG_ GTW_memoryMirrors m2 : 17|1@1+ (1,0) [0|0] "" Vector__XXX
   SG_ GTW_powerSteeringColumn m2 : 18|1@1+ (1,0) [0|0] "" Vector__XXX
   SG_ GTW_interiorLighting m2 : 19|1@1+ (1,0) [0|0] "" Vector__XXX
   SG_ GTW_frontFogLamps m2 : 20|1@1+ (1,0) [0|0] "" Vector__XXX
   SG_ GTW_headlamps m2 : 21|1@1+ (1,0) [0|0] "" Vector__XXX
   SG_ GTW_audioType m2 : 22|1@1+ (1,0) [0|0] "" Vector__XXX
   SG_ GTW_lumbarECUType m2 : 23|1@1+ (1,0) [0|0] "" Vector__XXX
   SG_ GTW_ibstWakeType m2 : 24|1@1+ (1,0) [0|0] "" Vector__XXX
   SG_ GTW_frontSeatType m2 : 25|1@1+ (1,0) [0|0] "" Vector__XXX
   SG_ GTW_auxParkLamps m2 : 26|1@1+ (1,0) [0|0] "" Vector__XXX
   SG_ GTW_pedestrianWarningSound m2 : 27|1@1+ (1,0) [0|0] "" Vector__XXX
   SG_ GTW_hvacQuietSnorkelType m2 : 28|1@1+ (1,0) [0|0] "" Vector__XXX
   SG_ GTW_hvacPanelVaneType m2 : 29|1@1+ (1,0) [0|0] "" Vector__XXX
   SG_ GTW_CabinBlowerCtrlType m2 : 30|1@1+ (1,0) [0|0] "" Vector__XXX
   SG_ GTW_performancePackage m2 : 31|1@1+ (1,0) [0|0] "" Vector__XXX
   SG_ GTW_eBuckConfig m2 : 32|1@1+ (1,0) [0|0] "" Vector__XXX
   SG_ GTW_windshieldType m2 : 33|1@1+ (1,0) [0|0] "" Vector__XXX
   SG_ GTW_activeHighBeam m2 : 34|1@1+ (1,0) [0|0] "" Vector__XXX
   SG_ GTW_airbagCutoffSwitch m2 : 35|1@1+ (1,0) [0|0] "" Vector__XXX
   SG_ GTW_intrusionSensorType m2 : 36|1@1+ (1,0) [0|0] "" Vector__XXX
   SG_ GTW_spoilerType m2 : 37|1@1+ (1,0) [0|0] "" Vector__XXX
   SG_ GTW_rearGlassType m2 : 38|1@1+ (1,0) [0|0] "" Vector__XXX
   SG_ GTW_rearFogLamps m2 : 39|1@1+ (1,0) [0|0] "" Vector__XXX
   SG_ GTW_roofType m2 : 40|2@1+ (1,0) [0|0] "" Vector__XXX
   SG_ GTW_autopilot m2 : 42|2@1+ (1,0) [0|0] "" Vector__XXX
   SG_ GTW_superchargingAccess m2 : 44|2@1+ (1,0) [0|0] "" Vector__XXX
   SG_ GTW_wheelType m2 : 46|2@1+ (1,0) [0|0] "" Vector__XXX
   SG_ GTW_exteriorColor m2 : 48|3@1+ (1,0) [0|0] "" Vector__XXX
   SG_ GTW_numberHVILNodes m2 : 51|3@1+ (1,0) [0|0] "" Vector__XXX
   SG_ GTW_restraintsHardwareType m2 : 56|5@1+ (1,0) [0|0] "" Vector__XXX

BO_ 1323 GTW_diskioErr: 1 Vector__XXX
   SG_ GTW_sdCmdErr : 2|1@1+ (1,0) [0|0] "" Vector__XXX
   SG_ GTW_sdIntStatusErrs : 0|1@1+ (1,0) [0|0] "" Vector__XXX
   SG_ GTW_sdReadErr : 4|1@1+ (1,0) [0|0] "" Vector__XXX
   SG_ GTW_sdTimeout : 1|1@1+ (1,0) [0|0] "" Vector__XXX
   SG_ GTW_sdWriteErr : 3|1@1+ (1,0) [0|0] "" Vector__XXX

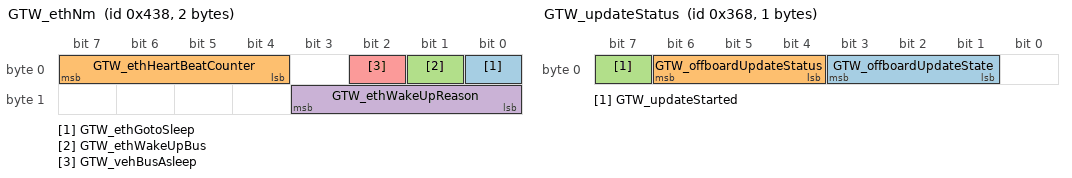
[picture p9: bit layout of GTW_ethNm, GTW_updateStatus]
BO_ 1080 GTW_ethNm: 2 Vector__XXX
   SG_ GTW_ethGotoSleep : 0|1@1+ (1,0) [0|0] "" Vector__XXX
   SG_ GTW_ethHeartBeatCounter : 4|4@1+ (1,0) [0|0] "" Vector__XXX
   SG_ GTW_ethWakeUpBus : 1|1@1+ (1,0) [0|0] "" Vector__XXX
   SG_ GTW_ethWakeUpReason : 8|4@1+ (1,0) [0|0] "" Vector__XXX
   SG_ GTW_vehBusAsleep : 2|1@1+ (1,0) [0|0] "" Vector__XXX

BO_ 1376 GTW_factoryEcuPresent: 4 Vector__XXX
   SG_ GTW_BMSpresent : 0|1@1+ (1,0) [0|0] "" Vector__XXX
   SG_ GTW_CMPpresent : 23|1@1+ (1,0) [0|0] "" Vector__XXX
   SG_ GTW_CPpresent : 26|1@1+ (1,0) [0|0] "" Vector__XXX
   SG_ GTW_DASpresent : 24|1@1+ (1,0) [0|0] "" Vector__XXX
   SG_ GTW_DISpresent : 2|1@1+ (1,0) [0|0] "" Vector__XXX
   SG_ GTW_DIpresent : 1|1@1+ (1,0) [0|0] "" Vector__XXX
   SG_ GTW_EPAS3Ppresent : 3|1@1+ (1,0) [0|0] "" Vector__XXX
   SG_ GTW_EPAS3Spresent : 22|1@1+ (1,0) [0|0] "" Vector__XXX
   SG_ GTW_EPBLpresent : 4|1@1+ (1,0) [0|0] "" Vector__XXX
   SG_ GTW_EPBRpresent : 5|1@1+ (1,0) [0|0] "" Vector__XXX
   SG_ GTW_ESPpresent : 6|1@1+ (1,0) [0|0] "" Vector__XXX
   SG_ GTW_HVPpresent : 7|1@1+ (1,0) [0|0] "" Vector__XXX
   SG_ GTW_IBSTpresent : 8|1@1+ (1,0) [0|0] "" Vector__XXX
   SG_ GTW_OCS1Ppresent : 9|1@1+ (1,0) [0|0] "" Vector__XXX
   SG_ GTW_PARKpresent : 10|1@1+ (1,0) [0|0] "" Vector__XXX
   SG_ GTW_PCSpresent : 11|1@1+ (1,0) [0|0] "" Vector__XXX
   SG_ GTW_PMSpresent : 13|1@1+ (1,0) [0|0] "" Vector__XXX
   SG_ GTW_PMpresent : 12|1@1+ (1,0) [0|0] "" Vector__XXX
   SG_ GTW_PTCpresent : 25|1@1+ (1,0) [0|0] "" Vector__XXX
   SG_ GTW_RADCpresent : 14|1@1+ (1,0) [0|0] "" Vector__XXX
   SG_ GTW_RCMpresent : 15|1@1+ (1,0) [0|0] "" Vector__XXX
   SG_ GTW_SCCMpresent : 16|1@1+ (1,0) [0|0] "" Vector__XXX
   SG_ GTW_SWCpresent : 27|1@1+ (1,0) [0|0] "" Vector__XXX
   SG_ GTW_TPMSpresent : 18|1@1+ (1,0) [0|0] "" Vector__XXX
   SG_ GTW_VCFRONTpresent : 19|1@1+ (1,0) [0|0] "" Vector__XXX
   SG_ GTW_VCLEFTpresent : 20|1@1+ (1,0) [0|0] "" Vector__XXX
   SG_ GTW_VCRIGHTpresent : 21|1@1+ (1,0) [0|0] "" Vector__XXX
   SG_ GTW_VCSECpresent : 17|1@1+ (1,0) [0|0] "" Vector__XXX

BO_ 2033 GTW_hrl: 7 Vector__XXX
   SG_ GTW_hrlIndex M : 0|2@1+ (1,0) [0|0] "" Vector__XXX
   SG_ GTW_hrlPagesCount m1 : 8|32@0+ (1,0) [0|0] "" Vector__XXX
   SG_ GTW_hrlState m2 : 2|1@1+ (1,0) [0|0] "" Vector__XXX
   SG_ GTW_hrlTriggerDuration m2 : 8|16@0+ (1,0) [0|0] "seconds" Vector__XXX
   SG_ GTW_hrlTriggerType m2 : 24|4@1+ (1,0) [0|0] "" Vector__XXX
   SG_ GTW_hrlTriggerId m2 : 32|16@0+ (1,0) [0|0] "" Vector__XXX
   SG_ GTW_hrlTriggerBus m2 : 48|3@1+ (1,0) [0|0] "" Vector__XXX

BO_ 60 GTW_info: 8 Vector__XXX
   SG_ GTW_infoIndex M : 0|8@1+ (1,0) [0|0] "" Vector__XXX
   SG_ GTW_applicationGitHash m17 : 10|54@1+ (4,0) [0|0] "" Vector__XXX
   SG_ GTW_buildType m10 : 8|3@1+ (1,0) [0|0] "" Vector__XXX
   SG_ GTW_hardwareId m10 : 32|16@1+ (1,0) [0|0] "" Vector__XXX
   SG_ GTW_bootGitHash m18 : 10|54@1+ (4,0) [0|0] "" Vector__XXX
   SG_ GTW_bootCrc m20 : 32|32@1+ (1,0) [0|0] "" Vector__XXX
   SG_ GTW_platformType m13 : 8|8@1+ (1,0) [0|0] "" Vector__XXX
   SG_ GTW_appCrc m13 : 32|32@1+ (1,0) [0|0] "" Vector__XXX

BO_ 840 GTW_status: 1 Vector__XXX
   SG_ GTW_autopilotTrial : 0|1@1+ (1,0) [0|0] "" Vector__XXX
   SG_ GTW_vehicleVersionMatchStatus : 1|2@1+ (1,0) [0|0] "" Vector__XXX

BO_ 872 GTW_updateStatus: 1 Vector__XXX
   SG_ GTW_offboardUpdateState : 1|3@1+ (1,0) [0|0] "" Vector__XXX
   SG_ GTW_offboardUpdateStatus : 4|3@1+ (1,0) [0|0] "" Vector__XXX
   SG_ GTW_updateStarted : 7|1@1+ (1,0) [0|0] "" Vector__XXX

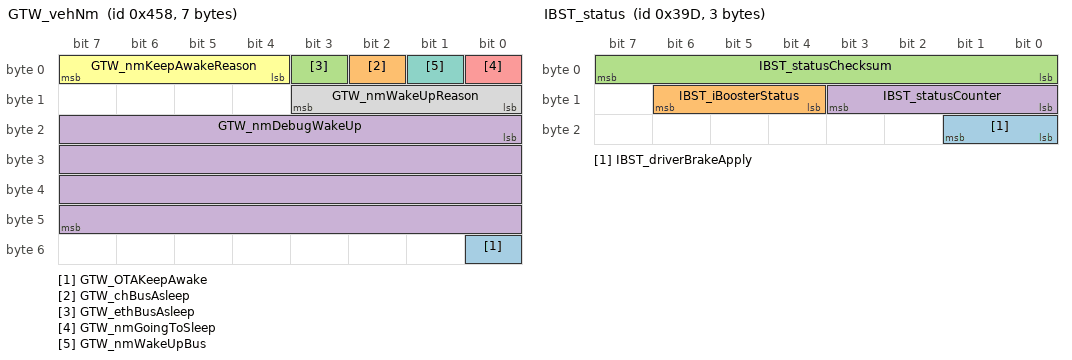
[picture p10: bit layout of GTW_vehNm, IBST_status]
BO_ 1112 GTW_vehNm: 7 Vector__XXX
   SG_ GTW_OTAKeepAwake : 48|1@1+ (1,0) [0|0] "" Vector__XXX
   SG_ GTW_chBusAsleep : 2|1@1+ (1,0) [0|0] "" Vector__XXX
   SG_ GTW_ethBusAsleep : 3|1@1+ (1,0) [0|0] "" Vector__XXX
   SG_ GTW_nmDebugWakeUp : 16|32@1+ (1,0) [0|0] "" Vector__XXX
   SG_ GTW_nmGoingToSleep : 0|1@1+ (1,0) [0|0] "" Vector__XXX
   SG_ GTW_nmKeepAwakeReason : 4|4@1+ (1,0) [0|0] "" Vector__XXX
   SG_ GTW_nmWakeUpBus : 1|1@1+ (1,0) [0|0] "" Vector__XXX
   SG_ GTW_nmWakeUpReason : 8|4@1+ (1,0) [0|0] "" Vector__XXX

BO_ 938 HVP_alertMatrix1: 8 Vector__XXX
   SG_ HVP_w001_WatchdogReset : 0|1@1+ (1,0) [0|0] "" Vector__XXX
   SG_ HVP_w002_UnusedAlert2 : 1|1@1+ (1,0) [0|0] "" Vector__XXX
   SG_ HVP_w003_SwAssertion : 2|1@1+ (1,0) [0|0] "" Vector__XXX
   SG_ HVP_w004_CrashEvent : 3|1@1+ (1,0) [0|0] "" Vector__XXX
   SG_ HVP_w005_OverDchgCurrentFault : 4|1@1+ (1,0) [0|0] "" Vector__XXX
   SG_ HVP_w006_OverChargeCurrentFault : 5|1@1+ (1,0) [0|0] "" Vector__XXX
   SG_ HVP_w007_OverCurrentFault : 6|1@1+ (1,0) [0|0] "" Vector__XXX
   SG_ HVP_w008_OverTemperatureFault : 7|1@1+ (1,0) [0|0] "" Vector__XXX
   SG_ HVP_w009_OverVoltageFault : 8|1@1+ (1,0) [0|0] "" Vector__XXX
   SG_ HVP_w010_UnderVoltageFault : 9|1@1+ (1,0) [0|0] "" Vector__XXX
   SG_ HVP_w011_PrimaryBmbMiaFault : 10|1@1+ (1,0) [0|0] "" Vector__XXX
   SG_ HVP_w012_SecondaryBmbMiaFault : 11|1@1+ (1,0) [0|0] "" Vector__XXX
   SG_ HVP_w013_BmbMismatchFault : 12|1@1+ (1,0) [0|0] "" Vector__XXX
   SG_ HVP_w014_BmsHviMiaFault : 13|1@1+ (1,0) [0|0] "" Vector__XXX
   SG_ HVP_w015_CpMiaFault : 14|1@1+ (1,0) [0|0] "" Vector__XXX
   SG_ HVP_w016_PcsMiaFault : 15|1@1+ (1,0) [0|0] "" Vector__XXX
   SG_ HVP_w017_BmsFault : 16|1@1+ (1,0) [0|0] "" Vector__XXX
   SG_ HVP_w018_PcsFault : 17|1@1+ (1,0) [0|0] "" Vector__XXX
   SG_ HVP_w019_CpFault : 18|1@1+ (1,0) [0|0] "" Vector__XXX
   SG_ HVP_w020_ShuntHwMiaFault : 19|1@1+ (1,0) [0|0] "" Vector__XXX
   SG_ HVP_w021_PyroMiaFault : 20|1@1+ (1,0) [0|0] "" Vector__XXX
   SG_ HVP_w022_hvsMiaFault : 21|1@1+ (1,0) [0|0] "" Vector__XXX
   SG_ HVP_w024_Supply12vFault : 23|1@1+ (1,0) [0|0] "" Vector__XXX
   SG_ HVP_w025_VerSupplyFault : 24|1@1+ (1,0) [0|0] "" Vector__XXX
   SG_ HVP_w026_HvilFault : 25|1@1+ (1,0) [0|0] "" Vector__XXX
   SG_ HVP_w027_BmsHvsMiaFault : 26|1@1+ (1,0) [0|0] "" Vector__XXX
   SG_ HVP_w028_PackVoltMismatchFault : 27|1@1+ (1,0) [0|0] "" Vector__XXX
   SG_ HVP_w029_EnsMiaFault : 28|1@1+ (1,0) [0|0] "" Vector__XXX
   SG_ HVP_w030_PackPosCtrArcFault : 29|1@1+ (1,0) [0|0] "" Vector__XXX
   SG_ HVP_w031_packNegCtrArcFault : 30|1@1+ (1,0) [0|0] "" Vector__XXX
   SG_ HVP_w032_ShuntHwAndBmsMiaFault : 31|1@1+ (1,0) [0|0] "" Vector__XXX
   SG_ HVP_w033_fcContHwFault : 32|1@1+ (1,0) [0|0] "" Vector__XXX
   SG_ HVP_w034_robinOverVoltageFault : 33|1@1+ (1,0) [0|0] "" Vector__XXX
   SG_ HVP_w035_packContHwFault : 34|1@1+ (1,0) [0|0] "" Vector__XXX
   SG_ HVP_w036_pyroFuseBlown : 35|1@1+ (1,0) [0|0] "" Vector__XXX
   SG_ HVP_w037_pyroFuseFailedToBlow : 36|1@1+ (1,0) [0|0] "" Vector__XXX
   SG_ HVP_w038_CpilFault : 37|1@1+ (1,0) [0|0] "" Vector__XXX
   SG_ HVP_w039_PackContactorFellOpen : 38|1@1+ (1,0) [0|0] "" Vector__XXX
   SG_ HVP_w040_FcContactorFellOpen : 39|1@1+ (1,0) [0|0] "" Vector__XXX
   SG_ HVP_w041_packCtrCloseBlocked : 40|1@1+ (1,0) [0|0] "" Vector__XXX
   SG_ HVP_w042_fcCtrCloseBlocked : 41|1@1+ (1,0) [0|0] "" Vector__XXX
   SG_ HVP_w043_packContactorForceOpen : 42|1@1+ (1,0) [0|0] "" Vector__XXX
   SG_ HVP_w044_fcContactorForceOpen : 43|1@1+ (1,0) [0|0] "" Vector__XXX
   SG_ HVP_w045_dcLinkOverVoltage : 44|1@1+ (1,0) [0|0] "" Vector__XXX
   SG_ HVP_w046_shuntOverTemperature : 45|1@1+ (1,0) [0|0] "" Vector__XXX
   SG_ HVP_w047_passivePyroDeploy : 46|1@1+ (1,0) [0|0] "" Vector__XXX
   SG_ HVP_w048_logUploadRequest : 47|1@1+ (1,0) [0|0] "" Vector__XXX
   SG_ HVP_w049_packCtrCloseFailed : 48|1@1+ (1,0) [0|0] "" Vector__XXX
   SG_ HVP_w050_fcCtrCloseFailed : 49|1@1+ (1,0) [0|0] "" Vector__XXX
   SG_ HVP_w051_shuntThermistorMia : 50|1@1+ (1,0) [0|0] "" Vector__XXX

BO_ 522 HVP_contactorState: 6 Vector__XXX
   SG_ HVP_dcLinkAllowedToEnergize : 38|1@1+ (1,0) [0|0] "" Vector__XXX
   SG_ HVP_fcContNegativeState : 12|3@1+ (1,0) [0|0] "" Vector__XXX
   SG_ HVP_fcContPositiveState : 16|3@1+ (1,0) [0|0] "" Vector__XXX
   SG_ HVP_fcContactorSetState : 19|4@1+ (1,0) [0|0] "" Vector__XXX
   SG_ HVP_fcCtrsClosingAllowed : 29|1@1+ (1,0) [0|0] "" Vector__XXX
   SG_ HVP_fcCtrsOpenNowRequested : 27|1@1+ (1,0) [0|0] "" Vector__XXX
   SG_ HVP_fcCtrsOpenRequested : 28|1@1+ (1,0) [0|0] "" Vector__XXX
   SG_ HVP_fcCtrsRequestStatus : 24|2@1+ (1,0) [0|0] "" Vector__XXX
   SG_ HVP_fcCtrsResetRequestRequired : 26|1@1+ (1,0) [0|0] "" Vector__XXX
   SG_ HVP_fcLinkAllowedToEnergizeAc : 30|1@1+ (1,0) [0|0] "" Vector__XXX
   SG_ HVP_fcLinkAllowedToEnergizeDc : 31|1@1+ (1,0) [0|0] "" Vector__XXX
   SG_ HVP_hvilStatus : 40|4@1+ (1,0) [0|0] "" Vector__XXX
   SG_ HVP_packContNegativeState : 0|3@1+ (1,0) [0|0] "" Vector__XXX
   SG_ HVP_packContPositiveState : 3|3@1+ (1,0) [0|0] "" Vector__XXX
   SG_ HVP_packContactorSetState : 8|4@1+ (1,0) [0|0] "" Vector__XXX
   SG_ HVP_packCtrsClosingAllowed : 37|1@1+ (1,0) [0|0] "" Vector__XXX
   SG_ HVP_packCtrsOpenNowRequested : 35|1@1+ (1,0) [0|0] "" Vector__XXX
   SG_ HVP_packCtrsOpenRequested : 36|1@1+ (1,0) [0|0] "" Vector__XXX
   SG_ HVP_packCtrsRequestStatus : 32|2@1+ (1,0) [0|0] "" Vector__XXX
   SG_ HVP_packCtrsResetRequestRequired : 34|1@1+ (1,0) [0|0] "" Vector__XXX
   SG_ HVP_pyroTestInProgress : 39|1@1+ (1,0) [0|0] "" Vector__XXX

BO_ 1962 HVP_debugMessage: 8 Vector__XXX
   SG_ HVP_debugMessageMultiplexer M : 0|4@1+ (1,0) [0|0] "" Vector__XXX
   SG_ HVP_gpioPassivePyroDepl m0 : 4|1@1+ (1,0) [0|0] "" Vector__XXX
   SG_ HVP_gpioPyroIsoEn m0 : 5|1@1+ (1,0) [0|0] "" Vector__XXX
   SG_ HVP_gpioCpFaultIn m0 : 6|1@1+ (1,0) [0|0] "" Vector__XXX
   SG_ HVP_gpioPackContPowerEn m0 : 7|1@1+ (1,0) [0|0] "" Vector__XXX
   SG_ HVP_gpioHvCablesOk m0 : 8|1@1+ (1,0) [0|0] "" Vector__XXX
   SG_ HVP_gpioHvpSelfEnable m0 : 9|1@1+ (1,0) [0|0] "" Vector__XXX
   SG_ HVP_gpioLed m0 : 10|1@1+ (1,0) [0|0] "" Vector__XXX
   SG_ HVP_gpioCrashSignal m0 : 11|1@1+ (1,0) [0|0] "" Vector__XXX
   SG_ HVP_gpioShuntDataReady m0 : 12|1@1+ (1,0) [0|0] "" Vector__XXX
   SG_ HVP_gpioFcContPosAux m0 : 13|1@1+ (1,0) [0|0] "" Vector__XXX
   SG_ HVP_gpioFcContNegAux m0 : 14|1@1+ (1,0) [0|0] "" Vector__XXX
   SG_ HVP_gpioBmsEout m0 : 15|1@1+ (1,0) [0|0] "" Vector__XXX
   SG_ HVP_gpioCpFaultOut m0 : 16|1@1+ (1,0) [0|0] "" Vector__XXX
   SG_ HVP_gpioPyroPor m0 : 17|1@1+ (1,0) [0|0] "" Vector__XXX
   SG_ HVP_gpioShuntEn m0 : 18|1@1+ (1,0) [0|0] "" Vector__XXX
   SG_ HVP_gpioHvpVerEn m0 : 19|1@1+ (1,0) [0|0] "" Vector__XXX
   SG_ HVP_gpioPackCoontPosFlywheel m0 : 20|1@1+ (1,0) [0|0] "" Vector__XXX
   SG_ HVP_gpioCpLatchEnable m0 : 21|1@1+ (1,0) [0|0] "" Vector__XXX
   SG_ HVP_gpioPcsEnable m0 : 22|1@1+ (1,0) [0|0] "" Vector__XXX
   SG_ HVP_gpioPcsDcdcPwmEnable m0 : 23|1@1+ (1,0) [0|0] "" Vector__XXX
   SG_ HVP_gpioPcsChargePwmEnable m0 : 24|1@1+ (1,0) [0|0] "" Vector__XXX
   SG_ HVP_gpioFcContPowerEnable m0 : 25|1@1+ (1,0) [0|0] "" Vector__XXX
   SG_ HVP_gpioHvilEnable m0 : 26|1@1+ (1,0) [0|0] "" Vector__XXX
   SG_ HVP_gpioSecDrdy m0 : 27|1@1+ (1,0) [0|0] "" Vector__XXX
   SG_ HVP_hvp1v5Ref m0 : 28|12@1+ (0.1,0) [0|0] "V" Vector__XXX
   SG_ HVP_shuntCurrentDebug m0 : 40|16@1- (0.1,0) [0|0] "A" Vector__XXX
   SG_ HVP_packCurrentMia m0 : 56|1@1+ (1,0) [0|0] "" Vector__XXX
   SG_ HVP_auxCurrentMia m0 : 57|1@1+ (1,0) [0|0] "" Vector__XXX
   SG_ HVP_currentSenseMia m0 : 58|1@1+ (1,0) [0|0] "" Vector__XXX
   SG_ HVP_shuntRefVoltageMismatch m0 : 59|1@1+ (1,0) [0|0] "" Vector__XXX
   SG_ HVP_shuntThermistorMia m0 : 60|1@1+ (1,0) [0|0] "" Vector__XXX
   SG_ HVP_shuntHwMia m0 : 61|1@1+ (1,0) [0|0] "" Vector__XXX
   SG_ HVP_dcLinkVoltage m1 : 8|16@1- (0.1,0) [0|0] "V" Vector__XXX
   SG_ HVP_packVoltage m1 : 24|16@1- (0.1,0) [0|0] "V" Vector__XXX
   SG_ HVP_fcLinkVoltage m1 : 40|16@1- (0.1,0) [0|0] "V" Vector__XXX
   SG_ HVP_packContVoltage m2 : 4|12@1+ (0.1,0) [0|0] "V" Vector__XXX
   SG_ HVP_packNegativeV m2 : 16|16@1- (0.1,0) [0|0] "V" Vector__XXX
   SG_ HVP_packPositiveV m2 : 32|16@1- (0.1,0) [0|0] "V" Vector__XXX
   SG_ HVP_pyroAnalog m2 : 48|12@1+ (0.1,0) [0|0] "V" Vector__XXX
   SG_ HVP_dcLinkNegativeV m3 : 8|16@1- (0.1,0) [0|0] "V" Vector__XXX
   SG_ HVP_dcLinkPositiveV m3 : 24|16@1- (0.1,0) [0|0] "V" Vector__XXX
   SG_ HVP_fcLinkNegativeV m3 : 40|16@1- (0.1,0) [0|0] "V" Vector__XXX
   SG_ HVP_fcContCoilCurrent m4 : 4|12@1+ (0.1,0) [0|0] "A" Vector__XXX
   SG_ HVP_fcContVoltage m4 : 16|12@1+ (0.1,0) [0|0] "V" Vector__XXX
   SG_ HVP_hvilInVoltage m4 : 28|12@1+ (0.1,0) [0|0] "V" Vector__XXX
   SG_ HVP_hvilOutVoltage m4 : 40|12@1+ (0.1,0) [0|0] "V" Vector__XXX
   SG_ HVP_fcLinkPositiveV m5 : 8|16@1- (0.1,0) [0|0] "V" Vector__XXX
   SG_ HVP_packContCoilCurrent m5 : 24|12@1+ (0.1,0) [0|0] "A" Vector__XXX
   SG_ HVP_battery12V m5 : 36|12@1+ (0.1,0) [0|0] "V" Vector__XXX
   SG_ HVP_shuntRefVoltageDbg m5 : 48|16@1- (0.001,0) [0|0] "V" Vector__XXX
   SG_ HVP_shuntAuxCurrentDbg m6 : 8|16@1- (0.1,0) [0|0] "A" Vector__XXX
   SG_ HVP_shuntBarTempDbg m6 : 24|16@1- (0.01,0) [0|0] "C" Vector__XXX
   SG_ HVP_shuntAsicTempDbg m6 : 40|16@1- (0.1,0) [0|0] "C" Vector__XXX

BO_ 784 HVP_info: 8 Vector__XXX
   SG_ HVP_infoIndex M : 0|8@1+ (1,0) [0|0] "" Vector__XXX
   SG_ HVP_buildType m10 : 8|3@1+ (1,0) [0|0] "" Vector__XXX
   SG_ HVP_buildConfigId m10 : 16|16@1+ (1,0) [0|0] "" Vector__XXX
   SG_ HVP_hardwareId m10 : 32|16@1+ (1,0) [0|0] "" Vector__XXX
   SG_ HVP_componentId m10 : 48|16@1+ (1,0) [0|0] "" Vector__XXX
   SG_ HVP_pcbaId m11 : 16|8@1+ (1,0) [0|0] "" Vector__XXX
   SG_ HVP_assemblyId m11 : 24|8@1+ (1,0) [0|0] "" Vector__XXX
   SG_ HVP_usageId m11 : 32|16@1+ (1,0) [0|0] "" Vector__XXX
   SG_ HVP_subUsageId m11 : 48|16@1+ (1,0) [0|0] "" Vector__XXX
   SG_ HVP_platformType m13 : 8|8@1+ (1,0) [0|0] "" Vector__XXX
   SG_ HVP_appCrc m13 : 32|32@1+ (1,0) [0|0] "" Vector__XXX
   SG_ HVP_appGitHash m17 : 10|54@1+ (4,0) [0|0] "" Vector__XXX
   SG_ HVP_bootGitHash m18 : 10|54@1+ (4,0) [0|0] "" Vector__XXX
   SG_ HVP_bootUdsProtoVersion m20 : 8|8@1+ (1,0) [0|0] "" Vector__XXX
   SG_ HVP_bootCrc m20 : 32|32@1+ (1,0) [0|0] "" Vector__XXX

BO_ 1553 HVP_udsResponse: 8 Vector__XXX
   SG_ HVP_udsResponseData : 0|54@0+ (1024,0) [0|0] "" Vector__XXX

BO_ 1898 HVP_vehicleDbg: 8 Vector__XXX
   SG_ HVP_ecuLogUploadRequest : 5|2@1+ (1,0) [0|0] "" Vector__XXX
   SG_ HVP_vehicleDebugMultiplexer M : 0|5@1+ (1,0) [0|0] "" Vector__XXX
   SG_ HVP_packNegativeContPwmDuty m0 : 8|14@1+ (0.01,0) [0|0] "%" Vector__XXX
   SG_ HVP_packPositiveContPwmDuty m0 : 22|14@1+ (0.01,0) [0|0] "%" Vector__XXX
   SG_ HVP_FcPositiveContPwmDuty m0 : 36|14@1+ (0.01,0) [0|0] "%" Vector__XXX
   SG_ HVP_FcNegativeContPwmDuty m0 : 50|14@1+ (0.01,0) [0|0] "%" Vector__XXX
   SG_ HVP_maxRobinBrickV m1 : 8|16@1- (0.001,0) [0|0] "V" Vector__XXX
   SG_ HVP_maxRobinBrickId m1 : 24|7@1+ (1,1) [0|0] "" Vector__XXX
   SG_ HVP_minRobinBrickV m1 : 32|16@1- (0.001,0) [0|0] "V" Vector__XXX
   SG_ HVP_minRobinBrickId m1 : 48|7@1+ (1,1) [0|0] "" Vector__XXX
   SG_ HVP_avgRobinBrickV m2 : 8|16@1- (0.001,0) [0|0] "V" Vector__XXX

BO_ 861 IBST_alertMatrix: 8 Vector__XXX
   SG_ IBST_matrixIndex M : 0|4@1+ (1,0) [0|0] "" Vector__XXX
   SG_ IBST_a001_microSupplyError m0 : 4|1@1+ (1,0) [0|0] "" Vector__XXX
   SG_ IBST_a002_HWBISTError m0 : 5|1@1+ (1,0) [0|0] "" Vector__XXX
   SG_ IBST_a003_RAMFault m0 : 6|1@1+ (1,0) [0|0] "" Vector__XXX
   SG_ IBST_a004_flashFault m0 : 7|1@1+ (1,0) [0|0] "" Vector__XXX
   SG_ IBST_a005_microSafetyFault m0 : 8|1@1+ (1,0) [0|0] "" Vector__XXX
   SG_ IBST_a006_microSafetyLogicFault m0 : 9|1@1+ (1,0) [0|0] "" Vector__XXX
   SG_ IBST_a007_RBCPUException m0 : 10|1@1+ (1,0) [0|0] "" Vector__XXX
   SG_ IBST_a008_stackOverUnderFlow m0 : 11|1@1+ (1,0) [0|0] "" Vector__XXX
   SG_ IBST_a009_systemErrorHook m0 : 12|1@1+ (1,0) [0|0] "" Vector__XXX
   SG_ IBST_a010_OSErrorHook m0 : 13|1@1+ (1,0) [0|0] "" Vector__XXX
   SG_ IBST_a011_systemTaskOverRun m0 : 14|1@1+ (1,0) [0|0] "" Vector__XXX
   SG_ IBST_a012_OSTaskSchemeError m0 : 15|1@1+ (1,0) [0|0] "" Vector__XXX
   SG_ IBST_a013_systemTaskJitter m0 : 16|1@1+ (1,0) [0|0] "" Vector__XXX
   SG_ IBST_a014_DMATransferError m0 : 17|1@1+ (1,0) [0|0] "" Vector__XXX
   SG_ IBST_a015_asicOscillatorError m0 : 18|1@1+ (1,0) [0|0] "" Vector__XXX
   SG_ IBST_a016_RBBLMShaftShiftError m0 : 19|1@1+ (1,0) [0|0] "" Vector__XXX
   SG_ IBST_a017_assertionFault m0 : 20|1@1+ (1,0) [0|0] "" Vector__XXX
   SG_ IBST_a018_unsupportedHW m0 : 21|1@1+ (1,0) [0|0] "" Vector__XXX
   SG_ IBST_a019_supplyASICInitFault m0 : 22|1@1+ (1,0) [0|0] "" Vector__XXX
   SG_ IBST_a020_VPREU5VOutOfRange m0 : 23|1@1+ (1,0) [0|0] "" Vector__XXX
   SG_ IBST_a021_IREFOutOfRange m0 : 24|1@1+ (1,0) [0|0] "" Vector__XXX
   SG_ IBST_a022_U5VTestFault m0 : 25|1@1+ (1,0) [0|0] "" Vector__XXX
   SG_ IBST_a023_U5VOutOfRange m0 : 26|1@1+ (1,0) [0|0] "" Vector__XXX
   SG_ IBST_a024_chargePumpFault m0 : 27|1@1+ (1,0) [0|0] "" Vector__XXX
   SG_ IBST_a025_ecuClockTestFault m0 : 28|1@1+ (1,0) [0|0] "" Vector__XXX
   SG_ IBST_a026_ecuBistCmdTestFault m0 : 29|1@1+ (1,0) [0|0] "" Vector__XXX
   SG_ IBST_a027_ecuFastWdTestFault m0 : 30|1@1+ (1,0) [0|0] "" Vector__XXX
   SG_ IBST_a028_ecuBistFaultCtrFault m0 : 31|1@1+ (1,0) [0|0] "" Vector__XXX
   SG_ IBST_a029_ecuErrpinCounterFault m0 : 32|1@1+ (1,0) [0|0] "" Vector__XXX
   SG_ IBST_a030_ecuEnableElLowFault m0 : 33|1@1+ (1,0) [0|0] "" Vector__XXX
   SG_ IBST_a031_decoupleBitTestFault m0 : 34|1@1+ (1,0) [0|0] "" Vector__XXX
   SG_ IBST_a032_ecuEnableElHighFault m0 : 35|1@1+ (1,0) [0|0] "" Vector__XXX
   SG_ IBST_a033_ecuWdStartuptestFault m0 : 36|1@1+ (1,0) [0|0] "" Vector__XXX
   SG_ IBST_a034_ecuEnableHyHighFault m0 : 37|1@1+ (1,0) [0|0] "" Vector__XXX
   SG_ IBST_a035_ecuEnableHyLowFault m0 : 38|1@1+ (1,0) [0|0] "" Vector__XXX
   SG_ IBST_a036_MRGPathTestFault m0 : 39|1@1+ (1,0) [0|0] "" Vector__XXX
   SG_ IBST_a037_ecuWdSContinuousError m0 : 40|1@1+ (1,0) [0|0] "" Vector__XXX
   SG_ IBST_a038_ecuEnContinuousError m0 : 41|1@1+ (1,0) [0|0] "" Vector__XXX
   SG_ IBST_a039_GTMRefFrequencyError m0 : 42|1@1+ (1,0) [0|0] "" Vector__XXX
   SG_ IBST_a040_GTMTbuMonError m0 : 43|1@1+ (1,0) [0|0] "" Vector__XXX
   SG_ IBST_a041_micAsicClkInError m0 : 44|1@1+ (1,0) [0|0] "" Vector__XXX
   SG_ IBST_a042_micAsicInitTestError m0 : 45|1@1+ (1,0) [0|0] "" Vector__XXX
   SG_ IBST_a043_micSpiTransferError m0 : 46|1@1+ (1,0) [0|0] "" Vector__XXX
   SG_ IBST_a044_NvMEepromWIP m0 : 47|1@1+ (1,0) [0|0] "" Vector__XXX
   SG_ IBST_a045_WdhAsicWdErrorCntStuck m0 : 48|1@1+ (1,0) [0|0] "" Vector__XXX
   SG_ IBST_a046_WdhAsicWdErrorCntLimit m0 : 49|1@1+ (1,0) [0|0] "" Vector__XXX
   SG_ IBST_a047_WdhAsicWdCmdMissing m0 : 50|1@1+ (1,0) [0|0] "" Vector__XXX
   SG_ IBST_a048_WdhSwBistConCnt m0 : 51|1@1+ (1,0) [0|0] "" Vector__XXX
   SG_ IBST_a049_WdhTaskMonConCnt m0 : 52|1@1+ (1,0) [0|0] "" Vector__XXX
   SG_ IBST_a050_VPreExternalFeeding m0 : 53|1@1+ (1,0) [0|0] "" Vector__XXX
   SG_ IBST_a051_ecuBandgap m0 : 54|1@1+ (1,0) [0|0] "" Vector__XXX
   SG_ IBST_a052_AdcPinTest m0 : 55|1@1+ (1,0) [0|0] "" Vector__XXX
   SG_ IBST_a053_AdcSelftestC5P m0 : 56|1@1+ (1,0) [0|0] "" Vector__XXX
   SG_ IBST_a054_AdcPeripheralFault m0 : 57|1@1+ (1,0) [0|0] "" Vector__XXX
   SG_ IBST_a055_UB6SupplyPathFault m0 : 58|1@1+ (1,0) [0|0] "" Vector__XXX
   SG_ IBST_a056_UB6PlausiMonFault m0 : 59|1@1+ (1,0) [0|0] "" Vector__XXX
   SG_ IBST_a057_microRegisterFault m0 : 60|1@1+ (1,0) [0|0] "" Vector__XXX
   SG_ IBST_a058_NvMWriteCycleExceed m0 : 61|1@1+ (1,0) [0|0] "" Vector__XXX
   SG_ IBST_a059_NvMEepromSize m0 : 62|1@1+ (1,0) [0|0] "" Vector__XXX
   SG_ IBST_a060_NvMMigrationFault m0 : 63|1@1+ (1,0) [0|0] "" Vector__XXX
   SG_ IBST_a061_AswSystemTimeOut m1 : 4|1@1+ (1,0) [0|0] "" Vector__XXX
   SG_ IBST_a062_MICB6TransferError m1 : 5|1@1+ (1,0) [0|0] "" Vector__XXX
   SG_ IBST_a063_tempSens2ShortToSupply m1 : 6|1@1+ (1,0) [0|0] "" Vector__XXX
   SG_ IBST_a064_tempSens1ShortToGround m1 : 7|1@1+ (1,0) [0|0] "" Vector__XXX
   SG_ IBST_a065_tempSens2ShortToGround m1 : 8|1@1+ (1,0) [0|0] "" Vector__XXX
   SG_ IBST_a066_tempSens1ShortToSupply m1 : 9|1@1+ (1,0) [0|0] "" Vector__XXX
   SG_ IBST_a067_tempSensImplausVoltage m1 : 10|1@1+ (1,0) [0|0] "" Vector__XXX
   SG_ IBST_a068_chargePumpUndervoltage m1 : 11|1@1+ (1,0) [0|0] "" Vector__XXX
   SG_ IBST_a069_greasingRoutineFault m1 : 12|1@1+ (1,0) [0|0] "" Vector__XXX
   SG_ IBST_a070_notShutDownNvMWrite m1 : 13|1@1+ (1,0) [0|0] "" Vector__XXX
   SG_ IBST_a071_notShutDownNvMRead m1 : 14|1@1+ (1,0) [0|0] "" Vector__XXX
   SG_ IBST_a072_notShutDownRight m1 : 15|1@1+ (1,0) [0|0] "" Vector__XXX
   SG_ IBST_a073_jumpInAdjustNvMRead m1 : 16|1@1+ (1,0) [0|0] "" Vector__XXX
   SG_ IBST_a074_FindIdleDataNvMWrite m1 : 17|1@1+ (1,0) [0|0] "" Vector__XXX
   SG_ IBST_a075_FindIdleRoutineFault m1 : 18|1@1+ (1,0) [0|0] "" Vector__XXX
   SG_ IBST_a076_masterCylLengthRead m1 : 19|1@1+ (1,0) [0|0] "" Vector__XXX
   SG_ IBST_a077_runOutMotorSaturated m1 : 20|1@1+ (1,0) [0|0] "" Vector__XXX
   SG_ IBST_a078_wearOffsetCompNVMRead m1 : 21|1@1+ (1,0) [0|0] "" Vector__XXX
   SG_ IBST_a079_motorTempHighLevel1 m1 : 22|1@1+ (1,0) [0|0] "" Vector__XXX
   SG_ IBST_a080_motorTempHighLevel2 m1 : 23|1@1+ (1,0) [0|0] "" Vector__XXX
   SG_ IBST_a081_travelDeviation m1 : 24|1@1+ (1,0) [0|0] "" Vector__XXX
   SG_ IBST_a082_motorSpeedDeviation m1 : 25|1@1+ (1,0) [0|0] "" Vector__XXX
   SG_ IBST_a083_spindlePositionTooHigh m1 : 26|1@1+ (1,0) [0|0] "" Vector__XXX
   SG_ IBST_a084_CANTransceiverHWFault m1 : 27|1@1+ (1,0) [0|0] "" Vector__XXX
   SG_ IBST_a085_supplyUndervoltageLvl3 m1 : 28|1@1+ (1,0) [0|0] "" Vector__XXX
   SG_ IBST_a086_supplyOvervoltageLvl3 m1 : 29|1@1+ (1,0) [0|0] "" Vector__XXX
   SG_ IBST_a087_rotorSinOutOfRangeLow m1 : 30|1@1+ (1,0) [0|0] "" Vector__XXX
   SG_ IBST_a088_rotorCosOutOfRangeLow m1 : 31|1@1+ (1,0) [0|0] "" Vector__XXX
   SG_ IBST_a089_rotorSinOutOfRangeHigh m1 : 32|1@1+ (1,0) [0|0] "" Vector__XXX
   SG_ IBST_a090_rotorCosOutOfRangeHigh m1 : 33|1@1+ (1,0) [0|0] "" Vector__XXX
   SG_ IBST_a091_SMMOneRequestsInit m1 : 34|1@1+ (1,0) [0|0] "" Vector__XXX
   SG_ IBST_a092_systemStartTimeOut m1 : 35|1@1+ (1,0) [0|0] "" Vector__XXX
   SG_ IBST_a093_UEXSOvertemperature m1 : 36|1@1+ (1,0) [0|0] "" Vector__XXX
   SG_ IBST_a094_XPASSEchoTimeDeviation m1 : 37|1@1+ (1,0) [0|0] "" Vector__XXX
   SG_ IBST_a095_XPASSTimeOut m1 : 38|1@1+ (1,0) [0|0] "" Vector__XXX
   SG_ IBST_a096_bridgeDriverMonError m1 : 39|1@1+ (1,0) [0|0] "" Vector__XXX
   SG_ IBST_a097_bridgeDriverError m1 : 40|1@1+ (1,0) [0|0] "" Vector__XXX
   SG_ IBST_a098_bridgeShortedPhase m1 : 41|1@1+ (1,0) [0|0] "" Vector__XXX
   SG_ IBST_a099_bridgeSwitchInitError m1 : 42|1@1+ (1,0) [0|0] "" Vector__XXX
   SG_ IBST_a100_current2OffsetHigh m1 : 43|1@1+ (1,0) [0|0] "" Vector__XXX
   SG_ IBST_a101_current2OffsetLow m1 : 44|1@1+ (1,0) [0|0] "" Vector__XXX
   SG_ IBST_a102_current1OffsetHigh m1 : 45|1@1+ (1,0) [0|0] "" Vector__XXX
   SG_ IBST_a103_current1OffsetLow m1 : 46|1@1+ (1,0) [0|0] "" Vector__XXX
   SG_ IBST_a104_bridgeDriverShort m1 : 47|1@1+ (1,0) [0|0] "" Vector__XXX
   SG_ IBST_a105_LiPSUndervoltage m1 : 48|1@1+ (1,0) [0|0] "" Vector__XXX
   SG_ IBST_a106_LiPS5VSupply m1 : 49|1@1+ (1,0) [0|0] "" Vector__XXX
   SG_ IBST_a107_LiPS2PwmLineHigh m1 : 50|1@1+ (1,0) [0|0] "" Vector__XXX
   SG_ IBST_a108_LiPS2PwmLineLow m1 : 51|1@1+ (1,0) [0|0] "" Vector__XXX
   SG_ IBST_a109_LiPS2PwmTransmission m1 : 52|1@1+ (1,0) [0|0] "" Vector__XXX
   SG_ IBST_a110_LiPS1SentLineHigh m1 : 53|1@1+ (1,0) [0|0] "" Vector__XXX
   SG_ IBST_a111_LiPS1SentLineLow m1 : 54|1@1+ (1,0) [0|0] "" Vector__XXX
   SG_ IBST_a112_LiPS1SentTransmission m1 : 55|1@1+ (1,0) [0|0] "" Vector__XXX
   SG_ IBST_a113_LiPS1SentSensor m1 : 56|1@1+ (1,0) [0|0] "" Vector__XXX
   SG_ IBST_a114_partyBusOff m1 : 57|1@1+ (1,0) [0|0] "" Vector__XXX
   SG_ IBST_a115_chassisBusOff m1 : 58|1@1+ (1,0) [0|0] "" Vector__XXX
   SG_ IBST_a116_supplyUndervoltageLvl2 m1 : 59|1@1+ (1,0) [0|0] "" Vector__XXX
   SG_ IBST_a117_supplyOvervoltageLvl2 m1 : 60|1@1+ (1,0) [0|0] "" Vector__XXX
   SG_ IBST_a118_RPSNvMReadFault m1 : 61|1@1+ (1,0) [0|0] "" Vector__XXX
   SG_ IBST_a119_RPSWrongCalibData m1 : 62|1@1+ (1,0) [0|0] "" Vector__XXX
   SG_ IBST_a120_RPSVectorRangeHigh m1 : 63|1@1+ (1,0) [0|0] "" Vector__XXX
   SG_ IBST_a121_RPSVectorRangeLow m2 : 4|1@1+ (1,0) [0|0] "" Vector__XXX
   SG_ IBST_a122_RPSVectorOscillating m2 : 5|1@1+ (1,0) [0|0] "" Vector__XXX
   SG_ IBST_a123_bridgeDriverUnavail m2 : 6|1@1+ (1,0) [0|0] "" Vector__XXX
   SG_ IBST_a124_OBDCurrent1OORHigh m2 : 7|1@1+ (1,0) [0|0] "" Vector__XXX
   SG_ IBST_a125_OBDCurrent2OORHigh m2 : 8|1@1+ (1,0) [0|0] "" Vector__XXX
   SG_ IBST_a126_OBDCurrent1OORLow m2 : 9|1@1+ (1,0) [0|0] "" Vector__XXX
   SG_ IBST_a127_OBDCurrent2OORLow m2 : 10|1@1+ (1,0) [0|0] "" Vector__XXX
   SG_ IBST_a128_BLMMuxerTimeoutError m2 : 11|1@1+ (1,0) [0|0] "" Vector__XXX
   SG_ IBST_a129_loadDumpOnFSLTest m2 : 12|1@1+ (1,0) [0|0] "" Vector__XXX
   SG_ IBST_a130_DTSFunctionalRangeLow m2 : 13|1@1+ (1,0) [0|0] "" Vector__XXX
   SG_ IBST_a131_DTSFunctionalRangeHigh m2 : 14|1@1+ (1,0) [0|0] "" Vector__XXX
   SG_ IBST_a132_DTSPlausiCheck1vs2 m2 : 15|1@1+ (1,0) [0|0] "" Vector__XXX
   SG_ IBST_a133_DTSOffsetTooLow m2 : 16|1@1+ (1,0) [0|0] "" Vector__XXX
   SG_ IBST_a134_DTSOffsetTooHigh m2 : 17|1@1+ (1,0) [0|0] "" Vector__XXX
   SG_ IBST_a135_ESPparty1DLC m2 : 18|1@1+ (1,0) [0|0] "" Vector__XXX
   SG_ IBST_a136_ESPparty1Timeout m2 : 19|1@1+ (1,0) [0|0] "" Vector__XXX
   SG_ IBST_a137_ESPparty1Checksum m2 : 20|1@1+ (1,0) [0|0] "" Vector__XXX
   SG_ IBST_a138_ESPparty1Counter m2 : 21|1@1+ (1,0) [0|0] "" Vector__XXX
   SG_ IBST_a139_ESPparty2DLC m2 : 22|1@1+ (1,0) [0|0] "" Vector__XXX
   SG_ IBST_a140_ESPparty2Timeout m2 : 23|1@1+ (1,0) [0|0] "" Vector__XXX
   SG_ IBST_a141_ESPparty2Checksum m2 : 24|1@1+ (1,0) [0|0] "" Vector__XXX
   SG_ IBST_a142_ESPparty2Counter m2 : 25|1@1+ (1,0) [0|0] "" Vector__XXX
   SG_ IBST_a143_ESPparty3DLC m2 : 26|1@1+ (1,0) [0|0] "" Vector__XXX
   SG_ IBST_a144_ESPparty3Timeout m2 : 27|1@1+ (1,0) [0|0] "" Vector__XXX
   SG_ IBST_a145_ESPparty3Checksum m2 : 28|1@1+ (1,0) [0|0] "" Vector__XXX
   SG_ IBST_a146_ESPparty3Counter m2 : 29|1@1+ (1,0) [0|0] "" Vector__XXX
   SG_ IBST_a147_PSCMotorSizeReadFault m2 : 30|1@1+ (1,0) [0|0] "" Vector__XXX
   SG_ IBST_a148_MLIGainMechReadFault m2 : 31|1@1+ (1,0) [0|0] "" Vector__XXX
   SG_ IBST_a149_MLITMCAreaReadFault m2 : 32|1@1+ (1,0) [0|0] "" Vector__XXX
   SG_ IBST_a150_motorTestFault m2 : 33|1@1+ (1,0) [0|0] "" Vector__XXX
   SG_ IBST_a151_PSCGearRatioReadFault m2 : 34|1@1+ (1,0) [0|0] "" Vector__XXX
   SG_ IBST_a152_PSCVoltageImplausible m2 : 35|1@1+ (1,0) [0|0] "" Vector__XXX
   SG_ IBST_a153_PSCImpedanceTooHigh m2 : 36|1@1+ (1,0) [0|0] "" Vector__XXX
   SG_ IBST_a154_PSCImpedanceTooLow m2 : 37|1@1+ (1,0) [0|0] "" Vector__XXX
   SG_ IBST_a155_supplyUndervoltageLvl1 m2 : 38|1@1+ (1,0) [0|0] "" Vector__XXX
   SG_ IBST_a156_supplyOvervoltageLvl1 m2 : 39|1@1+ (1,0) [0|0] "" Vector__XXX
   SG_ IBST_a157_masterCylPressInvalid m2 : 40|1@1+ (1,0) [0|0] "" Vector__XXX
   SG_ IBST_a158_DTSOffsHighSuspicious m2 : 41|1@1+ (1,0) [0|0] "" Vector__XXX
   SG_ IBST_a159_FindIdleNvMReadError m2 : 42|1@1+ (1,0) [0|0] "" Vector__XXX
   SG_ IBST_a160_DTSIDTimeOut m2 : 43|1@1+ (1,0) [0|0] "" Vector__XXX
   SG_ IBST_a161_powerPackMismatch m2 : 44|1@1+ (1,0) [0|0] "" Vector__XXX
   SG_ IBST_a162_idlePosNotDetected m2 : 45|1@1+ (1,0) [0|0] "" Vector__XXX
   SG_ IBST_a163_ESPpEstMaxInvalid m2 : 46|1@1+ (1,0) [0|0] "" Vector__XXX
   SG_ IBST_a164_ESPVehicleSpeedInvalid m2 : 47|1@1+ (1,0) [0|0] "" Vector__XXX
   SG_ IBST_a165_ESPpForceBlendInvalid m2 : 48|1@1+ (1,0) [0|0] "" Vector__XXX
   SG_ IBST_a166_ESPpMcVirtualInvalid m2 : 49|1@1+ (1,0) [0|0] "" Vector__XXX
   SG_ IBST_a167_ESPqTargetExterInvalid m2 : 50|1@1+ (1,0) [0|0] "" Vector__XXX
   SG_ IBST_a168_CANOvervoltage m2 : 51|1@1+ (1,0) [0|0] "" Vector__XXX
   SG_ IBST_a169_CANUndervoltage m2 : 52|1@1+ (1,0) [0|0] "" Vector__XXX
   SG_ IBST_a170_LVPowerStateTimeout m2 : 53|1@1+ (1,0) [0|0] "" Vector__XXX
   SG_ IBST_a171_LVPowerStateChecksum m2 : 54|1@1+ (1,0) [0|0] "" Vector__XXX
   SG_ IBST_a172_LVPowerStateDLC m2 : 55|1@1+ (1,0) [0|0] "" Vector__XXX
   SG_ IBST_a173_LVPowerStateCounter m2 : 56|1@1+ (1,0) [0|0] "" Vector__XXX
   SG_ IBST_a174_LVOffStateInvalid m2 : 57|1@1+ (1,0) [0|0] "" Vector__XXX
   SG_ IBST_a175_LVGoingDownInvalid m2 : 58|1@1+ (1,0) [0|0] "" Vector__XXX

BO_ 813 IBST_info: 8 Vector__XXX
   SG_ IBST_infoIndex M : 0|8@1+ (1,0) [0|0] "" Vector__XXX
   SG_ IBST_infoBuildType m10 : 8|8@1+ (1,0) [0|0] "" Vector__XXX
   SG_ IBST_infoComponentID m10 : 48|16@1+ (1,0) [0|0] "" Vector__XXX
   SG_ IBST_infoPcbaID m11 : 16|8@1+ (1,0) [0|0] "" Vector__XXX
   SG_ IBST_infoAssemblyID m11 : 24|8@1+ (1,0) [0|0] "" Vector__XXX
   SG_ IBST_infoUsageID m11 : 32|16@1+ (1,0) [0|0] "" Vector__XXX
   SG_ IBST_infoBootUdsProtoVersion m20 : 8|8@1+ (1,0) [0|0] "" Vector__XXX
   SG_ IBST_infoBootloaderCRC m20 : 32|32@1+ (1,0) [0|0] "" Vector__XXX
   SG_ IBST_infoApplicationCRC m13 : 32|32@1+ (1,0) [0|0] "" Vector__XXX
   SG_ IBST_infoVariantCRC m22 : 32|32@1+ (1,0) [0|0] "" Vector__XXX

BO_ 925 IBST_status: 3 Vector__XXX
   SG_ IBST_driverBrakeApply : 16|2@1+ (1,0) [0|0] "" Vector__XXX
   SG_ IBST_iBoosterStatus : 12|3@1+ (1,0) [0|0] "" Vector__XXX
   SG_ IBST_statusChecksum : 0|8@1+ (1,0) [0|0] "" Vector__XXX
   SG_ IBST_statusCounter : 8|4@1+ (1,0) [0|0] "" Vector__XXX

BO_ 1629 IBST_udsResponse: 8 Vector__XXX
   SG_ IBST_udsResponseData : 0|54@0+ (1024,0) [0|0] "" Vector__XXX

BO_ 917 OCS1P_alertMatrix: 8 Vector__XXX
   SG_ OCS1P_matrixIndex M : 0|4@1+ (1,0) [0|0] "" Vector__XXX
   SG_ OCS1P_w121_sandwichOpen m2 : 4|1@1+ (1,0) [0|0] "" Vector__XXX
   SG_ OCS1P_w122_sandwichLow m2 : 5|1@1+ (1,0) [0|0] "" Vector__XXX
   SG_ OCS1P_w123_sandwichShort m2 : 6|1@1+ (1,0) [0|0] "" Vector__XXX
   SG_ OCS1P_w124_cushionSelfOpen m2 : 7|1@1+ (1,0) [0|0] "" Vector__XXX
   SG_ OCS1P_w125_cushionSelfLow m2 : 8|1@1+ (1,0) [0|0] "" Vector__XXX
   SG_ OCS1P_w126_cushionSelfShort m2 : 9|1@1+ (1,0) [0|0] "" Vector__XXX
   SG_ OCS1P_w127_seatbackSelfOpen m2 : 10|1@1+ (1,0) [0|0] "" Vector__XXX
   SG_ OCS1P_w128_seatbackSelfLow m2 : 11|1@1+ (1,0) [0|0] "" Vector__XXX
   SG_ OCS1P_w129_seatbackSelfShort m2 : 12|1@1+ (1,0) [0|0] "" Vector__XXX
   SG_ OCS1P_w130_sandwichNoCalib m2 : 13|1@1+ (1,0) [0|0] "" Vector__XXX
   SG_ OCS1P_w131_cushionSelfNoCalib m2 : 14|1@1+ (1,0) [0|0] "" Vector__XXX
   SG_ OCS1P_w132_seatbackSelfNoCalib m2 : 15|1@1+ (1,0) [0|0] "" Vector__XXX
   SG_ OCS1P_w133_sandwichBadCalib m2 : 16|1@1+ (1,0) [0|0] "" Vector__XXX
   SG_ OCS1P_w134_uninitializedCalib m2 : 17|1@1+ (1,0) [0|0] "" Vector__XXX
   SG_ OCS1P_w135_tempNoCalib m2 : 18|1@1+ (1,0) [0|0] "" Vector__XXX
   SG_ OCS1P_w136_cushionSelfDutyLow m2 : 19|1@1+ (1,0) [0|0] "" Vector__XXX
   SG_ OCS1P_w137_cushionSelfDutyHigh m2 : 20|1@1+ (1,0) [0|0] "" Vector__XXX
   SG_ OCS1P_w138_seatbackSelfDutyLow m2 : 21|1@1+ (1,0) [0|0] "" Vector__XXX
   SG_ OCS1P_w139_seatbackSelfDutyHigh m2 : 22|1@1+ (1,0) [0|0] "" Vector__XXX
   SG_ OCS1P_w140_tempInvalidCalib m2 : 23|1@1+ (1,0) [0|0] "" Vector__XXX
   SG_ OCS1P_w141_humidityInvalidCalib m2 : 24|1@1+ (1,0) [0|0] "" Vector__XXX
   SG_ OCS1P_w142_tempHumidityInvalid m2 : 25|1@1+ (1,0) [0|0] "" Vector__XXX

BA_DEF_ BO_ "GenMsgSendType" ENUM "Cyclic";
BA_DEF_ BO_ "GenMsgCycleTime" INT 0 10000;
BA_DEF_ BO_ "GenMsgBackgroundColor" STRING ;
BA_DEF_ BO_ "GenMsgForegroundColor" STRING ;
BA_DEF_DEF_ "GenMsgBackgroundColor" "#ffffff";
BA_DEF_DEF_ "GenMsgForegroundColor" "#000000";
BA_ "GenMsgSendType" BO_ 858 0;
BA_ "GenMsgCycleTime" BO_ 858 1000;
BA_ "GenMsgSendType" BO_ 859 0;
BA_ "GenMsgCycleTime" BO_ 859 1000;
BA_ "GenMsgSendType" BO_ 694 0;
BA_ "GenMsgCycleTime" BO_ 694 100;
BA_ "GenMsgSendType" BO_ 1879 0;
BA_ "GenMsgCycleTime" BO_ 1879 100;
BA_ "GenMsgSendType" BO_ 1880 0;
BA_ "GenMsgCycleTime" BO_ 1880 10;
BA_ "GenMsgSendType" BO_ 1022 0;
BA_ "GenMsgCycleTime" BO_ 1022 1000;
BA_ "GenMsgSendType" BO_ 1622 0;
BA_ "GenMsgCycleTime" BO_ 1622 1000;
BA_ "GenMsgSendType" BO_ 646 0;
BA_ "GenMsgCycleTime" BO_ 646 100;
BA_ "GenMsgSendType" BO_ 822 0;
BA_ "GenMsgCycleTime" BO_ 822 1000;
BA_ "GenMsgSendType" BO_ 950 0;
BA_ "GenMsgCycleTime" BO_ 950 1000;
BA_ "GenMsgSendType" BO_ 918 0;
BA_ "GenMsgCycleTime" BO_ 918 100;
BA_ "GenMsgSendType" BO_ 614 0;
BA_ "GenMsgCycleTime" BO_ 614 10;
BA_ "GenMsgSendType" BO_ 599 0;
BA_ "GenMsgCycleTime" BO_ 599 20;
BA_ "GenMsgSendType" BO_ 616 0;
BA_ "GenMsgCycleTime" BO_ 616 100;
BA_ "GenMsgSendType" BO_ 280 0;
BA_ "GenMsgCycleTime" BO_ 280 10;
BA_ "GenMsgSendType" BO_ 886 0;
BA_ "GenMsgCycleTime" BO_ 886 1000;
BA_ "GenMsgSendType" BO_ 1367 0;
BA_ "GenMsgCycleTime" BO_ 1367 1000;
BA_ "GenMsgSendType" BO_ 264 0;
BA_ "GenMsgCycleTime" BO_ 264 10;
BA_ "GenMsgSendType" BO_ 914 0;
BA_ "GenMsgCycleTime" BO_ 914 1000;
BA_ "GenMsgSendType" BO_ 817 0;
BA_ "GenMsgCycleTime" BO_ 817 1000;
BA_ "GenMsgSendType" BO_ 883 0;
BA_ "GenMsgCycleTime" BO_ 883 10;
BA_ "GenMsgSendType" BO_ 913 0;
BA_ "GenMsgCycleTime" BO_ 913 1000;
BA_ "GenMsgSendType" BO_ 785 0;
BA_ "GenMsgCycleTime" BO_ 785 1000;
BA_ "GenMsgSendType" BO_ 882 0;
BA_ "GenMsgCycleTime" BO_ 882 10;
BA_ "GenMsgSendType" BO_ 968 0;
BA_ "GenMsgCycleTime" BO_ 968 100;
BA_ "GenMsgSendType" BO_ 1992 0;
BA_ "GenMsgCycleTime" BO_ 1992 1000;
BA_ "GenMsgSendType" BO_ 648 0;
BA_ "GenMsgCycleTime" BO_ 648 100;
BA_ "GenMsgSendType" BO_ 681 0;
BA_ "GenMsgCycleTime" BO_ 681 100;
BA_ "GenMsgSendType" BO_ 1000 0;
BA_ "GenMsgCycleTime" BO_ 1000 100;
BA_ "GenMsgSendType" BO_ 2024 0;
BA_ "GenMsgCycleTime" BO_ 2024 1000;
BA_ "GenMsgSendType" BO_ 552 0;
BA_ "GenMsgCycleTime" BO_ 552 100;
BA_ "GenMsgSendType" BO_ 744 0;
BA_ "GenMsgCycleTime" BO_ 744 100;
BA_ "GenMsgSendType" BO_ 981 0;
BA_ "GenMsgCycleTime" BO_ 981 1000;
BA_ "GenMsgSendType" BO_ 808 0;
BA_ "GenMsgCycleTime" BO_ 808 10000;
BA_ "GenMsgSendType" BO_ 325 0;
BA_ "GenMsgCycleTime" BO_ 325 20;
BA_ "GenMsgSendType" BO_ 1621 0;
BA_ "GenMsgCycleTime" BO_ 1621 100;
BA_ "GenMsgSendType" BO_ 805 0;
BA_ "GenMsgCycleTime" BO_ 805 1000;
BA_ "GenMsgSendType" BO_ 831 0;
BA_ "GenMsgCycleTime" BO_ 831 1000;
BA_ "GenMsgSendType" BO_ 895 0;
BA_ "GenMsgCycleTime" BO_ 895 1000;
BA_ "GenMsgSendType" BO_ 927 0;
BA_ "GenMsgCycleTime" BO_ 927 1000;
BA_ "GenMsgSendType" BO_ 958 0;
BA_ "GenMsgCycleTime" BO_ 958 1000;
BA_ "GenMsgSendType" BO_ 990 0;
BA_ "GenMsgCycleTime" BO_ 990 1000;
BA_ "GenMsgSendType" BO_ 1303 0;
BA_ "GenMsgCycleTime" BO_ 1303 1000;
BA_ "GenMsgSendType" BO_ 1310 0;
BA_ "GenMsgCycleTime" BO_ 1310 1000;
BA_ "GenMsgSendType" BO_ 580 0;
BA_ "GenMsgCycleTime" BO_ 580 100;
BA_ "GenMsgSendType" BO_ 1345 0;
BA_ "GenMsgCycleTime" BO_ 1345 100;
BA_ "GenMsgSendType" BO_ 532 0;
BA_ "GenMsgCycleTime" BO_ 532 100;
BA_ "GenMsgSendType" BO_ 533 0;
BA_ "GenMsgCycleTime" BO_ 533 1000;
BA_ "GenMsgSendType" BO_ 535 0;
BA_ "GenMsgCycleTime" BO_ 535 1000;
BA_ "GenMsgSendType" BO_ 888 0;
BA_ "GenMsgCycleTime" BO_ 888 1000;
BA_ "GenMsgSendType" BO_ 273 0;
BA_ "GenMsgCycleTime" BO_ 273 1000;
BA_ "GenMsgSendType" BO_ 274 0;
BA_ "GenMsgCycleTime" BO_ 274 1000;
BA_ "GenMsgSendType" BO_ 275 0;
BA_ "GenMsgCycleTime" BO_ 275 1000;
BA_ "GenMsgSendType" BO_ 276 0;
BA_ "GenMsgCycleTime" BO_ 276 1000;
BA_ "GenMsgSendType" BO_ 62 0;
BA_ "GenMsgCycleTime" BO_ 62 1000;
BA_ "GenMsgSendType" BO_ 281 0;
BA_ "GenMsgCycleTime" BO_ 281 2000;
BA_ "GenMsgSendType" BO_ 904 0;
BA_ "GenMsgCycleTime" BO_ 904 1000;
BA_ "GenMsgSendType" BO_ 2047 0;
BA_ "GenMsgCycleTime" BO_ 2047 100;
BA_ "GenMsgSendType" BO_ 1080 0;
BA_ "GenMsgCycleTime" BO_ 1080 100;
BA_ "GenMsgSendType" BO_ 1376 0;
BA_ "GenMsgCycleTime" BO_ 1376 1000;
BA_ "GenMsgSendType" BO_ 2033 0;
BA_ "GenMsgCycleTime" BO_ 2033 2000;
BA_ "GenMsgSendType" BO_ 60 0;
BA_ "GenMsgCycleTime" BO_ 60 2000;
BA_ "GenMsgSendType" BO_ 840 0;
BA_ "GenMsgCycleTime" BO_ 840 1000;
BA_ "GenMsgSendType" BO_ 872 0;
BA_ "GenMsgCycleTime" BO_ 872 1000;
BA_ "GenMsgSendType" BO_ 1112 0;
BA_ "GenMsgCycleTime" BO_ 1112 100;
BA_ "GenMsgSendType" BO_ 938 0;
BA_ "GenMsgCycleTime" BO_ 938 1000;
BA_ "GenMsgSendType" BO_ 522 0;
BA_ "GenMsgCycleTime" BO_ 522 10;
BA_ "GenMsgSendType" BO_ 1962 0;
BA_ "GenMsgCycleTime" BO_ 1962 1000;
BA_ "GenMsgSendType" BO_ 784 0;
BA_ "GenMsgCycleTime" BO_ 784 10000;
BA_ "GenMsgSendType" BO_ 1898 0;
BA_ "GenMsgCycleTime" BO_ 1898 300;
BA_ "GenMsgSendType" BO_ 861 0;
BA_ "GenMsgCycleTime" BO_ 861 1000;
BA_ "GenMsgSendType" BO_ 813 0;
BA_ "GenMsgCycleTime" BO_ 813 10000;
BA_ "GenMsgSendType" BO_ 925 0;
BA_ "GenMsgCycleTime" BO_ 925 40;
BA_ "GenMsgSendType" BO_ 917 0;
BA_ "GenMsgCycleTime" BO_ 917 100;
VAL_ 694 DI_btcStateUI 0 "OFF" 1 "ON";
VAL_ 694 DI_ptcStateUI 0 "FAULTED" 1 "BACKUP" 2 "ON" 3 "SNA";
VAL_ 694 DI_tcTelltaleFlash 0 "OFF" 1 "ON";
VAL_ 694 DI_tcTelltaleOn 0 "OFF" 1 "ON";
VAL_ 694 DI_tractionControlModeUI 0 "NORMAL" 1 "SLIP_START" 2 "DEV_MODE_1" 3 "DEV_MODE_2" 4 "ROLLS_MODE" 5 "DYNO_MODE";
VAL_ 694 DI_vdcTelltaleFlash 0 "OFF" 1 "ON";
VAL_ 694 DI_vdcTelltaleOn 0 "OFF" 1 "ON";
VAL_ 1879 DI_motorType 0 "SNA" 1 "ROADSTER_BASE" 2 "ROADSTER_SPORT" 3 "M7M3" 4 "M7M4" 5 "M7M5" 6 "M8A" 7 "M7M6" 8 "F1A" 9 "SSR1A" 10 "F1AC" 11 "F2AB" 12 "F2AC" 13 "F2AD" 14 "F2AE" 15 "F2APMSRM" 16 "PM216A" 17 "IM100A" 18 "PM216B" 19 "IM100B" 20 "IM216A" 21 "PM216C" 22 "IM130C" 23 "PM216D" 24 "IM130D" 25 "IM130D_AL";
VAL_ 1879 DI_ssmState 0 "START" 1 "UNAVAILABLE" 2 "IDLE" 3 "STANDBY" 4 "ENABLE" 5 "ABORT" 6 "WAIT_FOR_RETRY" 7 "RETRY" 8 "FAULT";
VAL_ 1879 DI_usmState 0 "START" 1 "STANDBY" 2 "RETRY" 3 "ABORT" 4 "ENABLE" 5 "FAULT" 6 "UNAVAILABLE" 7 "WAIT_FOR_RETRY";
VAL_ 1879 DI_tcMaxRequest 255 "SNA";
VAL_ 1879 DI_tcMinRequest 255 "SNA";
VAL_ 1879 DI_fluxState 0 "START" 1 "TEST" 2 "STANDBY" 3 "FLUX_UP" 4 "FLUX_DOWN" 5 "ENABLED" 6 "ICONTROL" 7 "VCONTROL" 9 "FAULT";
VAL_ 1879 DI_aebFaultReason 0 "NONE" 1 "EPB_MIA" 2 "PM_MIA" 3 "EBR_FAULT" 4 "SPEED_DELTA" 5 "DAS_CONTROL_MIA" 6 "DAS_SNA" 7 "VEL_EST_ABNORMAL" 8 "PM_REQUEST" 9 "ACCEL_OUT_OF_BOUNDS" 10 "EPB_NOT_PARKED" 11 "ESP_FAULT" 12 "ESP_MIA" 13 "MIN_TIME_BTWN_EVENTS" 14 "ACCEL_REQ_INVALID" 15 "DAS_REQ_DI_UNAVAIL";
VAL_ 1879 DI_aebUnavailableReason 0 "NONE" 1 "CLOSURE" 2 "GEAR" 3 "SKID" 4 "NEGATIVE_SPEED" 5 "DI_STATE" 6 "EBR_UNAVAILABLE" 7 "EPB" 8 "HYSTERESIS";
VAL_ 1879 DI_oilPumpPhaseCurrent 255 "SNA";
VAL_ 1879 DI_oilPumpPhaseVoltage 255 "SNA";
VAL_ 1879 DI_oilPumpPhaseAdvance 255 "SNA";
VAL_ 1879 DI_oilPumpPressureEstimate 255 "SNA";
VAL_ 1879 DI_magnetTempEst 0 "SNA";
VAL_ 1879 DI_magnetTempEst_SFO 0 "SNA";
VAL_ 1879 DI_gateDriveSupplyState 0 "DOWN" 1 "RISING" 2 "UP" 3 "FALLING";
VAL_ 1879 DI_gateDriveState 0 "INIT" 1 "SELFTEST" 2 "CONFIGURING" 3 "CONFIGURED" 4 "NOT_CONFIGURED";
VAL_ 1879 DI_powerStageSafeState 0 "NONE" 1 "ALL_OFF" 2 "3PS_HIGH" 3 "3PS_LOW";
VAL_ 1879 DI_brkStState 0 "UNAVAILABLE" 1 "IDLE" 2 "RUNNING_UNPRESSED" 3 "RUNNING_PRESSING" 4 "RUNNING_PRESSED" 5 "INTERRUPTED" 6 "FINISHED";
VAL_ 1879 DI_immobilizerCondition 0 "VIRGIN_SNA" 1 "LEARNED";
VAL_ 1879 DI_velocityEstimatorState 0 "NOT_INITIALIZED" 1 "WHEELS_NORMAL" 2 "BACKUP_WHEELS_A" 3 "BACKUP_WHEELS_B" 4 "BACKUP_MOTOR";
VAL_ 1880 DI_dynoSelector 0 "Mux0" 1 "Mux1" 2 "Mux2" 32 "Mux32" 33 "Mux33" 64 "Mux64";
VAL_ 1880 DI_state 0 "UNAVAILABLE" 1 "STANDBY" 2 "FAULT" 3 "ABORT" 4 "ENABLE";
VAL_ 1022 DI_brakeFLTemp 1023 "SNA";
VAL_ 1022 DI_brakeFRTemp 1023 "SNA";
VAL_ 1022 DI_brakeRLTemp 1023 "SNA";
VAL_ 1022 DI_brakeRRTemp 1023 "SNA";
VAL_ 1622 DI_infoIndex 0 "DEPRECATED_0" 1 "DEPRECATED_1" 2 "DEPRECATED_2" 3 "DEPRECATED_3" 4 "DEPRECATED_4" 5 "DEPRECATED_5" 6 "DEPRECATED_6" 7 "DEPRECATED_7" 8 "DEPRECATED_8" 9 "DEPRECATED_9" 10 "BUILD_HWID_COMPONENTID" 11 "PCBAID_ASSYID_USAGEID" 13 "APP_CRC" 14 "BOOTLOADER_SVN" 15 "BOOTLOADER_CRC" 16 "SUBCOMPONENT" 17 "APP_GITHASH" 18 "BOOTLOADER_GITHASH" 19 "VERSION_DEPRECATED" 20 "UDS_PROTOCOL_BOOTCRC" 22 "VARIANTCRC" 25 "PACKAGE_PN_1_7" 26 "PACKAGE_PN_8_14" 27 "PACKAGE_PN_15_20" 29 "PACKAGE_SN_1_7" 30 "PACKAGE_SN_8_14" 31 "SUBCOMPONENT_GITHASH" 255 "END";
VAL_ 1622 DI_buildType 0 "UNKNOWN_BUILD" 1 "PLATFORM_BUILD" 2 "LOCAL_BUILD" 3 "TRACEABLE_CI_BUILD" 4 "MFG_BUILD";
VAL_ 1622 DI_hardwareId 252 "CONFIGURABLE_HWID_PLACEHOLDER";
VAL_ 1622 DI_oilPumpBuildType 0 "UNKNOWN_BUILD" 1 "PLATFORM_BUILD" 2 "LOCAL_BUILD" 3 "TRACEABLE_CI_BUILD" 4 "MFG_BUILD";
VAL_ 646 DI_aebState 0 "UNAVAILABLE" 1 "STANDBY" 2 "ENABLED" 3 "STANDSTILL" 4 "FAULT" 7 "SNA";
VAL_ 646 DI_autoparkState 0 "UNAVAILABLE" 1 "STANDBY" 2 "STARTED" 3 "ACTIVE" 4 "COMPLETE" 5 "PAUSED" 6 "ABORTED" 7 "RESUMED" 8 "UNPARK_COMPLETE" 9 "SELFPARK_STARTED" 15 "SNA";
VAL_ 646 DI_autopilotRequest 0 "IDLE" 1 "ACTIVATE";
VAL_ 646 DI_cruiseSetSpeedUnits 0 "MPH" 1 "KPH";
VAL_ 646 DI_cruiseState 0 "UNAVAILABLE" 1 "STANDBY" 2 "ENABLED" 3 "STANDSTILL" 4 "OVERRIDE" 5 "FAULT" 6 "PRE_FAULT" 7 "PRE_CANCEL";
VAL_ 646 DI_parkBrakeState 0 "UNAVAILABLE" 1 "RELEASED" 2 "REQUESTED" 3 "APPLIED" 4 "FAULTED" 5 "PANIC_EPB" 6 "PANIC_SKID" 7 "RELEASING" 15 "SNA";
VAL_ 646 DI_pmmStatus 0 "INACTIVE" 1 "ACTIVE" 2 "LOGGING_ACTIVE" 3 "SNA";
VAL_ 646 DI_rollPreventionState 0 "UNAVAILABLE" 1 "STANDBY" 2 "READY" 3 "BUILD" 4 "HOLD" 5 "PARK" 6 "FAULT" 7 "INIT";
VAL_ 646 DI_vehicleHoldState 0 "UNAVAILABLE" 1 "STANDBY" 2 "BLEND_IN" 3 "STANDSTILL" 4 "BLEND_OUT" 5 "PARK" 6 "FAULT" 7 "INIT";
VAL_ 822 DI_sysDrivePowerRated 511 "SNA";
VAL_ 822 DI_sysRegenPowerRated 255 "SNA";
VAL_ 950 DI_odometer 536870911 "SNA";
VAL_ 918 DI_oilPumpCurrent 255 "SNA";
VAL_ 918 DI_oilPumpCurrentSensorOffset 255 "SNA";
VAL_ 918 DI_oilPumpFlowActual 255 "SNA";
VAL_ 918 DI_oilPumpFlowTarget 255 "SNA";
VAL_ 918 DI_oilPumpFluidT 255 "SNA";
VAL_ 918 DI_oilPumpPcbT 255 "SNA";
VAL_ 918 DI_oilPumpState 0 "STANDBY" 1 "ENABLE" 2 "COLD_STARTUP" 6 "FAULTED" 7 "SNA";
VAL_ 918 DI_oilPumpVoltage 255 "SNA";
VAL_ 614 DI_elecPower 1024 "DI_elecPower_SNA";
VAL_ 599 DI_uiSpeed 255 "DI_UI_SPEED_SNA";
VAL_ 599 DI_uiSpeedUnits 0 "MPH" 1 "KPH";
VAL_ 599 DI_vehicleSpeed 4095 "SNA";
VAL_ 616 DI_sysDrivePowerMax 511 "SNA";
VAL_ 616 DI_sysRegenPowerMax 255 "SNA";
VAL_ 280 DI_accelPedalPos 255 "SNA";
VAL_ 280 DI_brakePedalState 0 "OFF" 1 "ON" 2 "INVALID";
VAL_ 280 DI_epbRequest 0 "NO_REQUEST" 1 "PARK" 2 "UNPARK";
VAL_ 280 DI_gear 0 "INVALID" 1 "P" 2 "R" 3 "N" 4 "D" 7 "SNA";
VAL_ 280 DI_immobilizerState 0 "INIT_SNA" 1 "REQUEST" 2 "AUTHENTICATING" 3 "DISARMED" 4 "IDLE" 5 "RESET" 6 "FAULT";
VAL_ 280 DI_keepAliveRequest 0 "NO_REQUEST" 1 "KEEP_ALIVE";
VAL_ 280 DI_systemState 0 "UNAVAILABLE" 1 "IDLE" 2 "STANDBY" 3 "FAULT" 4 "ABORT" 5 "ENABLE";
VAL_ 280 DI_trackModeState 0 "UNAVAILABLE" 1 "AVAILABLE" 2 "ON";
VAL_ 280 DI_tractionControlMode 0 "NORMAL" 1 "SLIP_START" 2 "DEV_MODE_1" 3 "DEV_MODE_2" 4 "ROLLS_MODE" 5 "DYNO_MODE";
VAL_ 886 DI_inverterTQF 0 "INIT" 1 "IRRATIONAL" 2 "RATIONAL" 3 "UNKNOWN";
VAL_ 264 DI_axleSpeed 32768 "SNA";
VAL_ 264 DI_torqueActual 4096 "SNA";
VAL_ 264 DI_torqueCommand 4096 "SNA";
VAL_ 914 EPAS3P_matrixIndex 0 "AlertMatrix0" 1 "AlertMatrix1" 2 "AlertMatrix2";
VAL_ 817 EPAS3P_infoIndex 0 "DEPRECATED_0" 1 "DEPRECATED_1" 2 "DEPRECATED_2" 3 "DEPRECATED_3" 4 "DEPRECATED_4" 5 "DEPRECATED_5" 6 "DEPRECATED_6" 7 "DEPRECATED_7" 8 "DEPRECATED_8" 9 "DEPRECATED_9" 10 "BUILD_HWID_COMPONENTID" 11 "PCBAID_ASSYID_USAGEID" 13 "APP_CRC" 14 "BOOTLOADER_SVN" 15 "BOOTLOADER_CRC" 16 "SUBCOMPONENT" 17 "APP_GITHASH" 18 "BOOTLOADER_GITHASH" 19 "VERSION_DEPRECATED" 20 "UDS_PROTOCOL_BOOTCRC" 22 "VARIANTCRC" 25 "PACKAGE_PN_1_7" 26 "PACKAGE_PN_8_14" 27 "PACKAGE_PN_15_20" 29 "PACKAGE_SN_1_7" 30 "PACKAGE_SN_8_14" 31 "SUBCOMPONENT_GITHASH" 255 "END";
VAL_ 817 EPAS3P_infoBuildType 0 "UNKNOWN_BUILD" 1 "PLATFORM_BUILD" 2 "LOCAL_BUILD" 3 "TRACEABLE_CI_BUILD" 4 "MFG_BUILD";
VAL_ 883 EPAS3P_currentTuneMode 0 "DM_COMFORT" 1 "DM_STANDARD" 2 "DM_SPORT" 3 "RWD_COMFORT" 4 "RWD_STANDARD" 5 "RWD_SPORT";
VAL_ 883 EPAS3P_eacErrorCode 0 "EAC_ERROR_IDLE" 1 "EAC_ERROR_MIN_SPEED" 2 "EAC_ERROR_MAX_SPEED" 3 "EAC_ERROR_HANDS_ON" 4 "EAC_ERROR_TMP_FAULT" 5 "EAR_ERROR_MAX_STEER_DELTA" 6 "EAC_ERROR_HIGH_ANGLE_REQ" 7 "EAC_ERROR_HIGH_ANGLE_RATE_REQ" 8 "EAC_ERROR_HIGH_ANGLE_SAFETY" 9 "EAC_ERROR_HIGH_ANGLE_RATE_SAFETY" 10 "EAC_ERROR_HIGH_MMOT_SAFETY" 11 "EAC_ERROR_HIGH_TORSION_SAFETY" 12 "EAC_ERROR_LOW_ASSIST" 13 "EAC_ERROR_PINION_VEL_DIFF" 14 "EAC_EXTERNAL_MONITOR_INHIBIT" 15 "SNA";
VAL_ 883 EPAS3P_eacStatus 0 "EAC_INHIBITED" 1 "EAC_AVAILABLE" 2 "EAC_ACTIVE" 3 "EAC_FAULT" 4 "LANE_KEEP_ASSIST" 5 "EMERGENCY_LANE_KEEP" 7 "SNA";
VAL_ 883 EPAS3P_handsOnLevel 0 "0" 1 "1" 2 "2" 3 "3";
VAL_ 883 EPAS3P_internalSASQF 0 "UNDEFINABLE_ACCURACY" 1 "IN_SPEC";
VAL_ 883 EPAS3P_steeringFault 0 "NO_FAULT" 1 "FAULT";
VAL_ 883 EPAS3P_steeringRackForce 1022 "NOT_IN_SPEC" 1023 "SNA";
VAL_ 883 EPAS3P_steeringReduced 0 "NORMAL_ASSIST" 1 "REDUCED_ASSIST";
VAL_ 883 EPAS3P_torsionBarTorque 4094 "UNDEFINABLE_DATA" 4095 "SNA";
VAL_ 913 EPAS3S_matrixIndex 0 "AlertMatrix0" 1 "AlertMatrix1" 2 "AlertMatrix2";
VAL_ 785 EPAS3S_infoIndex 0 "DEPRECATED_0" 1 "DEPRECATED_1" 2 "DEPRECATED_2" 3 "DEPRECATED_3" 4 "DEPRECATED_4" 5 "DEPRECATED_5" 6 "DEPRECATED_6" 7 "DEPRECATED_7" 8 "DEPRECATED_8" 9 "DEPRECATED_9" 10 "BUILD_HWID_COMPONENTID" 11 "PCBAID_ASSYID_USAGEID" 13 "APP_CRC" 14 "BOOTLOADER_SVN" 15 "BOOTLOADER_CRC" 16 "SUBCOMPONENT" 17 "APP_GITHASH" 18 "BOOTLOADER_GITHASH" 19 "VERSION_DEPRECATED" 20 "UDS_PROTOCOL_BOOTCRC" 22 "VARIANTCRC" 25 "PACKAGE_PN_1_7" 26 "PACKAGE_PN_8_14" 27 "PACKAGE_PN_15_20" 29 "PACKAGE_SN_1_7" 30 "PACKAGE_SN_8_14" 31 "SUBCOMPONENT_GITHASH" 255 "END";
VAL_ 785 EPAS3S_infoBuildType 0 "UNKNOWN_BUILD" 1 "PLATFORM_BUILD" 2 "LOCAL_BUILD" 3 "TRACEABLE_CI_BUILD" 4 "MFG_BUILD";
VAL_ 882 EPAS3S_currentTuneMode 0 "DM_COMFORT" 1 "DM_STANDARD" 2 "DM_SPORT" 3 "RWD_COMFORT" 4 "RWD_STANDARD" 5 "RWD_SPORT";
VAL_ 882 EPAS3S_eacErrorCode 0 "EAC_ERROR_IDLE" 1 "EAC_ERROR_MIN_SPEED" 2 "EAC_ERROR_MAX_SPEED" 3 "EAC_ERROR_HANDS_ON" 4 "EAC_ERROR_TMP_FAULT" 5 "EAR_ERROR_MAX_STEER_DELTA" 6 "EAC_ERROR_HIGH_ANGLE_REQ" 7 "EAC_ERROR_HIGH_ANGLE_RATE_REQ" 8 "EAC_ERROR_HIGH_ANGLE_SAFETY" 9 "EAC_ERROR_HIGH_ANGLE_RATE_SAFETY" 10 "EAC_ERROR_HIGH_MMOT_SAFETY" 11 "EAC_ERROR_HIGH_TORSION_SAFETY" 12 "EAC_ERROR_LOW_ASSIST" 13 "EAC_ERROR_PINION_VEL_DIFF" 14 "EAC_EXTERNAL_MONITOR_INHIBIT" 15 "SNA";
VAL_ 882 EPAS3S_eacStatus 0 "EAC_INHIBITED" 1 "EAC_AVAILABLE" 2 "EAC_ACTIVE" 3 "EAC_FAULT" 4 "LANE_KEEP_ASSIST" 5 "EMERGENCY_LANE_KEEP" 7 "SNA";
VAL_ 882 EPAS3S_handsOnLevel 0 "0" 1 "1" 2 "2" 3 "3";
VAL_ 882 EPAS3S_internalSASQF 0 "UNDEFINABLE_ACCURACY" 1 "IN_SPEC";
VAL_ 882 EPAS3S_steeringFault 0 "NO_FAULT" 1 "FAULT";
VAL_ 882 EPAS3S_steeringRackForce 1022 "NOT_IN_SPEC" 1023 "SNA";
VAL_ 882 EPAS3S_steeringReduced 0 "NORMAL_ASSIST" 1 "REDUCED_ASSIST";
VAL_ 882 EPAS3S_torsionBarTorque 4094 "UNDEFINABLE_DATA" 4095 "SNA";
VAL_ 968 EPBL_matrixIndex 0 "AlertMatrix0" 1 "AlertMatrix1" 2 "AlertMatrix2" 3 "AlertMatrix3" 4 "AlertMatrix4";
VAL_ 1992 EPBL_infoIndex 0 "DEPRECATED_0" 1 "DEPRECATED_1" 2 "DEPRECATED_2" 3 "DEPRECATED_3" 4 "DEPRECATED_4" 5 "DEPRECATED_5" 6 "DEPRECATED_6" 7 "DEPRECATED_7" 8 "DEPRECATED_8" 9 "DEPRECATED_9" 10 "BUILD_HWID_COMPONENTID" 11 "PCBAID_ASSYID_USAGEID" 13 "APP_CRC" 14 "BOOTLOADER_SVN" 15 "BOOTLOADER_CRC" 16 "SUBCOMPONENT1" 17 "APP_GITHASH" 18 "BOOTLOADER_GITHASH" 19 "VERSION_DEPRECATED" 20 "UDS_PROTOCOL_BOOTCRC" 23 "SUBCOMPONENT2" 24 "SUBCOMPONENT3" 31 "SUBCOMPONENT4" 255 "END";
VAL_ 1992 EPBL_infoBuildType 0 "UNKNOWN_BUILD" 1 "PLATFORM_BUILD" 2 "LOCAL_BUILD" 3 "TRACEABLE_CI_BUILD" 4 "MFG_BUILD";
VAL_ 1992 EPBL_infoAssemblyId 1 "ASSEMBLY1" 255 "ASSEMBLY_SNA";
VAL_ 648 EPBL_csmFaultReason 0 "NONE" 1 "EPBM_DISABLED" 2 "EPBM_FAULTED" 3 "STATE_MISMATCH" 4 "TIMEOUT_CALIBRATE" 5 "APPLY_BLOCKED" 6 "RELEASE_BLOCKED" 7 "TIMEOUT_APPLY_COMPLETE" 8 "TIMEOUT_APPLY_INRUSH" 9 "TIMEOUT_WAIT_FOR_CLAMP" 10 "TIMEOUT_RELEASE_INRUSH" 11 "TIMEOUT_RELEASE_WAIT_FOR_ENDSTOP" 12 "TIMEOUT_RELEASE_COMPLETE" 13 "TIMEOUT_EPBM_CUTOFF" 14 "TIMEOUT_NO_RAMP" 15 "TIMEOUT_EPBM_START" 16 "MOTOR_IDLE_FAULT" 17 "MOTOR_ACTIVE_FAULT" 18 "MOTOR_NOT_READY" 19 "EPBM_MIA" 20 "NVM_MISMATCH" 21 "REMOTE_MIA";
VAL_ 648 EPBL_epbmCDPQualified 0 "IDLE" 1 "VALID" 2 "INVALID";
VAL_ 648 EPBL_esmCaliperRequest 0 "INVALID" 1 "NONE" 2 "APPLY" 3 "RELEASE" 4 "ENDSTOP";
VAL_ 648 EPBL_esmOperationTrigger 0 "PBUTTON_PRESSED_STOPPED" 1 "PBUTTON_PRESSED_OKTOPARK" 2 "PBUTTON_PRESSED_FAST" 3 "PBUTTON_PRESSED_UNKNOWN" 4 "PBUTTON_RELEASED" 5 "ACTIVE_PARK_REQUEST" 6 "DI_UNPARK" 7 "TOUCHSCREEN" 8 "WINCHMODE_EXIT" 9 "WINCHMODE_ENTER" 10 "WINCHMODE_UNAVAILABLE" 11 "SERVICE" 12 "DIAG_CLOSE" 13 "DIAG_OPEN" 14 "DIAG_EXIT" 15 "USER_CONFIRMED" 16 "USER_CANCEL" 17 "SPEED_STOPPED" 18 "SPEED_OKAYTOPARK" 19 "SPEED_FAST" 20 "TIMEOUT" 21 "SAVESTATE_ON_BOOT" 22 "REAPPLY" 23 "SUMMON_COMPLETE" 24 "FAULT" 25 "SUMMON_FAULT" 26 "DISQUALIFIED" 27 "EPBM_DISQUALIFIED" 28 "ACCELERATION" 29 "SYSTEM_APPLY" 30 "DRIVER_IS_LEAVING";
VAL_ 648 EPBL_internalCDPRequest 0 "NOT_REQUESTED" 1 "REQUESTED";
VAL_ 648 EPBL_summonFaultReason 0 "NONE" 1 "DI_MIA" 2 "DAS_MIA" 3 "ESP_MIA" 4 "EPBM_MIA" 5 "DI_FAULT" 6 "DI_APC_FAULT" 7 "DAS_FAULT" 8 "ESP_FAULT" 9 "VEH_CAN_FAULT" 10 "EAC_NOT_ALLOWED" 11 "EPBM_REQUEST" 12 "SPEED" 13 "EXTERNAL" 14 "PARK_MIA" 15 "PM_MIA" 16 "PM_REQUEST" 17 "OOC" 18 "MISMATCH" 19 "EPB_FAULT" 20 "DI_STATE_INVALID" 21 "PASSIVE_REQUEST" 22 "EPBREMOTE_MIA" 23 "REMOTE_SUMMON_FAULTED" 24 "LOCAL_UNIT_FAULTED" 25 "REMOTE_UNIT_FAULTED" 26 "START_IN_UNAVAILABLE" 27 "INVALID_REMOTE_STATE" 28 "REMOTE_DID_NOT_START";
VAL_ 648 EPBL_summonState 0 "INIT" 1 "IDLE" 2 "ARMED" 3 "ACTIVE" 4 "COMPLETE" 5 "FAULT" 6 "UNAVAILABLE";
VAL_ 648 EPBL_unitFaultStatus 0 "NOMINAL" 1 "RETRY" 2 "FAULT" 3 "FAULT_IDLE";
VAL_ 648 EPBL_unitStatus 0 "UNKNOWN" 1 "OPEN" 2 "DYNAMIC" 3 "PARK" 4 "START" 5 "SERVICE" 6 "WINCHMODE" 7 "WINCHMODE_RELEASING" 8 "PARKING" 9 "DYNAMIC_APPLYING" 10 "RELEASING" 11 "SERVICE_RELEASING" 12 "PARK_PENDING" 13 "WINCHMODE_PENDING" 14 "SUMMON" 15 "SUMMON_RELEASING" 16 "SUMMON_PARKING" 17 "EXTERNAL_DYNAMIC" 18 "RELEASING_FOR_EXTERNAL_PARK" 19 "EXTERNAL_PARKING" 20 "DYNAMIC_PARKING" 21 "COUNT";
VAL_ 681 EPBL_brakeDiscWipeRequest 0 "NONE" 1 "LIGHT" 2 "STRONG" 3 "SNA";
VAL_ 681 EPBL_cdpRequest 0 "NOT_REQUESTED" 1 "REQUESTED";
VAL_ 681 EPBL_systemStatus 0 "UNKNOWN" 1 "RELEASED" 2 "PARKED" 3 "DYNAMIC" 4 "PARKING" 5 "RELEASING" 6 "FAULT" 7 "FAULT_SECURE" 8 "MISMATCH";
VAL_ 1000 EPBR_matrixIndex 0 "AlertMatrix0" 1 "AlertMatrix1" 2 "AlertMatrix2" 3 "AlertMatrix3" 4 "AlertMatrix4";
VAL_ 2024 EPBR_infoIndex 0 "DEPRECATED_0" 1 "DEPRECATED_1" 2 "DEPRECATED_2" 3 "DEPRECATED_3" 4 "DEPRECATED_4" 5 "DEPRECATED_5" 6 "DEPRECATED_6" 7 "DEPRECATED_7" 8 "DEPRECATED_8" 9 "DEPRECATED_9" 10 "BUILD_HWID_COMPONENTID" 11 "PCBAID_ASSYID_USAGEID" 13 "APP_CRC" 14 "BOOTLOADER_SVN" 15 "BOOTLOADER_CRC" 16 "SUBCOMPONENT1" 17 "APP_GITHASH" 18 "BOOTLOADER_GITHASH" 19 "VERSION_DEPRECATED" 20 "UDS_PROTOCOL_BOOTCRC" 23 "SUBCOMPONENT2" 24 "SUBCOMPONENT3" 31 "SUBCOMPONENT4" 255 "END";
VAL_ 2024 EPBR_infoBuildType 0 "UNKNOWN_BUILD" 1 "PLATFORM_BUILD" 2 "LOCAL_BUILD" 3 "TRACEABLE_CI_BUILD" 4 "MFG_BUILD";
VAL_ 2024 EPBR_infoAssemblyId 1 "ASSEMBLY1" 255 "ASSEMBLY_SNA";
VAL_ 552 EPBR_csmFaultReason 0 "NONE" 1 "EPBM_DISABLED" 2 "EPBM_FAULTED" 3 "STATE_MISMATCH" 4 "TIMEOUT_CALIBRATE" 5 "APPLY_BLOCKED" 6 "RELEASE_BLOCKED" 7 "TIMEOUT_APPLY_COMPLETE" 8 "TIMEOUT_APPLY_INRUSH" 9 "TIMEOUT_WAIT_FOR_CLAMP" 10 "TIMEOUT_RELEASE_INRUSH" 11 "TIMEOUT_RELEASE_WAIT_FOR_ENDSTOP" 12 "TIMEOUT_RELEASE_COMPLETE" 13 "TIMEOUT_EPBM_CUTOFF" 14 "TIMEOUT_NO_RAMP" 15 "TIMEOUT_EPBM_START" 16 "MOTOR_IDLE_FAULT" 17 "MOTOR_ACTIVE_FAULT" 18 "MOTOR_NOT_READY" 19 "EPBM_MIA" 20 "NVM_MISMATCH" 21 "REMOTE_MIA";
VAL_ 552 EPBR_epbmCDPQualified 0 "IDLE" 1 "VALID" 2 "INVALID";
VAL_ 552 EPBR_esmCaliperRequest 0 "INVALID" 1 "NONE" 2 "APPLY" 3 "RELEASE" 4 "ENDSTOP";
VAL_ 552 EPBR_esmOperationTrigger 0 "PBUTTON_PRESSED_STOPPED" 1 "PBUTTON_PRESSED_OKTOPARK" 2 "PBUTTON_PRESSED_FAST" 3 "PBUTTON_PRESSED_UNKNOWN" 4 "PBUTTON_RELEASED" 5 "ACTIVE_PARK_REQUEST" 6 "DI_UNPARK" 7 "TOUCHSCREEN" 8 "WINCHMODE_EXIT" 9 "WINCHMODE_ENTER" 10 "WINCHMODE_UNAVAILABLE" 11 "SERVICE" 12 "DIAG_CLOSE" 13 "DIAG_OPEN" 14 "DIAG_EXIT" 15 "USER_CONFIRMED" 16 "USER_CANCEL" 17 "SPEED_STOPPED" 18 "SPEED_OKAYTOPARK" 19 "SPEED_FAST" 20 "TIMEOUT" 21 "SAVESTATE_ON_BOOT" 22 "REAPPLY" 23 "SUMMON_COMPLETE" 24 "FAULT" 25 "SUMMON_FAULT" 26 "DISQUALIFIED" 27 "EPBM_DISQUALIFIED" 28 "ACCELERATION" 29 "SYSTEM_APPLY" 30 "DRIVER_IS_LEAVING";
VAL_ 552 EPBR_internalCDPRequest 0 "NOT_REQUESTED" 1 "REQUESTED";
VAL_ 552 EPBR_summonFaultReason 0 "NONE" 1 "DI_MIA" 2 "DAS_MIA" 3 "ESP_MIA" 4 "EPBM_MIA" 5 "DI_FAULT" 6 "DI_APC_FAULT" 7 "DAS_FAULT" 8 "ESP_FAULT" 9 "VEH_CAN_FAULT" 10 "EAC_NOT_ALLOWED" 11 "EPBM_REQUEST" 12 "SPEED" 13 "EXTERNAL" 14 "PARK_MIA" 15 "PM_MIA" 16 "PM_REQUEST" 17 "OOC" 18 "MISMATCH" 19 "EPB_FAULT" 20 "DI_STATE_INVALID" 21 "PASSIVE_REQUEST" 22 "EPBREMOTE_MIA" 23 "REMOTE_SUMMON_FAULTED" 24 "LOCAL_UNIT_FAULTED" 25 "REMOTE_UNIT_FAULTED" 26 "START_IN_UNAVAILABLE" 27 "INVALID_REMOTE_STATE" 28 "REMOTE_DID_NOT_START";
VAL_ 552 EPBR_summonState 0 "INIT" 1 "IDLE" 2 "ARMED" 3 "ACTIVE" 4 "COMPLETE" 5 "FAULT" 6 "UNAVAILABLE";
VAL_ 552 EPBR_unitFaultStatus 0 "NOMINAL" 1 "RETRY" 2 "FAULT" 3 "FAULT_IDLE";
VAL_ 552 EPBR_unitStatus 0 "UNKNOWN" 1 "OPEN" 2 "DYNAMIC" 3 "PARK" 4 "START" 5 "SERVICE" 6 "WINCHMODE" 7 "WINCHMODE_RELEASING" 8 "PARKING" 9 "DYNAMIC_APPLYING" 10 "RELEASING" 11 "SERVICE_RELEASING" 12 "PARK_PENDING" 13 "WINCHMODE_PENDING" 14 "SUMMON" 15 "SUMMON_RELEASING" 16 "SUMMON_PARKING" 17 "EXTERNAL_DYNAMIC" 18 "RELEASING_FOR_EXTERNAL_PARK" 19 "EXTERNAL_PARKING" 20 "DYNAMIC_PARKING" 21 "COUNT";
VAL_ 744 EPBR_brakeDiscWipeRequest 0 "NONE" 1 "LIGHT" 2 "STRONG" 3 "SNA";
VAL_ 744 EPBR_cdpRequest 0 "NOT_REQUESTED" 1 "REQUESTED";
VAL_ 744 EPBR_systemStatus 0 "UNKNOWN" 1 "RELEASED" 2 "PARKED" 3 "DYNAMIC" 4 "PARKING" 5 "RELEASING" 6 "FAULT" 7 "FAULT_SECURE" 8 "MISMATCH";
VAL_ 981 ESP_matrixIndex 0 "AlertMatrix0" 1 "AlertMatrix1" 2 "AlertMatrix2" 3 "AlertMatrix3" 4 "AlertMatrix4";
VAL_ 808 ESP_infoIndex 0 "DEPRECATED_0" 1 "DEPRECATED_1" 2 "DEPRECATED_2" 3 "DEPRECATED_3" 4 "DEPRECATED_4" 5 "DEPRECATED_5" 6 "DEPRECATED_6" 7 "DEPRECATED_7" 8 "DEPRECATED_8" 9 "DEPRECATED_9" 10 "BUILD_HWID_COMPONENTID" 11 "PCBAID_ASSYID_USAGEID" 13 "APP_CRC" 14 "BOOTLOADER_SVN" 15 "BOOTLOADER_CRC" 16 "SUBCOMPONENT" 17 "APP_GITHASH" 18 "BOOTLOADER_GITHASH" 19 "VERSION_DEPRECATED" 20 "UDS_PROTOCOL_BOOTCRC" 22 "VARIANTCRC" 25 "PACKAGE_PN_1_7" 26 "PACKAGE_PN_8_14" 27 "PACKAGE_PN_15_20" 29 "PACKAGE_SN_1_7" 30 "PACKAGE_SN_8_14" 31 "SUBCOMPONENT_GITHASH" 255 "END";
VAL_ 808 ESP_infoBuildType 0 "UNKNOWN_BUILD" 1 "PLATFORM_BUILD" 2 "LOCAL_BUILD" 3 "TRACEABLE_CI_BUILD" 4 "MFG_BUILD";
VAL_ 808 ESP_infoVehicleVariant 1 "01" 2 "02" 3 "03" 4 "04" 5 "05" 6 "06" 7 "07" 8 "08" 9 "09";
VAL_ 325 ESP_absBrakeEvent2 0 "NOT_ACTIVE" 1 "ACTIVE_FRONT_REAR" 2 "ACTIVE_FRONT" 3 "ACTIVE_REAR";
VAL_ 325 ESP_absFaultLamp 0 "OFF" 1 "ON";
VAL_ 325 ESP_brakeApply 0 "INACTIVE" 1 "ACTIVE";
VAL_ 325 ESP_brakeDiscWipingActive 0 "INACTIVE" 1 "ACTIVE";
VAL_ 325 ESP_brakeLamp 0 "OFF" 1 "ON";
VAL_ 325 ESP_brakeTorqueTarget 8191 "SNA";
VAL_ 325 ESP_btcTargetState 0 "OFF" 1 "BACKUP" 2 "ON" 3 "SNA";
VAL_ 325 ESP_cdpStatus 0 "CDP_IS_NOT_AVAILABLE" 1 "CDP_IS_AVAILABLE" 2 "ACTUATING_EPB_CDP" 3 "CDP_COMMAND_INVALID";
VAL_ 325 ESP_driverBrakeApply 0 "NotInit_orOff" 1 "Not_Applied" 2 "Driver_applying_brakes" 3 "Faulty_SNA";
VAL_ 325 ESP_ebdFaultLamp 0 "OFF" 1 "ON";
VAL_ 325 ESP_ebrStandstillSkid 0 "NO_STANDSTILL_SKID" 1 "STANDSTILL_SKID_DETECTED";
VAL_ 325 ESP_ebrStatus 0 "EBR_IS_NOT_AVAILABLE" 1 "EBR_IS_AVAILABLE" 2 "ACTUATING_DI_EBR" 3 "EBR_COMMAND_INVALID";
VAL_ 325 ESP_espFaultLamp 0 "OFF" 1 "ON";
VAL_ 325 ESP_espLampFlash 0 "OFF" 1 "FLASH";
VAL_ 325 ESP_espModeActive 0 "00_NORMAL" 1 "01" 2 "02" 3 "03";
VAL_ 325 ESP_lateralAccelQF 0 "UNDEFINABLE_ACCURACY" 1 "IN_SPEC";
VAL_ 325 ESP_longitudinalAccelQF 0 "UNDEFINABLE_ACCURACY" 1 "IN_SPEC";
VAL_ 325 ESP_ptcTargetState 0 "FAULT" 1 "BACKUP" 2 "ON" 3 "SNA";
VAL_ 325 ESP_stabilityControlSts2 0 "INIT" 1 "ON" 2 "ENGAGED" 3 "FAULTED";
VAL_ 325 ESP_steeringAngleQF 0 "UNDEFINABLE_ACCURACY" 1 "IN_SPEC";
VAL_ 325 ESP_yawRateQF 0 "UNDEFINABLE_ACCURACY" 1 "IN_SPEC";
VAL_ 1310 FC_infoIndex 0 "DEPRECATED_0_FC" 1 "DEPRECATED_1_FC" 2 "DEPRECATED_2_FC" 3 "DEPRECATED_3_FC" 4 "DEPRECATED_4_FC" 5 "DEPRECATED_5_FC" 6 "DEPRECATED_6_FC" 7 "DEPRECATED_7_FC" 8 "DEPRECATED_8_FC" 9 "DEPRECATED_9_FC" 10 "BUILD_HWID_COMPONENTID_FC" 11 "PCBAID_ASSYID_USAGEID_FC" 13 "APP_CRC_FC" 14 "BOOTLOADER_SVN_FC" 15 "BOOTLOADER_CRC_FC" 16 "SUBCOMPONENT_FC" 17 "APP_GITHASH_FC" 18 "BOOTLOADER_GITHASH_FC" 19 "VERSION_DEPRECATED_FC" 20 "UDS_PROTOCOL_BOOTCRC_FC" 22 "VARIANT_CRC_FC" 25 "PART_NUM_1" 26 "PART_NUM_2" 27 "PART_NUM_3" 255 "END_FC";
VAL_ 1310 FC_infoBuildType 0 "UNKNOWN_BUILD_FC" 1 "PLATFORM_BUILD_FC" 2 "LOCAL_BUILD_FC" 3 "TRACEABLE_CI_BUILD_FC" 4 "MFG_BUILD_FC";
VAL_ 532 FC_postID 0 "MASTER" 1 "SLAVE" 2 "ID_2" 3 "ID_SNA";
VAL_ 532 FC_statusCode 0 "NOTREADY_SNA" 1 "READY" 2 "UPDATE_IN_PROGRESS" 3 "UNUSED_3" 4 "WAIT_POST_READY_TO_CHARGE" 5 "INT_ISOACTIVE" 6 "EXT_ISOACTIVE" 7 "POST_OUT_OF_SERVICE" 13 "NOTCOMPATIBLE" 14 "MALFUNCTION" 15 "NODATA";
VAL_ 532 FC_type 0 "SUPERCHARGER" 1 "CHADEMO" 2 "GB" 3 "CC_EVSE" 4 "COMBO" 5 "MC_EVSE" 6 "OTHER" 7 "SNA";
VAL_ 533 FC_externalIsolationResistance 255 "SNA";
VAL_ 535 FC_status3DataSelect 0 "Mux0";
VAL_ 535 FC_class 0 "SNA" 1 "SUPERCHARGER" 2 "URBANCHARGER";
VAL_ 535 FC_brand 0 "SNA" 1 "TESLA";
VAL_ 535 FC_coolingType 0 "SNA" 1 "CONVECTION" 2 "LIQUID";
VAL_ 535 FC_uiStopType 0 "SNA" 1 "TOGGLE" 2 "MOMENTARY";
VAL_ 273 GTW_12V0_AUDIO_FILT 16383 "SNA";
VAL_ 273 GTW_12V0_FILT 16383 "SNA";
VAL_ 273 GTW_WLAN_ANT_DET0 4095 "SNA";
VAL_ 273 GTW_WLAN_ANT_DET1 4095 "SNA";
VAL_ 274 GTW_1V1_ETH 4095 "SNA";
VAL_ 274 GTW_1V5_ETH 4095 "SNA";
VAL_ 274 GTW_3V3_ETH 4095 "SNA";
VAL_ 274 GTW_3V3_SW 4095 "SNA";
VAL_ 274 GTW_5V0_SW 4095 "SNA";
VAL_ 275 GTW_12V0_DISP 16383 "SNA";
VAL_ 275 GTW_1V1_FPD 4095 "SNA";
VAL_ 275 GTW_1V8_GSM 4095 "SNA";
VAL_ 275 GTW_GSM_MDM_VNDR 4095 "SNA";
VAL_ 276 GTW_1V2_CSI 4095 "SNA";
VAL_ 276 GTW_1V8_VID 4095 "SNA";
VAL_ 276 GTW_1V8_VIO 4095 "SNA";
VAL_ 276 GTW_3V3_BMP 4095 "SNA";
VAL_ 276 GTW_GSM_BRD_REV 4095 "SNA";
VAL_ 62 GTW_matrixIndex 0 "AlertMatrix0" 1 "AlertMatrix1";
VAL_ 904 GTW_CH_faultConfinement 0 "ERROR_ACTIVE" 1 "ERROR_PASSIVE" 2 "BUS_OFF";
VAL_ 904 GTW_PARTY_faultConfinement 0 "ERROR_ACTIVE" 1 "ERROR_PASSIVE" 2 "BUS_OFF";
VAL_ 904 GTW_VEH_faultConfinement 0 "ERROR_ACTIVE" 1 "ERROR_PASSIVE" 2 "BUS_OFF";
VAL_ 2047 GTW_airSuspension 0 "NONE" 1 "TESLA_STANDARD";
VAL_ 2047 GTW_epasType 0 "MANDO_VGR69_GEN3";
VAL_ 2047 GTW_drivetrainType 0 "RWD" 1 "AWD";
VAL_ 2047 GTW_rightHandDrive 0 "LEFT" 1 "RIGHT";
VAL_ 2047 GTW_heatedWipers 0 "FALSE" 1 "TRUE";
VAL_ 2047 GTW_frontSeatHeaters 0 "NONE" 1 "KONGSBERG_LOW_POWER";
VAL_ 2047 GTW_rearSeatHeaters 0 "NONE" 1 "KONGSBERG_LOW_POWER";
VAL_ 2047 GTW_packEnergy 0 "50_KWH" 1 "74_KWH";
VAL_ 2047 GTW_brakeHWType 0 "MANDO_43MOC" 1 "BREMBO_44MOC";
VAL_ 2047 GTW_homelinkType 0 "NONE" 1 "HOMELINK_V_OPT_2";
VAL_ 2047 GTW_vdcType 0 "BOSCH_VDC" 1 "TESLA_VDC";
VAL_ 2047 GTW_xcpIbst 0 "FALSE" 1 "TRUE";
VAL_ 2047 GTW_xcpESP 0 "FALSE" 1 "TRUE";
VAL_ 2047 GTW_memoryMirrors 0 "NOT_INSTALLED" 1 "SMR";
VAL_ 2047 GTW_powerSteeringColumn 0 "NOT_INSTALLED" 1 "TK";
VAL_ 2047 GTW_interiorLighting 0 "BASE" 1 "PREMIUM";
VAL_ 2047 GTW_frontFogLamps 0 "NOT_INSTALLED" 1 "INSTALLED";
VAL_ 2047 GTW_headlamps 0 "BASE" 1 "PREMIUM";
VAL_ 2047 GTW_audioType 0 "BASE" 1 "PREMIUM";
VAL_ 2047 GTW_lumbarECUType 0 "NONE" 1 "ALFMEIER";
VAL_ 2047 GTW_ibstWakeType 0 "NONE" 1 "WAKE_PIN_20";
VAL_ 2047 GTW_frontSeatType 0 "BASE" 1 "PREMIUM";
VAL_ 2047 GTW_auxParkLamps 0 "NOT_INSTALLED" 1 "INSTALLED";
VAL_ 2047 GTW_pedestrianWarningSound 0 "NONE" 1 "SPEAKER";
VAL_ 2047 GTW_hvacQuietSnorkelType 0 "DEFAULT" 1 "QUIET_V1";
VAL_ 2047 GTW_hvacPanelVaneType 0 "PARALLEL_V1" 1 "CONVERGENT_V1";
VAL_ 2047 GTW_CabinBlowerCtrlType 0 "LV8907" 1 "TMS320F28027F";
VAL_ 2047 GTW_performancePackage 0 "BASE" 1 "PERFORMANCE";
VAL_ 2047 GTW_eBuckConfig 0 "NONE" 1 "DEV_BUCK";
VAL_ 2047 GTW_windshieldType 0 "SEKISUI_ACOUSTIC" 1 "EASTMAN_ACOUSTIC";
VAL_ 2047 GTW_activeHighBeam 0 "NOT_ACTIVE" 1 "ACTIVE";
VAL_ 2047 GTW_airbagCutoffSwitch 0 "DISABLED" 1 "ENABLED";
VAL_ 2047 GTW_intrusionSensorType 0 "NOT_INSTALLED" 1 "VODAFONE";
VAL_ 2047 GTW_spoilerType 0 "NOT_INSTALLED" 1 "PASSIVE";
VAL_ 2047 GTW_rearGlassType 0 "NX" 1 "TSA5_NOPET";
VAL_ 2047 GTW_rearFogLamps 0 "NOT_INSTALLED" 1 "INSTALLED";
VAL_ 2047 GTW_roofType 0 "METAL" 1 "FIXED_GLASS" 2 "PANORAMIC";
VAL_ 2047 GTW_autopilot 0 "NONE" 1 "HIGHWAY" 2 "ENHANCED" 3 "SELF_DRIVING";
VAL_ 2047 GTW_superchargingAccess 0 "NOT_ALLOWED" 1 "ALLOWED" 2 "PAY_AS_YOU_GO";
VAL_ 2047 GTW_wheelType 0 "PINWHEEL_18" 1 "STILETTO_19" 2 "STILETTO_20";
VAL_ 2047 GTW_exteriorColor 0 "RED_MULTICOAT" 1 "SOLID_BLACK" 2 "SILVER_METALLIC" 3 "MIDNIGHT_SILVER" 5 "DEEP_BLUE" 6 "PEARL_WHITE";
VAL_ 2047 GTW_numberHVILNodes 0 "0" 1 "1" 2 "2" 3 "3" 4 "4" 5 "5";
VAL_ 2047 GTW_restraintsHardwareType 21 "NA" 22 "EUROW_ECALL" 23 "EUROW_NO_ECALL";
VAL_ 1080 GTW_ethWakeUpReason 0 "NONE" 1 "RESET" 2 "GSM_RI" 3 "CH_CAN" 4 "ETH_CAN" 5 "VEH_CAN" 6 "VCFRONT" 7 "RTC_ALARM" 8 "UI_SCHEDULED";
VAL_ 2033 GTW_hrlIndex 1 "Mux1" 2 "Mux2";
VAL_ 2033 GTW_hrlState 0 "DISABLED" 1 "ENABLED";
VAL_ 2033 GTW_hrlTriggerType 0 "UDPAPI" 1 "EVENT" 15 "NONE";
VAL_ 2033 GTW_hrlTriggerBus 0 "VEH" 1 "PARTY" 2 "CH" 3 "ETH" 4 "VIRT";
VAL_ 60 GTW_infoIndex 0 "DEPRECATED_0" 1 "DEPRECATED_1" 2 "DEPRECATED_2" 3 "DEPRECATED_3" 4 "DEPRECATED_4" 5 "DEPRECATED_5" 6 "DEPRECATED_6" 7 "DEPRECATED_7" 8 "DEPRECATED_8" 9 "DEPRECATED_9" 10 "BUILD_HWID_COMPONENTID" 11 "PCBAID_ASSYID_USAGEID" 13 "APP_CRC" 14 "BOOTLOADER_SVN" 15 "BOOTLOADER_CRC" 16 "SUBCOMPONENT" 17 "APP_GITHASH" 18 "BOOTLOADER_GITHASH" 19 "VERSION_DEPRECATED" 20 "UDS_PROTOCOL_BOOTCRC" 22 "VARIANTCRC" 25 "PACKAGE_PN_1_7" 26 "PACKAGE_PN_8_14" 27 "PACKAGE_PN_15_20" 29 "PACKAGE_SN_1_7" 30 "PACKAGE_SN_8_14" 31 "SUBCOMPONENT_GITHASH" 255 "END";
VAL_ 60 GTW_buildType 0 "UNKNOWN_BUILD" 1 "PLATFORM_BUILD" 2 "LOCAL_BUILD" 3 "TRACEABLE_CI_BUILD" 4 "MFG_BUILD";
VAL_ 60 GTW_platformType 0 "UNKNOWN" 3 "MODEL3" 255 "END";
VAL_ 840 GTW_vehicleVersionMatchStatus 0 "NOT_CALCULATED_YET" 1 "MISMATCHED" 2 "MATCHED";
VAL_ 872 GTW_offboardUpdateState 0 "WAITING_FOR_CONNECTION" 1 "WAIT_UPDATE_TRIGGER" 2 "PREPARING" 3 "RUNNING" 4 "CONFIRM_UPDATE" 5 "LATCH_RESULT";
VAL_ 872 GTW_offboardUpdateStatus 0 "OK" 1 "FILE_OPEN_ERROR" 2 "UNPLUGGED" 3 "UDS_FAILED" 4 "SUCCESS" 5 "LOST_DIGITAL_COMMS" 6 "NOT_NEEDED" 7 "APPTRIPLE_MISMATCH";
VAL_ 1112 GTW_nmKeepAwakeReason 0 "NONE_SNA" 15 "TBD";
VAL_ 1112 GTW_nmWakeUpReason 0 "NONE" 1 "RESET" 2 "GSM_RI" 3 "CH_CAN" 4 "ETH_CAN" 5 "VEH_CAN" 6 "VCFRONT" 7 "RTC_ALARM" 8 "UI_SCHEDULED";
VAL_ 522 HVP_fcContNegativeState 0 "SNA" 1 "OPEN" 2 "PRECHARGE" 3 "BLOCKED" 4 "PULLED_IN" 5 "OPENING" 6 "ECONOMIZED" 7 "WELDED";
VAL_ 522 HVP_fcContPositiveState 0 "SNA" 1 "OPEN" 2 "PRECHARGE" 3 "BLOCKED" 4 "PULLED_IN" 5 "OPENING" 6 "ECONOMIZED" 7 "WELDED";
VAL_ 522 HVP_fcContactorSetState 0 "SNA" 1 "OPEN" 2 "CLOSING" 3 "BLOCKED" 4 "OPENING" 5 "CLOSED" 6 "PARTIAL_WELD" 7 "WELDED" 8 "POSITIVE_CLOSED" 9 "NEGATIVE_CLOSED";
VAL_ 522 HVP_fcCtrsRequestStatus 0 "NOT_ACTIVE" 1 "ACTIVE" 2 "COMPLETED";
VAL_ 522 HVP_hvilStatus 0 "UNKNOWN" 1 "STATUS_OK" 2 "CURRENT_SOURCE_FAULT" 3 "INTERNAL_OPEN_FAULT" 4 "VEHICLE_OPEN_FAULT" 5 "PENTHOUSE_LID_OPEN_FAULT" 6 "UNKNOWN_LOCATION_OPEN_FAULT" 7 "VEHICLE_NODE_FAULT" 8 "NO_12V_SUPPLY";
VAL_ 522 HVP_packContNegativeState 0 "SNA" 1 "OPEN" 2 "PRECHARGE" 3 "BLOCKED" 4 "PULLED_IN" 5 "OPENING" 6 "ECONOMIZED" 7 "WELDED";
VAL_ 522 HVP_packContPositiveState 0 "SNA" 1 "OPEN" 2 "PRECHARGE" 3 "BLOCKED" 4 "PULLED_IN" 5 "OPENING" 6 "ECONOMIZED" 7 "WELDED";
VAL_ 522 HVP_packContactorSetState 0 "SNA" 1 "OPEN" 2 "CLOSING" 3 "BLOCKED" 4 "OPENING" 5 "CLOSED" 6 "PARTIAL_WELD" 7 "WELDED" 8 "POSITIVE_CLOSED" 9 "NEGATIVE_CLOSED";
VAL_ 522 HVP_packCtrsRequestStatus 0 "NOT_ACTIVE" 1 "ACTIVE" 2 "COMPLETED";
VAL_ 1962 HVP_debugMessageMultiplexer 0 "Mux0" 1 "Mux1" 2 "Mux2" 3 "Mux3" 4 "Mux4" 5 "Mux5" 6 "Mux6";
VAL_ 1962 HVP_shuntBarTempDbg 32768 "SHUNT_TEMPERATURE_SNA";
VAL_ 1962 HVP_shuntAsicTempDbg 32768 "SHUNT_TEMPERATURE_SNA";
VAL_ 784 HVP_infoIndex 0 "DEPRECATED_0" 1 "DEPRECATED_1" 2 "DEPRECATED_2" 3 "DEPRECATED_3" 4 "DEPRECATED_4" 5 "DEPRECATED_5" 6 "DEPRECATED_6" 7 "DEPRECATED_7" 8 "DEPRECATED_8" 9 "DEPRECATED_9" 10 "BUILD_HWID_COMPONENTID" 11 "PCBAID_ASSYID_USAGEID" 13 "APP_CRC" 14 "BOOTLOADER_SVN" 15 "BOOTLOADER_CRC" 16 "SUBCOMPONENT" 17 "APP_GITHASH" 18 "BOOTLOADER_GITHASH" 19 "VERSION_DEPRECATED" 20 "UDS_PROTOCOL_BOOTCRC" 22 "VARIANTCRC" 25 "PACKAGE_PN_1_7" 26 "PACKAGE_PN_8_14" 27 "PACKAGE_PN_15_20" 29 "PACKAGE_SN_1_7" 30 "PACKAGE_SN_8_14" 31 "SUBCOMPONENT_GITHASH" 255 "END";
VAL_ 784 HVP_buildType 0 "UNKNOWN_BUILD" 1 "PLATFORM_BUILD" 2 "LOCAL_BUILD" 3 "TRACEABLE_CI_BUILD" 4 "MFG_BUILD";
VAL_ 1898 HVP_ecuLogUploadRequest 0 "NONE" 1 "1" 2 "2" 3 "3";
VAL_ 1898 HVP_vehicleDebugMultiplexer 0 "Mux0" 1 "Mux1" 2 "Mux2";
VAL_ 861 IBST_matrixIndex 0 "AlertMatrix0" 1 "AlertMatrix1" 2 "AlertMatrix2";
VAL_ 813 IBST_infoIndex 0 "DEPRECATED_0" 1 "DEPRECATED_1" 2 "DEPRECATED_2" 3 "DEPRECATED_3" 4 "DEPRECATED_4" 5 "DEPRECATED_5" 6 "DEPRECATED_6" 7 "DEPRECATED_7" 8 "DEPRECATED_8" 9 "DEPRECATED_9" 10 "BUILD_HWID_COMPONENTID" 11 "PCBAID_ASSYID_USAGEID" 13 "APP_CRC" 14 "BOOTLOADER_SVN" 15 "BOOTLOADER_CRC" 16 "SUBCOMPONENT" 17 "APP_GITHASH" 18 "BOOTLOADER_GITHASH" 19 "VERSION_DEPRECATED" 20 "UDS_PROTOCOL_BOOTCRC" 22 "VARIANTCRC" 25 "PACKAGE_PN_1_7" 26 "PACKAGE_PN_8_14" 27 "PACKAGE_PN_15_20" 29 "PACKAGE_SN_1_7" 30 "PACKAGE_SN_8_14" 31 "SUBCOMPONENT_GITHASH" 255 "END";
VAL_ 813 IBST_infoBuildType 0 "UNKNOWN_BUILD" 1 "PLATFORM_BUILD" 2 "LOCAL_BUILD" 3 "TRACEABLE_CI_BUILD" 4 "MFG_BUILD";
VAL_ 925 IBST_driverBrakeApply 0 "NOT_INIT_OR_OFF" 1 "BRAKES_NOT_APPLIED" 2 "DRIVER_APPLYING_BRAKES" 3 "FAULT";
VAL_ 925 IBST_iBoosterStatus 0 "OFF" 1 "INIT" 2 "FAILURE" 3 "DIAGNOSTIC" 4 "ACTIVE_GOOD_CHECK" 5 "READY" 6 "ACTUATION";
VAL_ 917 OCS1P_matrixIndex 2 "OCS1P_AlertMatrix2";
